VERSION ""

NS_ :

BS_:

BU_: FLC2 DACU

BO_ 788 FLCObject04_Vic2: 48 FLC2
 SG_ FLCObject04_LatVel : 277|13@1+ (0.032,-80) [-80|182.112] "m_per_s"  VCM
 SG_ FLCObject04_LatVelVar : 32|8@1+ (0.1,0) [0|25.5] "NotApplicable"  VCM
 SG_ FLCObject04_CoastIndex : 328|5@1+ (1,0) [0|31] "NotApplicable"  VCM
 SG_ FLCObject04_LifeTime : 64|16@1+ (0.1,0) [0|6553.5] "s"  VCM
 SG_ FLCObject04_DistFarCorner : 176|12@1+ (0.05,0) [0|204.75] "m"  VCM
 SG_ FLCObject04_TurnIndication : 333|3@1+ (1,0) [0|0] ""  VCM
 SG_ FLCObject04_AnglLeftCorner : 209|10@1+ (0.005,-1.57) [-1.57|3.545] "rad"  VCM
 SG_ FLCObject04_CRC : 0|16@1+ (1,0) [0|65535] "NotApplicable"  VCM
 SG_ FLCObject04_LatPos : 264|13@1+ (0.05,-180) [-180|229.55] "m"  VCM
 SG_ FLCObject04_DstRightVar : 80|8@1+ (0.4,0) [0|102] "NotApplicable"  VCM
 SG_ FLCObject04_Height : 96|8@1+ (0.02,0) [0|5.1] "m"  VCM
 SG_ FLCObject04_LongVel : 303|13@1+ (0.032,-80) [-80|182.112] "m_per_s"  VCM
 SG_ FLCObject04_ExistConf : 257|7@1+ (0.01,0) [0|1.27] "NotApplicable"  VCM
 SG_ FLCObject04_DstFarVar : 24|8@1+ (0.4,0) [0|102] "NotApplicable"  VCM
 SG_ FLCObject04_ObjClass : 316|4@1+ (1,0) [0|0] ""  VCM
 SG_ FLCObject04_AngLeftVar : 120|8@1+ (1E-005,0) [0|0.00255] "NotApplicable"  VCM
 SG_ FLCObject04_ScaleChange : 219|10@1+ (0.002,0) [0|2.046] "NotApplicable"  VCM
 SG_ FLCObject04_AnglRightCorner : 199|10@1+ (0.005,-1.57) [-1.57|3.545] "rad"  VCM
 SG_ FLCObject04_LongPosVar : 144|8@1+ (0.4,0) [0|102] "NotApplicable"  VCM
 SG_ FLCObject04_LongAcc : 239|9@1+ (0.08,-20) [-20|20.88] "m_per_s_squared"  VCM
 SG_ FLCObject04_ObjDynClass : 326|2@1+ (1,0) [0|0] ""  VCM
 SG_ FLCObject04_Counter : 16|8@1+ (1,0) [0|255] "Count"  VCM
 SG_ FLCObject04_ObjID : 320|6@1+ (1,0) [0|63] "NotApplicable"  VCM
 SG_ FLCObject04_TrackStatus : 339|3@1+ (1,0) [0|0] ""  VCM
 SG_ FLCObject04_AngRightVar : 136|8@1+ (1E-005,0) [0|0.00255] "NotApplicable"  VCM
 SG_ FLCObject04_DistLeftCorner : 152|12@1+ (0.05,0) [0|204.75] "m"  VCM
 SG_ FLCObject04_Heading : 188|11@1+ (0.005818,-4.71) [-4.71|7.199446] "rad"  VCM
 SG_ FLCObject04_BrakeLight : 345|3@1+ (1,0) [0|0] ""  VCM
 SG_ FLCObject04_DistRightCorner : 164|12@1+ (0.05,0) [0|204.75] "m"  VCM
 SG_ FLCObject04_AnglFarCorner : 229|10@1+ (0.005,-1.57) [-1.57|3.545] "rad"  VCM
 SG_ FLCObject04_AngFarVar : 128|8@1+ (1E-005,0) [0|0.00255] "NotApplicable"  VCM
 SG_ FLCObject04_DstLeftVar : 112|8@1+ (0.4,0) [0|102] "NotApplicable"  VCM
 SG_ FLCObject04_LatAcc : 248|9@1+ (0.08,-20) [-20|20.88] "m_per_s_squared"  VCM
 SG_ FLCObject04_TargetToLine : 342|3@1+ (1,0) [0|0] ""  VCM
 SG_ FLCObject04_LongVelVar : 88|8@1+ (0.4,0) [0|102] "NotApplicable"  VCM
 SG_ FLCObject04_LatPosVar : 40|8@1+ (0.1,0) [0|25.5] "NotApplicable"  VCM
 SG_ FLCObject04_TimeStamp : 48|16@1+ (0.1,0) [0|6553.5] "ms"  VCM
 SG_ FLCObject04_LongPos : 290|13@1+ (0.05,-180) [-180|229.55] "m"  VCM
 SG_ FLCObject04_ReliabilityConf : 336|3@1+ (1,0) [0|0] ""  VCM
 SG_ FLCObject04_HeadingVar : 104|8@1+ (0.1,0) [0|25.5] "NotApplicable"  VCM

BO_ 787 FLCObject03_Vic2: 48 FLC2
 SG_ FLCObject03_Height : 96|8@1+ (0.02,0) [0|5.1] "m"  VCM
 SG_ FLCObject03_LatAcc : 248|9@1+ (0.08,-20) [-20|20.88] "m_per_s_squared"  VCM
 SG_ FLCObject03_LatVelVar : 32|8@1+ (0.1,0) [0|25.5] "NotApplicable"  VCM
 SG_ FLCObject03_TrackStatus : 339|3@1+ (1,0) [0|0] ""  VCM
 SG_ FLCObject03_LifeTime : 64|16@1+ (0.1,0) [0|6553.5] "s"  VCM
 SG_ FLCObject03_AnglFarCorner : 229|10@1+ (0.005,-1.57) [-1.57|3.545] "rad"  VCM
 SG_ FLCObject03_LongAcc : 239|9@1+ (0.08,-20) [-20|20.88] "m_per_s_squared"  VCM
 SG_ FLCObject03_Heading : 188|11@1+ (0.005818,-4.71) [-4.71|7.199446] "rad"  VCM
 SG_ FLCObject03_AngFarVar : 128|8@1+ (1E-005,0) [0|0.00255] "NotApplicable"  VCM
 SG_ FLCObject03_LongPosVar : 144|8@1+ (0.4,0) [0|102] "NotApplicable"  VCM
 SG_ FLCObject03_LatPos : 264|13@1+ (0.05,-180) [-180|229.55] "m"  VCM
 SG_ FLCObject03_ScaleChange : 219|10@1+ (0.002,0) [0|2.046] "NotApplicable"  VCM
 SG_ FLCObject03_LongVelVar : 88|8@1+ (0.4,0) [0|102] "NotApplicable"  VCM
 SG_ FLCObject03_LongVel : 303|13@1+ (0.032,-80) [-80|182.112] "m_per_s"  VCM
 SG_ FLCObject03_DstFarVar : 24|8@1+ (0.4,0) [0|102] "NotApplicable"  VCM
 SG_ FLCObject03_TargetToLine : 342|3@1+ (1,0) [0|0] ""  VCM
 SG_ FLCObject03_CoastIndex : 328|5@1+ (1,0) [0|31] "NotApplicable"  VCM
 SG_ FLCObject03_DstRightVar : 80|8@1+ (0.4,0) [0|102] "NotApplicable"  VCM
 SG_ FLCObject03_ExistConf : 257|7@1+ (0.01,0) [0|1.27] "NotApplicable"  VCM
 SG_ FLCObject03_LongPos : 290|13@1+ (0.05,-180) [-180|229.55] "m"  VCM
 SG_ FLCObject03_AnglRightCorner : 199|10@1+ (0.005,-1.57) [-1.57|3.545] "rad"  VCM
 SG_ FLCObject03_LatVel : 277|13@1+ (0.032,-80) [-80|182.112] "m_per_s"  VCM
 SG_ FLCObject03_ObjClass : 316|4@1+ (1,0) [0|0] ""  VCM
 SG_ FLCObject03_TimeStamp : 48|16@1+ (0.1,0) [0|6553.5] "ms"  VCM
 SG_ FLCObject03_ObjDynClass : 326|2@1+ (1,0) [0|0] ""  VCM
 SG_ FLCObject03_CRC : 0|16@1+ (1,0) [0|65535] "NotApplicable"  VCM
 SG_ FLCObject03_AnglLeftCorner : 209|10@1+ (0.005,-1.57) [-1.57|3.545] "rad"  VCM
 SG_ FLCObject03_ReliabilityConf : 336|3@1+ (1,0) [0|0] ""  VCM
 SG_ FLCObject03_DistLeftCorner : 152|12@1+ (0.05,0) [0|204.75] "m"  VCM
 SG_ FLCObject03_DstLeftVar : 112|8@1+ (0.4,0) [0|102] "NotApplicable"  VCM
 SG_ FLCObject03_DistFarCorner : 176|12@1+ (0.05,0) [0|204.75] "m"  VCM
 SG_ FLCObject03_TurnIndication : 333|3@1+ (1,0) [0|0] ""  VCM
 SG_ FLCObject03_LatPosVar : 40|8@1+ (0.1,0) [0|25.5] "NotApplicable"  VCM
 SG_ FLCObject03_DistRightCorner : 164|12@1+ (0.05,0) [0|204.75] "m"  VCM
 SG_ FLCObject03_ObjID : 320|6@1+ (1,0) [0|63] "NotApplicable"  VCM
 SG_ FLCObject03_AngLeftVar : 120|8@1+ (1E-005,0) [0|0.00255] "NotApplicable"  VCM
 SG_ FLCObject03_BrakeLight : 345|3@1+ (1,0) [0|0] ""  VCM
 SG_ FLCObject03_HeadingVar : 104|8@1+ (0.1,0) [0|25.5] "NotApplicable"  VCM
 SG_ FLCObject03_Counter : 16|8@1+ (1,0) [0|255] "Count"  VCM
 SG_ FLCObject03_AngRightVar : 136|8@1+ (1E-005,0) [0|0.00255] "NotApplicable"  VCM

BO_ 786 FLCObject02_Vic2: 48 FLC2
 SG_ FLCObject02_ScaleChange : 219|10@1+ (0.002,0) [0|2.046] "NotApplicable"  VCM
 SG_ FLCObject02_Height : 96|8@1+ (0.02,0) [0|5.1] "m"  VCM
 SG_ FLCObject02_AnglRightCorner : 199|10@1+ (0.005,-1.57) [-1.57|3.545] "rad"  VCM
 SG_ FLCObject02_AnglFarCorner : 229|10@1+ (0.005,-1.57) [-1.57|3.545] "rad"  VCM
 SG_ FLCObject02_DistRightCorner : 164|12@1+ (0.05,0) [0|204.75] "m"  VCM
 SG_ FLCObject02_LongAcc : 239|9@1+ (0.08,-20) [-20|20.88] "m_per_s_squared"  VCM
 SG_ FLCObject02_AngRightVar : 136|8@1+ (1E-005,0) [0|0.00255] "NotApplicable"  VCM
 SG_ FLCObject02_CRC : 0|16@1+ (1,0) [0|65535] "NotApplicable"  VCM
 SG_ FLCObject02_LatAcc : 248|9@1+ (0.08,-20) [-20|20.88] "m_per_s_squared"  VCM
 SG_ FLCObject02_TrackStatus : 339|3@1+ (1,0) [0|0] ""  VCM
 SG_ FLCObject02_Heading : 188|11@1+ (0.005818,-4.71) [-4.71|7.199446] "rad"  VCM
 SG_ FLCObject02_AnglLeftCorner : 209|10@1+ (0.005,-1.57) [-1.57|3.545] "rad"  VCM
 SG_ FLCObject02_LongVelVar : 88|8@1+ (0.4,0) [0|102] "NotApplicable"  VCM
 SG_ FLCObject02_LatPos : 264|13@1+ (0.05,-180) [-180|229.55] "m"  VCM
 SG_ FLCObject02_LongPosVar : 144|8@1+ (0.4,0) [0|102] "NotApplicable"  VCM
 SG_ FLCObject02_LatVelVar : 32|8@1+ (0.1,0) [0|25.5] "NotApplicable"  VCM
 SG_ FLCObject02_LongVel : 303|13@1+ (0.032,-80) [-80|182.112] "m_per_s"  VCM
 SG_ FLCObject02_ObjDynClass : 326|2@1+ (1,0) [0|0] ""  VCM
 SG_ FLCObject02_TimeStamp : 48|16@1+ (0.1,0) [0|6553.5] "ms"  VCM
 SG_ FLCObject02_DistFarCorner : 176|12@1+ (0.05,0) [0|204.75] "m"  VCM
 SG_ FLCObject02_DstFarVar : 24|8@1+ (0.4,0) [0|102] "NotApplicable"  VCM
 SG_ FLCObject02_LifeTime : 64|16@1+ (0.1,0) [0|6553.5] "s"  VCM
 SG_ FLCObject02_LatVel : 277|13@1+ (0.032,-80) [-80|182.112] "m_per_s"  VCM
 SG_ FLCObject02_ObjID : 320|6@1+ (1,0) [0|63] "NotApplicable"  VCM
 SG_ FLCObject02_ExistConf : 257|7@1+ (0.01,0) [0|1.27] "NotApplicable"  VCM
 SG_ FLCObject02_DstRightVar : 80|8@1+ (0.4,0) [0|102] "NotApplicable"  VCM
 SG_ FLCObject02_ReliabilityConf : 336|3@1+ (1,0) [0|0] ""  VCM
 SG_ FLCObject02_DistLeftCorner : 152|12@1+ (0.05,0) [0|204.75] "m"  VCM
 SG_ FLCObject02_HeadingVar : 104|8@1+ (0.1,0) [0|25.5] "NotApplicable"  VCM
 SG_ FLCObject02_TurnIndication : 333|3@1+ (1,0) [0|0] ""  VCM
 SG_ FLCObject02_ObjClass : 316|4@1+ (1,0) [0|0] ""  VCM
 SG_ FLCObject02_LongPos : 290|13@1+ (0.05,-180) [-180|229.55] "m"  VCM
 SG_ FLCObject02_DstLeftVar : 112|8@1+ (0.4,0) [0|102] "NotApplicable"  VCM
 SG_ FLCObject02_AngLeftVar : 120|8@1+ (1E-005,0) [0|0.00255] "NotApplicable"  VCM
 SG_ FLCObject02_BrakeLight : 345|3@1+ (1,0) [0|0] ""  VCM
 SG_ FLCObject02_LatPosVar : 40|8@1+ (0.1,0) [0|25.5] "NotApplicable"  VCM
 SG_ FLCObject02_CoastIndex : 328|5@1+ (1,0) [0|31] "NotApplicable"  VCM
 SG_ FLCObject02_Counter : 16|8@1+ (1,0) [0|255] "Count"  VCM
 SG_ FLCObject02_TargetToLine : 342|3@1+ (1,0) [0|0] ""  VCM
 SG_ FLCObject02_AngFarVar : 128|8@1+ (1E-005,0) [0|0.00255] "NotApplicable"  VCM

BO_ 785 FLCObject01_Vic2: 48 FLC2
 SG_ FLCObject01_TimeStamp : 48|16@1+ (0.1,0) [0|6553.5] "ms"  VCM
 SG_ FLCObject01_CRC : 0|16@1+ (1,0) [0|65535] "NotApplicable"  VCM
 SG_ FLCObject01_LongVelVar : 88|8@1+ (0.4,0) [0|102] "NotApplicable"  VCM
 SG_ FLCObject01_ObjDynClass : 326|2@1+ (1,0) [0|0] ""  VCM
 SG_ FLCObject01_ScaleChange : 219|10@1+ (0.002,0) [0|2.046] "NotApplicable"  VCM
 SG_ FLCObject01_AnglRightCorner : 199|10@1+ (0.005,-1.57) [-1.57|3.545] "rad"  VCM
 SG_ FLCObject01_ReliabilityConf : 336|3@1+ (1,0) [0|0] ""  VCM
 SG_ FLCObject01_LongAcc : 239|9@1+ (0.08,-20) [-20|20.88] "m_per_s_squared"  VCM
 SG_ FLCObject01_DistLeftCorner : 152|12@1+ (0.05,0) [0|204.75] "m"  VCM
 SG_ FLCObject01_BrakeLight : 345|3@1+ (1,0) [0|0] ""  VCM
 SG_ FLCObject01_DstFarVar : 24|8@1+ (0.4,0) [0|102] "NotApplicable"  VCM
 SG_ FLCObject01_LatVel : 277|13@1+ (0.032,-80) [-80|182.112] "m_per_s"  VCM
 SG_ FLCObject01_LatPos : 264|13@1+ (0.05,-180) [-180|229.55] "m"  VCM
 SG_ FLCObject01_LongPosVar : 144|8@1+ (0.4,0) [0|102] "NotApplicable"  VCM
 SG_ FLCObject01_DstLeftVar : 112|8@1+ (0.4,0) [0|102] "NotApplicable"  VCM
 SG_ FLCObject01_LatPosVar : 40|8@1+ (0.1,0) [0|25.5] "NotApplicable"  VCM
 SG_ FLCObject01_ExistConf : 257|7@1+ (0.01,0) [0|1.27] "NotApplicable"  VCM
 SG_ FLCObject01_Counter : 16|8@1+ (1,0) [0|255] "Count"  VCM
 SG_ FLCObject01_ObjClass : 316|4@1+ (1,0) [0|0] ""  VCM
 SG_ FLCObject01_LongVel : 303|13@1+ (0.032,-80) [-80|182.112] "m_per_s"  VCM
 SG_ FLCObject01_Height : 96|8@1+ (0.02,0) [0|5.1] "m"  VCM
 SG_ FLCObject01_LatVelVar : 32|8@1+ (0.1,0) [0|25.5] "NotApplicable"  VCM
 SG_ FLCObject01_AnglFarCorner : 229|10@1+ (0.005,-1.57) [-1.57|3.545] "rad"  VCM
 SG_ FLCObject01_Heading : 188|11@1+ (0.005818,-4.71) [-4.71|7.199446] "rad"  VCM
 SG_ FLCObject01_LatAcc : 248|9@1+ (0.08,-20) [-20|20.88] "m_per_s_squared"  VCM
 SG_ FLCObject01_LifeTime : 64|16@1+ (0.1,0) [0|6553.5] "s"  VCM
 SG_ FLCObject01_HeadingVar : 104|8@1+ (0.1,0) [0|25.5] "NotApplicable"  VCM
 SG_ FLCObject01_AngLeftVar : 120|8@1+ (1E-005,0) [0|0.00255] "NotApplicable"  VCM
 SG_ FLCObject01_AngFarVar : 128|8@1+ (1E-005,0) [0|0.00255] "NotApplicable"  VCM
 SG_ FLCObject01_CoastIndex : 328|5@1+ (1,0) [0|31] "NotApplicable"  VCM
 SG_ FLCObject01_DistRightCorner : 164|12@1+ (0.05,0) [0|204.75] "m"  VCM
 SG_ FLCObject01_TrackStatus : 339|3@1+ (1,0) [0|0] ""  VCM
 SG_ FLCObject01_LongPos : 290|13@1+ (0.05,-180) [-180|229.55] "m"  VCM
 SG_ FLCObject01_ObjID : 320|6@1+ (1,0) [0|63] "NotApplicable"  VCM
 SG_ FLCObject01_DstRightVar : 80|8@1+ (0.4,0) [0|102] "NotApplicable"  VCM
 SG_ FLCObject01_DistFarCorner : 176|12@1+ (0.05,0) [0|204.75] "m"  VCM
 SG_ FLCObject01_TargetToLine : 342|3@1+ (1,0) [0|0] ""  VCM
 SG_ FLCObject01_TurnIndication : 333|3@1+ (1,0) [0|0] ""  VCM
 SG_ FLCObject01_AngRightVar : 136|8@1+ (1E-005,0) [0|0.00255] "NotApplicable"  VCM
 SG_ FLCObject01_AnglLeftCorner : 209|10@1+ (0.005,-1.57) [-1.57|3.545] "rad"  VCM

BO_ 784 FLCObject00_Vic2: 48 FLC2
 SG_ FLCObject00_LifeTime : 64|16@1+ (0.1,0) [0|6553.5] "s"  VCM
 SG_ FLCObject00_BrakeLight : 345|3@1+ (1,0) [0|0] ""  VCM
 SG_ FLCObject00_AnglLeftCorner : 209|10@1+ (0.005,-1.57) [-1.57|3.545] "rad"  VCM
 SG_ FLCObject00_DistRightCorner : 164|12@1+ (0.05,0) [0|204.75] "m"  VCM
 SG_ FLCObject00_LatPos : 264|13@1+ (0.05,-180) [-180|229.55] "m"  VCM
 SG_ FLCObject00_TimeStamp : 48|16@1+ (0.1,0) [0|6553.5] "ms"  VCM
 SG_ FLCObject00_LatAcc : 248|9@1+ (0.08,-20) [-20|20.88] "m_per_s_squared"  VCM
 SG_ FLCObject00_LatVel : 277|13@1+ (0.032,-80) [-80|182.112] "m_per_s"  VCM
 SG_ FLCObject00_ExistConf : 257|7@1+ (0.01,0) [0|1.27] "NotApplicable"  VCM
 SG_ FLCObject00_AngRightVar : 136|8@1+ (1E-005,0) [0|0.00255] "NotApplicable"  VCM
 SG_ FLCObject00_AnglRightCorner : 199|10@1+ (0.005,-1.57) [-1.57|3.545] "rad"  VCM
 SG_ FLCObject00_LatPosVar : 40|8@1+ (0.1,0) [0|25.5] "NotApplicable"  VCM
 SG_ FLCObject00_DistLeftCorner : 152|12@1+ (0.05,0) [0|204.75] "m"  VCM
 SG_ FLCObject00_CoastIndex : 328|5@1+ (1,0) [0|31] "NotApplicable"  VCM
 SG_ FLCObject00_TrackStatus : 339|3@1+ (1,0) [0|0] ""  VCM
 SG_ FLCObject00_ScaleChange : 219|10@1+ (0.002,0) [0|2.046] "NotApplicable"  VCM
 SG_ FLCObject00_LatVelVar : 32|8@1+ (0.1,0) [0|25.5] "NotApplicable"  VCM
 SG_ FLCObject00_HeadingVar : 104|8@1+ (0.1,0) [0|25.5] "NotApplicable"  VCM
 SG_ FLCObject00_LongPosVar : 144|8@1+ (0.4,0) [0|102] "NotApplicable"  VCM
 SG_ FLCObject00_DstLeftVar : 112|8@1+ (0.4,0) [0|102] "NotApplicable"  VCM
 SG_ FLCObject00_ObjID : 320|6@1+ (1,0) [0|63] "NotApplicable"  VCM
 SG_ FLCObject00_ObjClass : 316|4@1+ (1,0) [0|0] ""  VCM
 SG_ FLCObject00_AnglFarCorner : 229|10@1+ (0.005,-1.57) [-1.57|3.545] "rad"  VCM
 SG_ FLCObject00_DstFarVar : 24|8@1+ (0.4,0) [0|102] "NotApplicable"  VCM
 SG_ FLCObject00_LongVel : 303|13@1+ (0.032,-80) [-80|182.112] "m_per_s"  VCM
 SG_ FLCObject00_LongPos : 290|13@1+ (0.05,-180) [-180|229.55] "m"  VCM
 SG_ FLCObject00_AngLeftVar : 120|8@1+ (1E-005,0) [0|0.00255] "NotApplicable"  VCM
 SG_ FLCObject00_ReliabilityConf : 336|3@1+ (1,0) [0|0] ""  VCM
 SG_ FLCObject00_Counter : 16|8@1+ (1,0) [0|255] "Count"  VCM
 SG_ FLCObject00_ObjDynClass : 326|2@1+ (1,0) [0|0] ""  VCM
 SG_ FLCObject00_TargetToLine : 342|3@1+ (1,0) [0|0] ""  VCM
 SG_ FLCObject00_DstRightVar : 80|8@1+ (0.4,0) [0|102] "NotApplicable"  VCM
 SG_ FLCObject00_TurnIndication : 333|3@1+ (1,0) [0|0] ""  VCM
 SG_ FLCObject00_AngFarVar : 128|8@1+ (1E-005,0) [0|0.00255] "NotApplicable"  VCM
 SG_ FLCObject00_Heading : 188|11@1+ (0.005818,-4.71) [-4.71|7.199446] "rad"  VCM
 SG_ FLCObject00_DistFarCorner : 176|12@1+ (0.05,0) [0|204.75] "m"  VCM
 SG_ FLCObject00_LongAcc : 239|9@1+ (0.08,-20) [-20|20.88] "m_per_s_squared"  VCM
 SG_ FLCObject00_Height : 96|8@1+ (0.02,0) [0|5.1] "m"  VCM
 SG_ FLCObject00_LongVelVar : 88|8@1+ (0.4,0) [0|102] "NotApplicable"  VCM
 SG_ FLCObject00_CRC : 0|16@1+ (1,0) [0|65535] "NotApplicable"  VCM

BO_ 2671964753 DiagUUDTRespMsg1_F2_51_Vic2: 8 FLC2
 SG_ DiagUUDTRespSig_F2_51 : 0|64@1+ (1,0) [0|0] ""  VCM

BO_ 2671834193 DiagRespMsgIntTGW2_F4_51_Vic2: 8 FLC2
 SG_ InternalTesterDiagSig_F4_51 : 0|64@1+ (1,0) [0|0] ""  VCM

BO_ 2671833937 DiagRespMsgIntHMIIOM_F3_51_Vic2: 8 FLC2
 SG_ InternalTesterDiagSig_F3_51 : 0|64@1+ (1,0) [0|0] ""  VCM

BO_ 2671792628 DiagReqMsgIntTGW2_51_F4_Vic2: 8 DACU
 SG_ InternalTesterDiagSig_51_F4 : 0|64@1+ (1,0) [0|0] ""  FLC2

BO_ 2671792627 DiagReqMsgIntHMIIOM_51_F3_Vic2: 8 DACU
 SG_ InternalTesterDiagSig_51_F3 : 0|64@1+ (1,0) [0|0] ""  FLC2

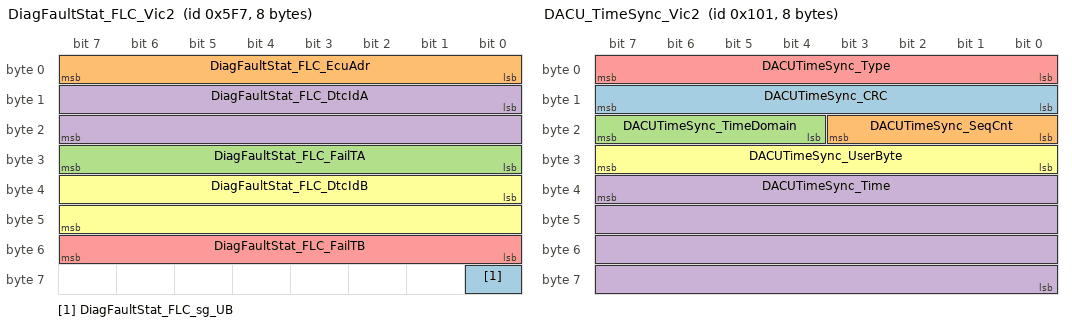
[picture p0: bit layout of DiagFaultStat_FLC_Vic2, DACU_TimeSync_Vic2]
BO_ 1527 DiagFaultStat_FLC_Vic2: 8 FLC2
 SG_ DiagFaultStat_FLC_sg_UB : 56|1@1+ (1,0) [0|0] ""  VCM
 SG_ DiagFaultStat_FLC_EcuAdr : 0|8@1+ (1,0) [0|255] ""  VCM
 SG_ DiagFaultStat_FLC_FailTA : 24|8@1+ (1,0) [0|255] ""  VCM
 SG_ DiagFaultStat_FLC_DtcIdA : 8|16@1+ (1,0) [0|65535] ""  VCM
 SG_ DiagFaultStat_FLC_FailTB : 48|8@1+ (1,0) [0|255] ""  VCM
 SG_ DiagFaultStat_FLC_DtcIdB : 32|16@1+ (1,0) [0|65535] ""  VCM

BO_ 257 DACU_TimeSync_Vic2: 8 DACU
 SG_ DACUTimeSync_CRC : 15|8@0+ (1,0) [0|0] ""  FLC2
 SG_ DACUTimeSync_SeqCnt : 19|4@0+ (1,0) [0|15] "Count"  FLC2
 SG_ DACUTimeSync_TimeDomain : 23|4@0+ (1,0) [0|15] "Count"  FLC2
 SG_ DACUTimeSync_Time : 39|32@0+ (1,0) [0|0] ""  FLC2
 SG_ DACUTimeSync_Type : 7|8@0+ (1,0) [0|0] ""  FLC2
 SG_ DACUTimeSync_UserByte : 31|8@0+ (1,0) [0|0] ""  FLC2

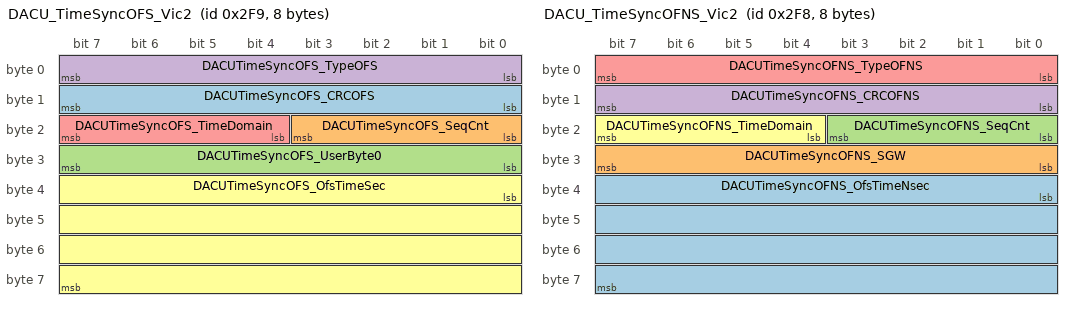
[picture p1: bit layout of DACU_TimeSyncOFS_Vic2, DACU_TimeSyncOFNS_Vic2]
BO_ 761 DACU_TimeSyncOFS_Vic2: 8 DACU
 SG_ DACUTimeSyncOFS_CRCOFS : 8|8@1+ (1,0) [0|0] ""  FLC2
 SG_ DACUTimeSyncOFS_SeqCnt : 16|4@1+ (1,0) [0|15] "Count"  FLC2
 SG_ DACUTimeSyncOFS_UserByte0 : 24|8@1+ (1,0) [0|0] ""  FLC2
 SG_ DACUTimeSyncOFS_TypeOFS : 0|8@1+ (1,0) [0|0] ""  FLC2
 SG_ DACUTimeSyncOFS_TimeDomain : 20|4@1+ (1,16) [16|31] "NotApplicable"  FLC2
 SG_ DACUTimeSyncOFS_OfsTimeSec : 32|32@1+ (1,0) [0|0] ""  FLC2

BO_ 760 DACU_TimeSyncOFNS_Vic2: 8 DACU
 SG_ DACUTimeSyncOFNS_OfsTimeNsec : 32|32@1+ (1,0) [0|0] ""  FLC2
 SG_ DACUTimeSyncOFNS_SGW : 24|8@1+ (1,0) [0|0] ""  FLC2
 SG_ DACUTimeSyncOFNS_SeqCnt : 16|4@1+ (1,0) [0|15] "Count"  FLC2
 SG_ DACUTimeSyncOFNS_CRCOFNS : 8|8@1+ (1,0) [0|0] ""  FLC2
 SG_ DACUTimeSyncOFNS_TypeOFNS : 0|8@1+ (1,0) [0|0] ""  FLC2
 SG_ DACUTimeSyncOFNS_TimeDomain : 20|4@1+ (1,16) [16|31] "NotApplicable"  FLC2

BO_ 281 DACU_ShadowArea_Vic2: 12 DACU
 SG_ ShadowArea_LeftAgl03 : 11|11@1+ (0.0494,-31.65) [-31.65|69.4718] "deg"  FLC2
 SG_ ShadowArea_RightAgl02 : 0|11@1+ (0.0494,-31.65) [-31.65|69.4718] "deg"  FLC2
 SG_ ShadowArea_RightAgl01 : 55|11@1+ (0.0494,-31.65) [-31.65|69.4718] "deg"  FLC2
 SG_ ShadowArea_LeftAgl02 : 22|11@1+ (0.0494,-31.65) [-31.65|69.4718] "deg"  FLC2
 SG_ ShadowArea_Dist03 : 86|10@1+ (0.5,0) [0|511.5] "m"  FLC2
 SG_ ShadowArea_Dist01 : 66|10@1+ (0.5,0) [0|511.5] "m"  FLC2
 SG_ ShadowArea_LeftAgl01 : 33|11@1+ (0.0494,-31.65) [-31.65|69.4718] "deg"  FLC2
 SG_ ShadowArea_Dist02 : 76|10@1+ (0.5,0) [0|511.5] "m"  FLC2
 SG_ ShadowArea_RightAgl03 : 44|11@1+ (0.0494,-31.65) [-31.65|69.4718] "deg"  FLC2

BO_ 854 DACU_GPSData_Vic2: 24 DACU
 SG_ GPSData_Time : 64|32@1+ (1,0) [0|4294967295] "s"  FLC2
 SG_ GPSData_AntennaStat : 160|3@1+ (1,0) [0|0] ""  FLC2
 SG_ GPSData_Longitude : 0|32@1+ (1E-007,-210) [-210|219.4967295] "deg"  FLC2
 SG_ GPSData_VehSpeed : 128|16@1+ (0.00390625,0) [0|255.99609375] "Km_per_h"  FLC2
 SG_ GPSData_Direction : 96|16@1+ (0.0078125,0) [0|511.9921875] "deg"  FLC2
 SG_ GPSData_sg_UB : 163|1@1+ (1,0) [0|1] ""  FLC2
 SG_ GPSData_Latitude : 32|32@1+ (1E-007,-210) [-210|219.4967295] "deg"  FLC2
 SG_ GPSData_HDOP : 112|16@1+ (0.01,0) [0|655.35] ""  FLC2
 SG_ GPSData_Altitude : 144|16@1+ (0.125,-2500) [-2500|5691.875] "m"  FLC2

BO_ 279 DACU_EgoPathPrediction_Vic2: 16 DACU
 SG_ EgoPathPrediction_ConfCoeffA3 : 56|16@1+ (0.001,-30) [-30|35.535] "NotApplicable"  FLC2
 SG_ EgoPathPrediction_CurvatureRate : 85|11@1+ (5.1E-007,-0.000516) [-0.000516|0.00052797] "per_meter_squared"  FLC2
 SG_ EgoPathPrediction_DxEnd : 0|8@1+ (1,-126) [-126|129] "m"  FLC2
 SG_ EgoPathPrediction_HeadingAngle : 72|13@1+ (0.0005,-1.57) [-1.57|2.5255] "rad"  FLC2
 SG_ EgoPathPrediction_ConfCoeffA1 : 40|16@1+ (0.001,-30) [-30|35.535] "NotApplicable"  FLC2
 SG_ EgoPathPrediction_ConfCoeffA0 : 8|16@1+ (0.001,-30) [-30|35.535] "NotApplicable"  FLC2
 SG_ EgoPathPrediction_ConfCoeffA2 : 24|16@1+ (0.001,-30) [-30|35.535] "NotApplicable"  FLC2
 SG_ EgoPathPrediction_Curvature : 96|18@1+ (1E-006,-0.1310705) [-0.1310705|0.1310725] "per_meter"  FLC2

BO_ 275 DACU_EgoMotion_Vic2: 32 DACU
 SG_ VehicleMode_UB : 252|1@1+ (1,0) [0|0] ""  FLC2
 SG_ EgoMotionXYplane_LongSpeedVar : 72|16@1+ (0.00115384616,0) [0|75.6173080956] "NotApplicable"  FLC2
 SG_ EgoMotionXYplane_LongAccVariance : 184|6@1+ (0.1,0) [0|6.3] "NotApplicable"  FLC2
 SG_ EgoMotionXYplane_LongMotionDir : 221|3@1+ (1,0) [0|0] ""  FLC2
 SG_ EgoMotionXYplane_Curvature : 200|21@1+ (1E-006,-1.0486) [-1.0486|1.048551] "per_meter"  FLC2
 SG_ EgoMotionXYplane_LongAcc : 24|16@1+ (0.00048828125,-15.687) [-15.687|16.31251171875] "m_per_s_squared"  FLC2
 SG_ EgoMotionXYplane_LatAccVariance : 194|6@1+ (0.1,0) [0|6.3] "NotApplicable"  FLC2
 SG_ EgoMotionXYplane_YawRateVariance : 120|16@1+ (3.846154E-005,0) [0|2.5205770239] "NotApplicable"  FLC2
 SG_ EgoMotionXYplane_LongMotDirConf : 190|4@1+ (1,0) [0|0] ""  FLC2
 SG_ EgoMotionXYplane_YawRateComp : 136|16@1+ (0.000122,-3.92) [-3.92|4.07527] "Rad_per_s"  FLC2
 SG_ EgoMotionXYplane_ReferencePointX : 40|16@1+ (0.001,-32) [-32|33.535] "m"  FLC2
 SG_ EgoMotionXYplane_LateralSpeed : 152|16@1+ (0.00108507,-35) [-35|36.11006245] "m_per_s"  FLC2
 SG_ EgoMotionXYplane_LateralAcc : 56|16@1+ (0.00048828125,-15.687) [-15.687|16.31251171875] "m_per_s_squared"  FLC2
 SG_ EgoMotionXYplane_CRC : 0|16@1+ (1,0) [0|65535] "NotApplicable"  FLC2
 SG_ EgoMotionXYplane_LongSpeed : 104|16@1+ (0.00108507,0) [0|71.11006245] "m_per_s"  FLC2
 SG_ EgoMotionXYplane_LatSpeedVar : 88|16@1+ (0.00153846154,0) [0|100.8230770239] "NotApplicable"  FLC2
 SG_ EgoMotionXYplane_LatencyEst : 176|8@1+ (1,0) [0|255] "ms"  FLC2
 SG_ EgoMotionXYplane_ChassisDynPitch : 168|8@1+ (0.001,-0.126) [-0.126|0.129] "rad"  FLC2
 SG_ VehicleMode : 248|4@1+ (1,0) [0|0] ""  FLC2
 SG_ EgoMotionXYplane_Counter : 16|8@1+ (1,0) [0|255] "Count"  FLC2
 SG_ EgoMotionXYplane_EffectiveWheelB : 224|10@1+ (10,2000) [2000|12230] "mm"  FLC2

BO_ 277 DACU_EgoMotionRaw_Vic2: 32 DACU
 SG_ EgoMotionRaw_RelLvlRrAxleRight : 176|16@1+ (0.1,-3200) [-3200|3353.5] "mm"  FLC2
 SG_ EgoMotionRaw_FrAxleLeftWSpeed : 24|16@1+ (0.00390625,0) [0|255.99609375] "Km_per_h"  FLC2
 SG_ EgoMotionRaw_GrossCombVehWeight : 224|16@1+ (10,0) [0|655350] "kg"  FLC2
 SG_ EgoMotionRaw_FrontWheelAngle : 56|16@1+ (5E-005,-1.6) [-1.6|1.67675] "rad"  FLC2
 SG_ EgoMotionRaw_BrakePedalPosition : 120|8@1+ (0.4,0) [0|102] "Percent"  FLC2
 SG_ EgoMotionRaw_SteeringWheelAngle : 104|16@1+ (0.0009765625,-31.374) [-31.374|32.6250234375] "rad"  FLC2
 SG_ EgoMotionRaw_SteeringWheelRatio : 136|6@1+ (1,0) [0|63] "NotApplicable"  FLC2
 SG_ EgoMotionRaw_FrAxleRightWSpeed : 40|16@1+ (0.00390625,0) [0|255.99609375] "Km_per_h"  FLC2
 SG_ EgoMotionRaw_ROPEngineActive : 148|2@1+ (1,0) [0|0] ""  FLC2
 SG_ EgoMotionRaw_AccKckDwn : 158|2@1+ (1,0) [0|0] ""  FLC2
 SG_ EgoMotionRaw_RelLvlFrAxleLeft : 192|16@1+ (0.1,-3200) [-3200|3353.5] "mm"  FLC2
 SG_ EgoMotionRaw_ABSActive : 144|2@1+ (1,0) [0|0] ""  FLC2
 SG_ EgoMotionRaw_AccPedalPos : 128|8@1+ (0.4,0) [0|102] "Percent"  FLC2
 SG_ EgoMotionRaw_YCEngineActive : 142|2@1+ (1,0) [0|0] ""  FLC2
 SG_ EgoMotionRaw_RAxleRightWSpeed : 88|16@1+ (0.00390625,0) [0|255.99609375] "Km_per_h"  FLC2
 SG_ EgoMotionRaw_ASRBrakeA : 156|2@1+ (1,0) [0|0] ""  FLC2
 SG_ EgoMotionRaw_RelLvlFrAxleRight : 208|16@1+ (0.1,-3200) [-3200|3353.5] "mm"  FLC2
 SG_ EgoMotionRaw_VDCFullyOperational : 146|2@1+ (1,0) [0|0] ""  FLC2
 SG_ EgoMotionRaw_TrailerConStatus : 240|4@1+ (1,0) [0|0] ""  FLC2
 SG_ EgoMotionRaw_YCBrakeActive : 154|2@1+ (1,0) [0|0] ""  FLC2
 SG_ EgoMotionRaw_ASREngineA : 152|2@1+ (1,0) [0|0] ""  FLC2
 SG_ EgoMotionRaw_RelLvlRrAxleLeft : 160|16@1+ (0.1,-3200) [-3200|3353.5] "mm"  FLC2
 SG_ EgoMotionRaw_Counter : 16|8@1+ (1,0) [0|255] "Count"  FLC2
 SG_ EgoMotionRaw_ROPBrakeActive : 150|2@1+ (1,0) [0|0] ""  FLC2
 SG_ EgoMotionRaw_CRC : 0|16@1+ (1,0) [0|65535] "NotApplicable"  FLC2
 SG_ EgoMotionRaw_RAxleLeftWSpeed : 72|16@1+ (0.00390625,0) [0|255.99609375] "Km_per_h"  FLC2
 SG_ EgoMotionRaw_ABSOp : 244|2@1+ (1,0) [0|0] ""  FLC2

BO_ 1543 DACU_04P_Vic2: 24 DACU
 SG_ VIN_DACU_Byte08 : 64|8@1+ (1,0) [0|0] ""  FLC2
 SG_ VIN_DACU_Byte01 : 8|8@1+ (1,0) [0|0] ""  FLC2
 SG_ VIN_DACU_Byte13 : 104|8@1+ (1,0) [0|0] ""  FLC2
 SG_ CountryCodeLocal_Code : 160|16@1+ (1,0) [0|65535] "NotApplicable"  FLC2
 SG_ VIN_DACU_Byte06 : 48|8@1+ (1,0) [0|0] ""  FLC2
 SG_ VIN_DACU_Byte03 : 24|8@1+ (1,0) [0|0] ""  FLC2
 SG_ VIN_DACU_Byte15 : 120|8@1+ (1,0) [0|0] ""  FLC2
 SG_ VIN_DACU_Byte16 : 128|8@1+ (1,0) [0|0] ""  FLC2
 SG_ CountryCodeLocal_Counter : 152|8@1+ (1,0) [0|255] "Count"  FLC2
 SG_ VIN_DACU_Byte09 : 72|8@1+ (1,0) [0|0] ""  FLC2
 SG_ VIN_DACU_Byte04 : 32|8@1+ (1,0) [0|0] ""  FLC2
 SG_ CountryCodeLocal_CRC : 136|16@1+ (1,0) [0|65535] "NotApplicable"  FLC2
 SG_ VIN_DACU_Byte02 : 16|8@1+ (1,0) [0|0] ""  FLC2
 SG_ VIN_DACU_Byte14 : 112|8@1+ (1,0) [0|0] ""  FLC2
 SG_ VIN_DACU_Byte12 : 96|8@1+ (1,0) [0|0] ""  FLC2
 SG_ VIN_DACU_Byte10 : 80|8@1+ (1,0) [0|0] ""  FLC2
 SG_ VIN_DACU_Byte11 : 88|8@1+ (1,0) [0|0] ""  FLC2
 SG_ RegionCode : 176|3@1+ (1,0) [0|0] ""  FLC2
 SG_ VIN_DACU_Byte00 : 0|8@1+ (1,0) [0|0] ""  FLC2
 SG_ VIN_DACU_Byte07 : 56|8@1+ (1,0) [0|0] ""  FLC2
 SG_ VIN_DACU_Byte05 : 40|8@1+ (1,0) [0|0] ""  FLC2

BO_ 1265 DACU_03P_Vic2: 20 DACU
 SG_ VideoOutConfFLC_StreamActivation : 138|2@1+ (1,0) [0|0] ""  FLC2
 SG_ MainBeamRequest_status : 116|2@1+ (1,0) [0|0] ""  FLC2
 SG_ HoursUTC : 64|8@1+ (1,0) [0|255] "h"  FLC2
 SG_ YearUTC : 88|8@1+ (1,1985) [1985|2240] "Years"  FLC2
 SG_ TimeSynchStat_DACU : 152|8@1+ (1,0) [0|0] ""  FLC2
 SG_ MinutesUTC : 56|8@1+ (1,0) [0|255] "min"  FLC2
 SG_ TachographLocalHourOffset : 104|8@1+ (1,-125) [-125|130] "h"  FLC2
 SG_ CameraLoggingTrigger : 140|3@1+ (1,0) [0|0] ""  FLC2
 SG_ DriverRetarderRequest : 125|3@1+ (1,0) [0|0] ""  FLC2
 SG_ LaneChangeStatus : 112|4@1+ (1,0) [0|0] ""  FLC2
 SG_ FogLight_Front_cmd : 118|2@1+ (1,0) [0|0] ""  FLC2
 SG_ TrailerConnected : 120|2@1+ (1,0) [0|0] ""  FLC2
 SG_ MonthUTC : 80|8@1+ (1,0) [0|255] "Months"  FLC2
 SG_ AmbientAirTemperature : 32|16@1+ (0.03125,-273) [-273|1774.96875] "DegreeC"  FLC2
 SG_ SecondsUTC : 48|8@1+ (0.25,0) [0|63.75] "s"  FLC2
 SG_ DayUTC : 72|8@1+ (0.25,0) [0|63.75] "Days"  FLC2
 SG_ VideoOutConfFLC_Framerate : 134|4@1+ (1,0) [0|0] ""  FLC2
 SG_ TotalVehicleDistanceHighRes : 0|32@1+ (5,0) [0|21474836475] "m"  FLC2
 SG_ WiperModeStatus : 122|3@1+ (1,0) [0|0] ""  FLC2
 SG_ TachographLocalMinuteOffset : 96|8@1+ (1,-125) [-125|130] "min"  FLC2
 SG_ FLCPowerDemand : 131|3@1+ (1,0) [0|0] ""  FLC2

BO_ 1552 DACUSwVersion_Vic2: 64 DACU
 SG_ DACUSwVersion_Substring4 : 256|64@1+ (1,0) [0|0] ""  FLC2
 SG_ DACUSwVersion_Substring5 : 320|64@1+ (1,0) [0|0] ""  FLC2
 SG_ DACUSwVersion_Substring2 : 128|64@1+ (1,0) [0|0] ""  FLC2
 SG_ DACUSwVersion_Substring7 : 448|64@1+ (1,0) [0|0] ""  FLC2
 SG_ DACUSwVersion_Substring6 : 384|64@1+ (1,0) [0|0] ""  FLC2
 SG_ DACUSwVersion_Substring3 : 192|64@1+ (1,0) [0|0] ""  FLC2
 SG_ DACUSwVersion_Substring1 : 64|64@1+ (1,0) [0|0] ""  FLC2
 SG_ DACUSwVersion_Substring0 : 0|64@1+ (1,0) [0|0] ""  FLC2

BO_ 597 AdasisMapData_Vic2: 8 DACU
 SG_ AdasisMapData : 7|64@0+ (1,0) [0|0] ""  FLC2

CM_ SG_ 854 GPSData_Time "4261412864 - 4278190079 Error ; 4278190080 - 4294967295 Not available";
CM_ SG_ 854 GPSData_Longitude "4261412864-4278190079 Error ; 4278190080-4294967295 Not available";
CM_ SG_ 854 GPSData_VehSpeed "65024 - 65279 Error ; 65280 - 65535 Not available";
CM_ SG_ 854 GPSData_Latitude "4261412864-4278190079 Error ; 4278190080-4294967295 Not available";
CM_ BO_ 275 "Default 20 msec. TriggeredBy Application";
CM_ BO_ 277 "Default 20 msec. TriggeredBy Application";
CM_ SG_ 1265 HoursUTC "254 Error ; 255 Not available";
CM_ SG_ 1265 YearUTC "254 Error ; 255 Not available";
CM_ SG_ 1265 MinutesUTC "254 Error ; 255 Not available";
CM_ SG_ 1265 TachographLocalHourOffset "254 Error ; 255 Not available";
CM_ SG_ 1265 MonthUTC "254 Error ; 255 Not available";
CM_ SG_ 1265 AmbientAirTemperature "65024 - 65279 Error ; 65280 - 65535 Not available";
CM_ SG_ 1265 SecondsUTC "254 Error ; 255 Not available";
CM_ SG_ 1265 DayUTC "254 Error ; 255 Not available";
CM_ SG_ 1265 TotalVehicleDistanceHighRes "4261412864 - 4278190079 Error ; 4278190080 - 4294967295 Not available";
CM_ SG_ 1265 TachographLocalMinuteOffset "254 Error ; 255 Not available";
BA_DEF_ BO_  "GenMsgStartDelayTime" INT 0 0;
BA_DEF_ BO_  "GenMsgDelayTime" INT 0 0;
BA_DEF_ BO_  "GenMsgCycleTime" INT 0 0;
BA_DEF_ BO_  "GenMsgSendType" ENUM  "Cyclic","NotUsed","NotUsed","NotUsed","NotUsed","NotUsed","NotUsed","IfActive","NoMsgSendType","NotUsed";
BA_DEF_ SG_  "GenSigStartValue" INT 0 0;
BA_DEF_ SG_  "GenSigCycleTimeActive" INT 0 0;
BA_DEF_ SG_  "GenSigCycleTime" INT 0 0;
BA_DEF_ SG_  "GenSigSendType" ENUM  "Cyclic","OnWrite","OnWriteWithRepetition","OnChange","OnChangeWithRepetition","IfActive","IfActiveWithRepetition","NoSigSendType","NotUsed","NotUsed","NotUsed","NotUsed","NotUsed";
BA_DEF_ BO_  "VFrameFormat" ENUM  "StandardCAN","ExtendedCAN","reserved","J1939PG","reserved","reserved","reserved","reserved","reserved","reserved","reserved","reserved","reserved","reserved","StandardCAN_FD","ExtendedCAN_FD";
BA_DEF_ SG_  "SigType" ENUM  "Default","Range","RangeSigned","ASCII","Discrete","Control","ReferencePGN","DTC","StringDelimiter","StringLength","StringLengthControl";
BA_DEF_ SG_  "SeToolVersion_SIGNAL" STRING ;
BA_DEF_ SG_  "SeToolUniqueID_SIGNAL" STRING ;
BA_DEF_ SG_  "SeToolName_SIGNAL" STRING ;
BA_DEF_ SG_  "SeToolItemID_SIGNAL" STRING ;
BA_DEF_ SG_  "SeToolAncestorID_SIGNAL" STRING ;
BA_DEF_ SG_  "NeedsUpdateBit" ENUM  "No","Yes";
BA_DEF_ SG_  "GenSigILSupport" ENUM  "Yes","No";
BA_DEF_ BO_  "GenMsgILSupport" ENUM  "No","Yes";
BA_DEF_ SG_  "E2EProfile" STRING ;
BA_DEF_ SG_  "E2EDataLength" INT 0 65535;
BA_DEF_ SG_  "E2EDataId" INT 0 65535;
BA_DEF_ BO_  "DiagUUDTResponse" ENUM  "No","Yes";
BA_DEF_ BO_  "DiagState" ENUM  "No","Yes";
BA_DEF_ BO_  "DiagResponse" ENUM  "No","Yes";
BA_DEF_ BO_  "DiagRequest" ENUM  "No","Yes";
BA_DEF_ BO_  "DiagConnection" HEX 0 65535;
BA_DEF_ BO_  "CanTpFcFrameId" HEX 0 2147483647;
BA_DEF_ BO_  "CanTpBs" INT 0 255;
BA_DEF_ BO_  "CANFD_BRS" ENUM  "0","1";
BA_DEF_REL_ BU_SG_REL_  "GenSigTimeoutTime" INT 0 65535;
BA_DEF_REL_ BU_SG_REL_  "GenSigFirstTimeoutTime" INT 0 65535;
BA_DEF_DEF_  "GenMsgStartDelayTime" 0;
BA_DEF_DEF_  "GenMsgDelayTime" 0;
BA_DEF_DEF_  "GenMsgCycleTime" 0;
BA_DEF_DEF_  "GenMsgSendType" "Cyclic";
BA_DEF_DEF_  "GenSigStartValue" 0;
BA_DEF_DEF_  "GenSigCycleTimeActive" 0;
BA_DEF_DEF_  "GenSigCycleTime" 0;
BA_DEF_DEF_  "GenSigSendType" "Cyclic";
BA_DEF_DEF_  "VFrameFormat" "ExtendedCAN";
BA_DEF_DEF_  "SigType" "Default";
BA_DEF_DEF_  "SeToolVersion_SIGNAL" "";
BA_DEF_DEF_  "SeToolUniqueID_SIGNAL" "";
BA_DEF_DEF_  "SeToolName_SIGNAL" "";
BA_DEF_DEF_  "SeToolItemID_SIGNAL" "";
BA_DEF_DEF_  "SeToolAncestorID_SIGNAL" "";
BA_DEF_DEF_  "NeedsUpdateBit" "No";
BA_DEF_DEF_  "GenSigILSupport" "Yes";
BA_DEF_DEF_  "GenMsgILSupport" "Yes";
BA_DEF_DEF_  "E2EProfile" "none";
BA_DEF_DEF_  "E2EDataLength" 0;
BA_DEF_DEF_  "E2EDataId" 0;
BA_DEF_DEF_  "DiagUUDTResponse" "No";
BA_DEF_DEF_  "DiagState" "No";
BA_DEF_DEF_  "DiagResponse" "No";
BA_DEF_DEF_  "DiagRequest" "No";
BA_DEF_DEF_  "DiagConnection" 0;
BA_DEF_DEF_  "CanTpFcFrameId" 2147483647;
BA_DEF_DEF_  "CanTpBs" 255;
BA_DEF_DEF_  "CANFD_BRS" "0";
BA_DEF_DEF_REL_ "GenSigTimeoutTime" 0;
BA_DEF_DEF_REL_ "GenSigFirstTimeoutTime" 0;
BA_ "CANFD_BRS" BO_ 788 1;
BA_ "GenMsgSendType" BO_ 788 8;
BA_ "VFrameFormat" BO_ 788 14;
BA_ "CANFD_BRS" BO_ 787 1;
BA_ "GenMsgSendType" BO_ 787 8;
BA_ "VFrameFormat" BO_ 787 14;
BA_ "CANFD_BRS" BO_ 786 1;
BA_ "GenMsgSendType" BO_ 786 8;
BA_ "VFrameFormat" BO_ 786 14;
BA_ "CANFD_BRS" BO_ 785 1;
BA_ "GenMsgSendType" BO_ 785 8;
BA_ "VFrameFormat" BO_ 785 14;
BA_ "CANFD_BRS" BO_ 784 1;
BA_ "GenMsgSendType" BO_ 784 8;
BA_ "VFrameFormat" BO_ 784 14;
BA_ "DiagConnection" BO_ 2671964753 62033;
BA_ "DiagUUDTResponse" BO_ 2671964753 1;
BA_ "GenMsgILSupport" BO_ 2671964753 0;
BA_ "GenMsgSendType" BO_ 2671964753 8;
BA_ "DiagConnection" BO_ 2671834193 62545;
BA_ "DiagResponse" BO_ 2671834193 1;
BA_ "GenMsgILSupport" BO_ 2671834193 0;
BA_ "GenMsgSendType" BO_ 2671834193 8;
BA_ "DiagConnection" BO_ 2671833937 62289;
BA_ "DiagResponse" BO_ 2671833937 1;
BA_ "GenMsgILSupport" BO_ 2671833937 0;
BA_ "GenMsgSendType" BO_ 2671833937 8;
BA_ "DiagConnection" BO_ 2671792628 62545;
BA_ "DiagRequest" BO_ 2671792628 1;
BA_ "GenMsgILSupport" BO_ 2671792628 0;
BA_ "GenMsgSendType" BO_ 2671792628 8;
BA_ "DiagConnection" BO_ 2671792627 62289;
BA_ "DiagRequest" BO_ 2671792627 1;
BA_ "GenMsgILSupport" BO_ 2671792627 0;
BA_ "GenMsgSendType" BO_ 2671792627 8;
BA_ "CANFD_BRS" BO_ 1527 1;
BA_ "GenMsgCycleTime" BO_ 1527 1000;
BA_ "GenMsgDelayTime" BO_ 1527 80;
BA_ "VFrameFormat" BO_ 1527 14;
BA_ "CANFD_BRS" BO_ 257 1;
BA_ "GenMsgSendType" BO_ 257 8;
BA_ "VFrameFormat" BO_ 257 14;
BA_ "CANFD_BRS" BO_ 761 1;
BA_ "GenMsgSendType" BO_ 761 8;
BA_ "VFrameFormat" BO_ 761 14;
BA_ "CANFD_BRS" BO_ 760 1;
BA_ "GenMsgSendType" BO_ 760 8;
BA_ "VFrameFormat" BO_ 760 14;
BA_ "CANFD_BRS" BO_ 281 1;
BA_ "GenMsgCycleTime" BO_ 281 20;
BA_ "GenMsgStartDelayTime" BO_ 281 5;
BA_ "VFrameFormat" BO_ 281 14;
BA_ "CANFD_BRS" BO_ 854 1;
BA_ "GenMsgSendType" BO_ 854 8;
BA_ "GenMsgDelayTime" BO_ 854 20;
BA_ "VFrameFormat" BO_ 854 14;
BA_ "CANFD_BRS" BO_ 279 1;
BA_ "GenMsgCycleTime" BO_ 279 20;
BA_ "GenMsgStartDelayTime" BO_ 279 15;
BA_ "VFrameFormat" BO_ 279 14;
BA_ "CANFD_BRS" BO_ 275 1;
BA_ "GenMsgSendType" BO_ 275 8;
BA_ "VFrameFormat" BO_ 275 14;
BA_ "CANFD_BRS" BO_ 277 1;
BA_ "GenMsgSendType" BO_ 277 8;
BA_ "GenMsgStartDelayTime" BO_ 277 10;
BA_ "VFrameFormat" BO_ 277 14;
BA_ "CANFD_BRS" BO_ 1543 1;
BA_ "GenMsgCycleTime" BO_ 1543 5000;
BA_ "GenMsgStartDelayTime" BO_ 1543 125;
BA_ "VFrameFormat" BO_ 1543 14;
BA_ "CANFD_BRS" BO_ 1265 1;
BA_ "GenMsgCycleTime" BO_ 1265 100;
BA_ "GenMsgStartDelayTime" BO_ 1265 30;
BA_ "VFrameFormat" BO_ 1265 14;
BA_ "CANFD_BRS" BO_ 1552 1;
BA_ "GenMsgCycleTime" BO_ 1552 10000;
BA_ "GenMsgStartDelayTime" BO_ 1552 240;
BA_ "VFrameFormat" BO_ 1552 14;
BA_ "CANFD_BRS" BO_ 597 1;
BA_ "GenMsgSendType" BO_ 597 8;
BA_ "GenMsgDelayTime" BO_ 597 10;
BA_ "VFrameFormat" BO_ 597 14;
BA_ "GenSigSendType" SG_ 788 FLCObject04_LatVel 1;
BA_ "GenSigStartValue" SG_ 788 FLCObject04_LatVel 8191;
BA_ "GenSigSendType" SG_ 788 FLCObject04_LatVelVar 1;
BA_ "GenSigStartValue" SG_ 788 FLCObject04_LatVelVar 255;
BA_ "GenSigSendType" SG_ 788 FLCObject04_CoastIndex 1;
BA_ "GenSigStartValue" SG_ 788 FLCObject04_CoastIndex 31;
BA_ "GenSigSendType" SG_ 788 FLCObject04_LifeTime 1;
BA_ "GenSigStartValue" SG_ 788 FLCObject04_LifeTime 65535;
BA_ "GenSigSendType" SG_ 788 FLCObject04_DistFarCorner 1;
BA_ "GenSigStartValue" SG_ 788 FLCObject04_DistFarCorner 4095;
BA_ "GenSigSendType" SG_ 788 FLCObject04_TurnIndication 1;
BA_ "GenSigStartValue" SG_ 788 FLCObject04_TurnIndication 7;
BA_ "GenSigSendType" SG_ 788 FLCObject04_AnglLeftCorner 1;
BA_ "GenSigStartValue" SG_ 788 FLCObject04_AnglLeftCorner 1023;
BA_ "GenSigSendType" SG_ 788 FLCObject04_CRC 1;
BA_ "GenSigStartValue" SG_ 788 FLCObject04_CRC 65535;
BA_ "E2EDataId" SG_ 788 FLCObject04_CRC 79;
BA_ "E2EDataLength" SG_ 788 FLCObject04_CRC 352;
BA_ "E2EProfile" SG_ 788 FLCObject04_CRC "P05";
BA_ "GenSigSendType" SG_ 788 FLCObject04_LatPos 1;
BA_ "GenSigStartValue" SG_ 788 FLCObject04_LatPos 8191;
BA_ "GenSigSendType" SG_ 788 FLCObject04_DstRightVar 1;
BA_ "GenSigStartValue" SG_ 788 FLCObject04_DstRightVar 255;
BA_ "GenSigSendType" SG_ 788 FLCObject04_Height 1;
BA_ "GenSigStartValue" SG_ 788 FLCObject04_Height 255;
BA_ "GenSigSendType" SG_ 788 FLCObject04_LongVel 1;
BA_ "GenSigStartValue" SG_ 788 FLCObject04_LongVel 8191;
BA_ "GenSigSendType" SG_ 788 FLCObject04_ExistConf 1;
BA_ "GenSigStartValue" SG_ 788 FLCObject04_ExistConf 127;
BA_ "GenSigSendType" SG_ 788 FLCObject04_DstFarVar 1;
BA_ "GenSigStartValue" SG_ 788 FLCObject04_DstFarVar 255;
BA_ "GenSigSendType" SG_ 788 FLCObject04_ObjClass 1;
BA_ "GenSigStartValue" SG_ 788 FLCObject04_ObjClass 15;
BA_ "GenSigSendType" SG_ 788 FLCObject04_AngLeftVar 1;
BA_ "GenSigStartValue" SG_ 788 FLCObject04_AngLeftVar 255;
BA_ "GenSigSendType" SG_ 788 FLCObject04_ScaleChange 1;
BA_ "GenSigStartValue" SG_ 788 FLCObject04_ScaleChange 1023;
BA_ "GenSigSendType" SG_ 788 FLCObject04_AnglRightCorner 1;
BA_ "GenSigStartValue" SG_ 788 FLCObject04_AnglRightCorner 1023;
BA_ "GenSigSendType" SG_ 788 FLCObject04_LongPosVar 1;
BA_ "GenSigStartValue" SG_ 788 FLCObject04_LongPosVar 255;
BA_ "GenSigSendType" SG_ 788 FLCObject04_LongAcc 1;
BA_ "GenSigStartValue" SG_ 788 FLCObject04_LongAcc 511;
BA_ "GenSigSendType" SG_ 788 FLCObject04_ObjDynClass 1;
BA_ "GenSigStartValue" SG_ 788 FLCObject04_ObjDynClass 3;
BA_ "GenSigSendType" SG_ 788 FLCObject04_Counter 1;
BA_ "GenSigStartValue" SG_ 788 FLCObject04_Counter 255;
BA_ "GenSigSendType" SG_ 788 FLCObject04_ObjID 1;
BA_ "GenSigStartValue" SG_ 788 FLCObject04_ObjID 63;
BA_ "GenSigSendType" SG_ 788 FLCObject04_TrackStatus 1;
BA_ "GenSigStartValue" SG_ 788 FLCObject04_TrackStatus 7;
BA_ "GenSigSendType" SG_ 788 FLCObject04_AngRightVar 1;
BA_ "GenSigStartValue" SG_ 788 FLCObject04_AngRightVar 255;
BA_ "GenSigSendType" SG_ 788 FLCObject04_DistLeftCorner 1;
BA_ "GenSigStartValue" SG_ 788 FLCObject04_DistLeftCorner 4095;
BA_ "GenSigSendType" SG_ 788 FLCObject04_Heading 1;
BA_ "GenSigStartValue" SG_ 788 FLCObject04_Heading 2047;
BA_ "GenSigSendType" SG_ 788 FLCObject04_BrakeLight 1;
BA_ "GenSigStartValue" SG_ 788 FLCObject04_BrakeLight 7;
BA_ "GenSigSendType" SG_ 788 FLCObject04_DistRightCorner 1;
BA_ "GenSigStartValue" SG_ 788 FLCObject04_DistRightCorner 4095;
BA_ "GenSigSendType" SG_ 788 FLCObject04_AnglFarCorner 1;
BA_ "GenSigStartValue" SG_ 788 FLCObject04_AnglFarCorner 1023;
BA_ "GenSigSendType" SG_ 788 FLCObject04_AngFarVar 1;
BA_ "GenSigStartValue" SG_ 788 FLCObject04_AngFarVar 255;
BA_ "GenSigSendType" SG_ 788 FLCObject04_DstLeftVar 1;
BA_ "GenSigStartValue" SG_ 788 FLCObject04_DstLeftVar 255;
BA_ "GenSigSendType" SG_ 788 FLCObject04_LatAcc 1;
BA_ "GenSigStartValue" SG_ 788 FLCObject04_LatAcc 511;
BA_ "GenSigSendType" SG_ 788 FLCObject04_TargetToLine 1;
BA_ "GenSigStartValue" SG_ 788 FLCObject04_TargetToLine 7;
BA_ "GenSigSendType" SG_ 788 FLCObject04_LongVelVar 1;
BA_ "GenSigStartValue" SG_ 788 FLCObject04_LongVelVar 255;
BA_ "GenSigSendType" SG_ 788 FLCObject04_LatPosVar 1;
BA_ "GenSigStartValue" SG_ 788 FLCObject04_LatPosVar 255;
BA_ "GenSigSendType" SG_ 788 FLCObject04_TimeStamp 1;
BA_ "GenSigStartValue" SG_ 788 FLCObject04_TimeStamp 65535;
BA_ "GenSigSendType" SG_ 788 FLCObject04_LongPos 1;
BA_ "GenSigStartValue" SG_ 788 FLCObject04_LongPos 8191;
BA_ "GenSigSendType" SG_ 788 FLCObject04_ReliabilityConf 1;
BA_ "GenSigStartValue" SG_ 788 FLCObject04_ReliabilityConf 7;
BA_ "GenSigSendType" SG_ 788 FLCObject04_HeadingVar 1;
BA_ "GenSigStartValue" SG_ 788 FLCObject04_HeadingVar 255;
BA_ "GenSigSendType" SG_ 787 FLCObject03_Height 1;
BA_ "GenSigStartValue" SG_ 787 FLCObject03_Height 255;
BA_ "GenSigSendType" SG_ 787 FLCObject03_LatAcc 1;
BA_ "GenSigStartValue" SG_ 787 FLCObject03_LatAcc 511;
BA_ "GenSigSendType" SG_ 787 FLCObject03_LatVelVar 1;
BA_ "GenSigStartValue" SG_ 787 FLCObject03_LatVelVar 255;
BA_ "GenSigSendType" SG_ 787 FLCObject03_TrackStatus 1;
BA_ "GenSigStartValue" SG_ 787 FLCObject03_TrackStatus 7;
BA_ "GenSigSendType" SG_ 787 FLCObject03_LifeTime 1;
BA_ "GenSigStartValue" SG_ 787 FLCObject03_LifeTime 65535;
BA_ "GenSigSendType" SG_ 787 FLCObject03_AnglFarCorner 1;
BA_ "GenSigStartValue" SG_ 787 FLCObject03_AnglFarCorner 1023;
BA_ "GenSigSendType" SG_ 787 FLCObject03_LongAcc 1;
BA_ "GenSigStartValue" SG_ 787 FLCObject03_LongAcc 511;
BA_ "GenSigSendType" SG_ 787 FLCObject03_Heading 1;
BA_ "GenSigStartValue" SG_ 787 FLCObject03_Heading 2047;
BA_ "GenSigSendType" SG_ 787 FLCObject03_AngFarVar 1;
BA_ "GenSigStartValue" SG_ 787 FLCObject03_AngFarVar 255;
BA_ "GenSigSendType" SG_ 787 FLCObject03_LongPosVar 1;
BA_ "GenSigStartValue" SG_ 787 FLCObject03_LongPosVar 255;
BA_ "GenSigSendType" SG_ 787 FLCObject03_LatPos 1;
BA_ "GenSigStartValue" SG_ 787 FLCObject03_LatPos 8191;
BA_ "GenSigSendType" SG_ 787 FLCObject03_ScaleChange 1;
BA_ "GenSigStartValue" SG_ 787 FLCObject03_ScaleChange 1023;
BA_ "GenSigSendType" SG_ 787 FLCObject03_LongVelVar 1;
BA_ "GenSigStartValue" SG_ 787 FLCObject03_LongVelVar 255;
BA_ "GenSigSendType" SG_ 787 FLCObject03_LongVel 1;
BA_ "GenSigStartValue" SG_ 787 FLCObject03_LongVel 8191;
BA_ "GenSigSendType" SG_ 787 FLCObject03_DstFarVar 1;
BA_ "GenSigStartValue" SG_ 787 FLCObject03_DstFarVar 255;
BA_ "GenSigSendType" SG_ 787 FLCObject03_TargetToLine 1;
BA_ "GenSigStartValue" SG_ 787 FLCObject03_TargetToLine 7;
BA_ "GenSigSendType" SG_ 787 FLCObject03_CoastIndex 1;
BA_ "GenSigStartValue" SG_ 787 FLCObject03_CoastIndex 31;
BA_ "GenSigSendType" SG_ 787 FLCObject03_DstRightVar 1;
BA_ "GenSigStartValue" SG_ 787 FLCObject03_DstRightVar 255;
BA_ "GenSigSendType" SG_ 787 FLCObject03_ExistConf 1;
BA_ "GenSigStartValue" SG_ 787 FLCObject03_ExistConf 127;
BA_ "GenSigSendType" SG_ 787 FLCObject03_LongPos 1;
BA_ "GenSigStartValue" SG_ 787 FLCObject03_LongPos 8191;
BA_ "GenSigSendType" SG_ 787 FLCObject03_AnglRightCorner 1;
BA_ "GenSigStartValue" SG_ 787 FLCObject03_AnglRightCorner 1023;
BA_ "GenSigSendType" SG_ 787 FLCObject03_LatVel 1;
BA_ "GenSigStartValue" SG_ 787 FLCObject03_LatVel 8191;
BA_ "GenSigSendType" SG_ 787 FLCObject03_ObjClass 1;
BA_ "GenSigStartValue" SG_ 787 FLCObject03_ObjClass 15;
BA_ "GenSigSendType" SG_ 787 FLCObject03_TimeStamp 1;
BA_ "GenSigStartValue" SG_ 787 FLCObject03_TimeStamp 65535;
BA_ "GenSigSendType" SG_ 787 FLCObject03_ObjDynClass 1;
BA_ "GenSigStartValue" SG_ 787 FLCObject03_ObjDynClass 3;
BA_ "GenSigSendType" SG_ 787 FLCObject03_CRC 1;
BA_ "GenSigStartValue" SG_ 787 FLCObject03_CRC 65535;
BA_ "E2EDataId" SG_ 787 FLCObject03_CRC 78;
BA_ "E2EDataLength" SG_ 787 FLCObject03_CRC 352;
BA_ "E2EProfile" SG_ 787 FLCObject03_CRC "P05";
BA_ "GenSigSendType" SG_ 787 FLCObject03_AnglLeftCorner 1;
BA_ "GenSigStartValue" SG_ 787 FLCObject03_AnglLeftCorner 1023;
BA_ "GenSigSendType" SG_ 787 FLCObject03_ReliabilityConf 1;
BA_ "GenSigStartValue" SG_ 787 FLCObject03_ReliabilityConf 7;
BA_ "GenSigSendType" SG_ 787 FLCObject03_DistLeftCorner 1;
BA_ "GenSigStartValue" SG_ 787 FLCObject03_DistLeftCorner 4095;
BA_ "GenSigSendType" SG_ 787 FLCObject03_DstLeftVar 1;
BA_ "GenSigStartValue" SG_ 787 FLCObject03_DstLeftVar 255;
BA_ "GenSigSendType" SG_ 787 FLCObject03_DistFarCorner 1;
BA_ "GenSigStartValue" SG_ 787 FLCObject03_DistFarCorner 4095;
BA_ "GenSigSendType" SG_ 787 FLCObject03_TurnIndication 1;
BA_ "GenSigStartValue" SG_ 787 FLCObject03_TurnIndication 7;
BA_ "GenSigSendType" SG_ 787 FLCObject03_LatPosVar 1;
BA_ "GenSigStartValue" SG_ 787 FLCObject03_LatPosVar 255;
BA_ "GenSigSendType" SG_ 787 FLCObject03_DistRightCorner 1;
BA_ "GenSigStartValue" SG_ 787 FLCObject03_DistRightCorner 4095;
BA_ "GenSigSendType" SG_ 787 FLCObject03_ObjID 1;
BA_ "GenSigStartValue" SG_ 787 FLCObject03_ObjID 63;
BA_ "GenSigSendType" SG_ 787 FLCObject03_AngLeftVar 1;
BA_ "GenSigStartValue" SG_ 787 FLCObject03_AngLeftVar 255;
BA_ "GenSigSendType" SG_ 787 FLCObject03_BrakeLight 1;
BA_ "GenSigStartValue" SG_ 787 FLCObject03_BrakeLight 7;
BA_ "GenSigSendType" SG_ 787 FLCObject03_HeadingVar 1;
BA_ "GenSigStartValue" SG_ 787 FLCObject03_HeadingVar 255;
BA_ "GenSigSendType" SG_ 787 FLCObject03_Counter 1;
BA_ "GenSigStartValue" SG_ 787 FLCObject03_Counter 255;
BA_ "GenSigSendType" SG_ 787 FLCObject03_AngRightVar 1;
BA_ "GenSigStartValue" SG_ 787 FLCObject03_AngRightVar 255;
BA_ "GenSigSendType" SG_ 786 FLCObject02_ScaleChange 1;
BA_ "GenSigStartValue" SG_ 786 FLCObject02_ScaleChange 1023;
BA_ "GenSigSendType" SG_ 786 FLCObject02_Height 1;
BA_ "GenSigStartValue" SG_ 786 FLCObject02_Height 255;
BA_ "GenSigSendType" SG_ 786 FLCObject02_AnglRightCorner 1;
BA_ "GenSigStartValue" SG_ 786 FLCObject02_AnglRightCorner 1023;
BA_ "GenSigSendType" SG_ 786 FLCObject02_AnglFarCorner 1;
BA_ "GenSigStartValue" SG_ 786 FLCObject02_AnglFarCorner 1023;
BA_ "GenSigSendType" SG_ 786 FLCObject02_DistRightCorner 1;
BA_ "GenSigStartValue" SG_ 786 FLCObject02_DistRightCorner 4095;
BA_ "GenSigSendType" SG_ 786 FLCObject02_LongAcc 1;
BA_ "GenSigStartValue" SG_ 786 FLCObject02_LongAcc 511;
BA_ "GenSigSendType" SG_ 786 FLCObject02_AngRightVar 1;
BA_ "GenSigStartValue" SG_ 786 FLCObject02_AngRightVar 255;
BA_ "GenSigSendType" SG_ 786 FLCObject02_CRC 1;
BA_ "GenSigStartValue" SG_ 786 FLCObject02_CRC 65535;
BA_ "E2EDataId" SG_ 786 FLCObject02_CRC 77;
BA_ "E2EDataLength" SG_ 786 FLCObject02_CRC 352;
BA_ "E2EProfile" SG_ 786 FLCObject02_CRC "P05";
BA_ "GenSigSendType" SG_ 786 FLCObject02_LatAcc 1;
BA_ "GenSigStartValue" SG_ 786 FLCObject02_LatAcc 511;
BA_ "GenSigSendType" SG_ 786 FLCObject02_TrackStatus 1;
BA_ "GenSigStartValue" SG_ 786 FLCObject02_TrackStatus 7;
BA_ "GenSigSendType" SG_ 786 FLCObject02_Heading 1;
BA_ "GenSigStartValue" SG_ 786 FLCObject02_Heading 2047;
BA_ "GenSigSendType" SG_ 786 FLCObject02_AnglLeftCorner 1;
BA_ "GenSigStartValue" SG_ 786 FLCObject02_AnglLeftCorner 1023;
BA_ "GenSigSendType" SG_ 786 FLCObject02_LongVelVar 1;
BA_ "GenSigStartValue" SG_ 786 FLCObject02_LongVelVar 255;
BA_ "GenSigSendType" SG_ 786 FLCObject02_LatPos 1;
BA_ "GenSigStartValue" SG_ 786 FLCObject02_LatPos 8191;
BA_ "GenSigSendType" SG_ 786 FLCObject02_LongPosVar 1;
BA_ "GenSigStartValue" SG_ 786 FLCObject02_LongPosVar 255;
BA_ "GenSigSendType" SG_ 786 FLCObject02_LatVelVar 1;
BA_ "GenSigStartValue" SG_ 786 FLCObject02_LatVelVar 255;
BA_ "GenSigSendType" SG_ 786 FLCObject02_LongVel 1;
BA_ "GenSigStartValue" SG_ 786 FLCObject02_LongVel 8191;
BA_ "GenSigSendType" SG_ 786 FLCObject02_ObjDynClass 1;
BA_ "GenSigStartValue" SG_ 786 FLCObject02_ObjDynClass 3;
BA_ "GenSigSendType" SG_ 786 FLCObject02_TimeStamp 1;
BA_ "GenSigStartValue" SG_ 786 FLCObject02_TimeStamp 65535;
BA_ "GenSigSendType" SG_ 786 FLCObject02_DistFarCorner 1;
BA_ "GenSigStartValue" SG_ 786 FLCObject02_DistFarCorner 4095;
BA_ "GenSigSendType" SG_ 786 FLCObject02_DstFarVar 1;
BA_ "GenSigStartValue" SG_ 786 FLCObject02_DstFarVar 255;
BA_ "GenSigSendType" SG_ 786 FLCObject02_LifeTime 1;
BA_ "GenSigStartValue" SG_ 786 FLCObject02_LifeTime 65535;
BA_ "GenSigSendType" SG_ 786 FLCObject02_LatVel 1;
BA_ "GenSigStartValue" SG_ 786 FLCObject02_LatVel 8191;
BA_ "GenSigSendType" SG_ 786 FLCObject02_ObjID 1;
BA_ "GenSigStartValue" SG_ 786 FLCObject02_ObjID 63;
BA_ "GenSigSendType" SG_ 786 FLCObject02_ExistConf 1;
BA_ "GenSigStartValue" SG_ 786 FLCObject02_ExistConf 127;
BA_ "GenSigSendType" SG_ 786 FLCObject02_DstRightVar 1;
BA_ "GenSigStartValue" SG_ 786 FLCObject02_DstRightVar 255;
BA_ "GenSigSendType" SG_ 786 FLCObject02_ReliabilityConf 1;
BA_ "GenSigStartValue" SG_ 786 FLCObject02_ReliabilityConf 7;
BA_ "GenSigSendType" SG_ 786 FLCObject02_DistLeftCorner 1;
BA_ "GenSigStartValue" SG_ 786 FLCObject02_DistLeftCorner 4095;
BA_ "GenSigSendType" SG_ 786 FLCObject02_HeadingVar 1;
BA_ "GenSigStartValue" SG_ 786 FLCObject02_HeadingVar 255;
BA_ "GenSigSendType" SG_ 786 FLCObject02_TurnIndication 1;
BA_ "GenSigStartValue" SG_ 786 FLCObject02_TurnIndication 7;
BA_ "GenSigSendType" SG_ 786 FLCObject02_ObjClass 1;
BA_ "GenSigStartValue" SG_ 786 FLCObject02_ObjClass 15;
BA_ "GenSigSendType" SG_ 786 FLCObject02_LongPos 1;
BA_ "GenSigStartValue" SG_ 786 FLCObject02_LongPos 8191;
BA_ "GenSigSendType" SG_ 786 FLCObject02_DstLeftVar 1;
BA_ "GenSigStartValue" SG_ 786 FLCObject02_DstLeftVar 255;
BA_ "GenSigSendType" SG_ 786 FLCObject02_AngLeftVar 1;
BA_ "GenSigStartValue" SG_ 786 FLCObject02_AngLeftVar 255;
BA_ "GenSigSendType" SG_ 786 FLCObject02_BrakeLight 1;
BA_ "GenSigStartValue" SG_ 786 FLCObject02_BrakeLight 7;
BA_ "GenSigSendType" SG_ 786 FLCObject02_LatPosVar 1;
BA_ "GenSigStartValue" SG_ 786 FLCObject02_LatPosVar 255;
BA_ "GenSigSendType" SG_ 786 FLCObject02_CoastIndex 1;
BA_ "GenSigStartValue" SG_ 786 FLCObject02_CoastIndex 31;
BA_ "GenSigSendType" SG_ 786 FLCObject02_Counter 1;
BA_ "GenSigStartValue" SG_ 786 FLCObject02_Counter 255;
BA_ "GenSigSendType" SG_ 786 FLCObject02_TargetToLine 1;
BA_ "GenSigStartValue" SG_ 786 FLCObject02_TargetToLine 7;
BA_ "GenSigSendType" SG_ 786 FLCObject02_AngFarVar 1;
BA_ "GenSigStartValue" SG_ 786 FLCObject02_AngFarVar 255;
BA_ "GenSigSendType" SG_ 785 FLCObject01_TimeStamp 1;
BA_ "GenSigStartValue" SG_ 785 FLCObject01_TimeStamp 65535;
BA_ "GenSigSendType" SG_ 785 FLCObject01_CRC 1;
BA_ "GenSigStartValue" SG_ 785 FLCObject01_CRC 65535;
BA_ "E2EDataId" SG_ 785 FLCObject01_CRC 76;
BA_ "E2EDataLength" SG_ 785 FLCObject01_CRC 352;
BA_ "E2EProfile" SG_ 785 FLCObject01_CRC "P05";
BA_ "GenSigSendType" SG_ 785 FLCObject01_LongVelVar 1;
BA_ "GenSigStartValue" SG_ 785 FLCObject01_LongVelVar 255;
BA_ "GenSigSendType" SG_ 785 FLCObject01_ObjDynClass 1;
BA_ "GenSigStartValue" SG_ 785 FLCObject01_ObjDynClass 3;
BA_ "GenSigSendType" SG_ 785 FLCObject01_ScaleChange 1;
BA_ "GenSigStartValue" SG_ 785 FLCObject01_ScaleChange 1023;
BA_ "GenSigSendType" SG_ 785 FLCObject01_AnglRightCorner 1;
BA_ "GenSigStartValue" SG_ 785 FLCObject01_AnglRightCorner 1023;
BA_ "GenSigSendType" SG_ 785 FLCObject01_ReliabilityConf 1;
BA_ "GenSigStartValue" SG_ 785 FLCObject01_ReliabilityConf 7;
BA_ "GenSigSendType" SG_ 785 FLCObject01_LongAcc 1;
BA_ "GenSigStartValue" SG_ 785 FLCObject01_LongAcc 511;
BA_ "GenSigSendType" SG_ 785 FLCObject01_DistLeftCorner 1;
BA_ "GenSigStartValue" SG_ 785 FLCObject01_DistLeftCorner 4095;
BA_ "GenSigSendType" SG_ 785 FLCObject01_BrakeLight 1;
BA_ "GenSigStartValue" SG_ 785 FLCObject01_BrakeLight 7;
BA_ "GenSigSendType" SG_ 785 FLCObject01_DstFarVar 1;
BA_ "GenSigStartValue" SG_ 785 FLCObject01_DstFarVar 255;
BA_ "GenSigSendType" SG_ 785 FLCObject01_LatVel 1;
BA_ "GenSigStartValue" SG_ 785 FLCObject01_LatVel 8191;
BA_ "GenSigSendType" SG_ 785 FLCObject01_LatPos 1;
BA_ "GenSigStartValue" SG_ 785 FLCObject01_LatPos 8191;
BA_ "GenSigSendType" SG_ 785 FLCObject01_LongPosVar 1;
BA_ "GenSigStartValue" SG_ 785 FLCObject01_LongPosVar 255;
BA_ "GenSigSendType" SG_ 785 FLCObject01_DstLeftVar 1;
BA_ "GenSigStartValue" SG_ 785 FLCObject01_DstLeftVar 255;
BA_ "GenSigSendType" SG_ 785 FLCObject01_LatPosVar 1;
BA_ "GenSigStartValue" SG_ 785 FLCObject01_LatPosVar 255;
BA_ "GenSigSendType" SG_ 785 FLCObject01_ExistConf 1;
BA_ "GenSigStartValue" SG_ 785 FLCObject01_ExistConf 127;
BA_ "GenSigSendType" SG_ 785 FLCObject01_Counter 1;
BA_ "GenSigStartValue" SG_ 785 FLCObject01_Counter 255;
BA_ "GenSigSendType" SG_ 785 FLCObject01_ObjClass 1;
BA_ "GenSigStartValue" SG_ 785 FLCObject01_ObjClass 15;
BA_ "GenSigSendType" SG_ 785 FLCObject01_LongVel 1;
BA_ "GenSigStartValue" SG_ 785 FLCObject01_LongVel 8191;
BA_ "GenSigSendType" SG_ 785 FLCObject01_Height 1;
BA_ "GenSigStartValue" SG_ 785 FLCObject01_Height 255;
BA_ "GenSigSendType" SG_ 785 FLCObject01_LatVelVar 1;
BA_ "GenSigStartValue" SG_ 785 FLCObject01_LatVelVar 255;
BA_ "GenSigSendType" SG_ 785 FLCObject01_AnglFarCorner 1;
BA_ "GenSigStartValue" SG_ 785 FLCObject01_AnglFarCorner 1023;
BA_ "GenSigSendType" SG_ 785 FLCObject01_Heading 1;
BA_ "GenSigStartValue" SG_ 785 FLCObject01_Heading 2047;
BA_ "GenSigSendType" SG_ 785 FLCObject01_LatAcc 1;
BA_ "GenSigStartValue" SG_ 785 FLCObject01_LatAcc 511;
BA_ "GenSigSendType" SG_ 785 FLCObject01_LifeTime 1;
BA_ "GenSigStartValue" SG_ 785 FLCObject01_LifeTime 65535;
BA_ "GenSigSendType" SG_ 785 FLCObject01_HeadingVar 1;
BA_ "GenSigStartValue" SG_ 785 FLCObject01_HeadingVar 255;
BA_ "GenSigSendType" SG_ 785 FLCObject01_AngLeftVar 1;
BA_ "GenSigStartValue" SG_ 785 FLCObject01_AngLeftVar 255;
BA_ "GenSigSendType" SG_ 785 FLCObject01_AngFarVar 1;
BA_ "GenSigStartValue" SG_ 785 FLCObject01_AngFarVar 255;
BA_ "GenSigSendType" SG_ 785 FLCObject01_CoastIndex 1;
BA_ "GenSigStartValue" SG_ 785 FLCObject01_CoastIndex 31;
BA_ "GenSigSendType" SG_ 785 FLCObject01_DistRightCorner 1;
BA_ "GenSigStartValue" SG_ 785 FLCObject01_DistRightCorner 4095;
BA_ "GenSigSendType" SG_ 785 FLCObject01_TrackStatus 1;
BA_ "GenSigStartValue" SG_ 785 FLCObject01_TrackStatus 7;
BA_ "GenSigSendType" SG_ 785 FLCObject01_LongPos 1;
BA_ "GenSigStartValue" SG_ 785 FLCObject01_LongPos 8191;
BA_ "GenSigSendType" SG_ 785 FLCObject01_ObjID 1;
BA_ "GenSigStartValue" SG_ 785 FLCObject01_ObjID 63;
BA_ "GenSigSendType" SG_ 785 FLCObject01_DstRightVar 1;
BA_ "GenSigStartValue" SG_ 785 FLCObject01_DstRightVar 255;
BA_ "GenSigSendType" SG_ 785 FLCObject01_DistFarCorner 1;
BA_ "GenSigStartValue" SG_ 785 FLCObject01_DistFarCorner 4095;
BA_ "GenSigSendType" SG_ 785 FLCObject01_TargetToLine 1;
BA_ "GenSigStartValue" SG_ 785 FLCObject01_TargetToLine 7;
BA_ "GenSigSendType" SG_ 785 FLCObject01_TurnIndication 1;
BA_ "GenSigStartValue" SG_ 785 FLCObject01_TurnIndication 7;
BA_ "GenSigSendType" SG_ 785 FLCObject01_AngRightVar 1;
BA_ "GenSigStartValue" SG_ 785 FLCObject01_AngRightVar 255;
BA_ "GenSigSendType" SG_ 785 FLCObject01_AnglLeftCorner 1;
BA_ "GenSigStartValue" SG_ 785 FLCObject01_AnglLeftCorner 1023;
BA_ "GenSigSendType" SG_ 784 FLCObject00_LifeTime 1;
BA_ "GenSigStartValue" SG_ 784 FLCObject00_LifeTime 65535;
BA_ "GenSigSendType" SG_ 784 FLCObject00_BrakeLight 1;
BA_ "GenSigStartValue" SG_ 784 FLCObject00_BrakeLight 7;
BA_ "GenSigSendType" SG_ 784 FLCObject00_AnglLeftCorner 1;
BA_ "GenSigStartValue" SG_ 784 FLCObject00_AnglLeftCorner 1023;
BA_ "GenSigSendType" SG_ 784 FLCObject00_DistRightCorner 1;
BA_ "GenSigStartValue" SG_ 784 FLCObject00_DistRightCorner 4095;
BA_ "GenSigSendType" SG_ 784 FLCObject00_LatPos 1;
BA_ "GenSigStartValue" SG_ 784 FLCObject00_LatPos 8191;
BA_ "GenSigSendType" SG_ 784 FLCObject00_TimeStamp 1;
BA_ "GenSigStartValue" SG_ 784 FLCObject00_TimeStamp 65535;
BA_ "GenSigSendType" SG_ 784 FLCObject00_LatAcc 1;
BA_ "GenSigStartValue" SG_ 784 FLCObject00_LatAcc 511;
BA_ "GenSigSendType" SG_ 784 FLCObject00_LatVel 1;
BA_ "GenSigStartValue" SG_ 784 FLCObject00_LatVel 8191;
BA_ "GenSigSendType" SG_ 784 FLCObject00_ExistConf 1;
BA_ "GenSigStartValue" SG_ 784 FLCObject00_ExistConf 127;
BA_ "GenSigSendType" SG_ 784 FLCObject00_AngRightVar 1;
BA_ "GenSigStartValue" SG_ 784 FLCObject00_AngRightVar 255;
BA_ "GenSigSendType" SG_ 784 FLCObject00_AnglRightCorner 1;
BA_ "GenSigStartValue" SG_ 784 FLCObject00_AnglRightCorner 1023;
BA_ "GenSigSendType" SG_ 784 FLCObject00_LatPosVar 1;
BA_ "GenSigStartValue" SG_ 784 FLCObject00_LatPosVar 255;
BA_ "GenSigSendType" SG_ 784 FLCObject00_DistLeftCorner 1;
BA_ "GenSigStartValue" SG_ 784 FLCObject00_DistLeftCorner 4095;
BA_ "GenSigSendType" SG_ 784 FLCObject00_CoastIndex 1;
BA_ "GenSigStartValue" SG_ 784 FLCObject00_CoastIndex 31;
BA_ "GenSigSendType" SG_ 784 FLCObject00_TrackStatus 1;
BA_ "GenSigStartValue" SG_ 784 FLCObject00_TrackStatus 7;
BA_ "GenSigSendType" SG_ 784 FLCObject00_ScaleChange 1;
BA_ "GenSigStartValue" SG_ 784 FLCObject00_ScaleChange 1023;
BA_ "GenSigSendType" SG_ 784 FLCObject00_LatVelVar 1;
BA_ "GenSigStartValue" SG_ 784 FLCObject00_LatVelVar 255;
BA_ "GenSigSendType" SG_ 784 FLCObject00_HeadingVar 1;
BA_ "GenSigStartValue" SG_ 784 FLCObject00_HeadingVar 255;
BA_ "GenSigSendType" SG_ 784 FLCObject00_LongPosVar 1;
BA_ "GenSigStartValue" SG_ 784 FLCObject00_LongPosVar 255;
BA_ "GenSigSendType" SG_ 784 FLCObject00_DstLeftVar 1;
BA_ "GenSigStartValue" SG_ 784 FLCObject00_DstLeftVar 255;
BA_ "GenSigSendType" SG_ 784 FLCObject00_ObjID 1;
BA_ "GenSigStartValue" SG_ 784 FLCObject00_ObjID 63;
BA_ "GenSigSendType" SG_ 784 FLCObject00_ObjClass 1;
BA_ "GenSigStartValue" SG_ 784 FLCObject00_ObjClass 15;
BA_ "GenSigSendType" SG_ 784 FLCObject00_AnglFarCorner 1;
BA_ "GenSigStartValue" SG_ 784 FLCObject00_AnglFarCorner 1023;
BA_ "GenSigSendType" SG_ 784 FLCObject00_DstFarVar 1;
BA_ "GenSigStartValue" SG_ 784 FLCObject00_DstFarVar 255;
BA_ "GenSigSendType" SG_ 784 FLCObject00_LongVel 1;
BA_ "GenSigStartValue" SG_ 784 FLCObject00_LongVel 8191;
BA_ "GenSigSendType" SG_ 784 FLCObject00_LongPos 1;
BA_ "GenSigStartValue" SG_ 784 FLCObject00_LongPos 8191;
BA_ "GenSigSendType" SG_ 784 FLCObject00_AngLeftVar 1;
BA_ "GenSigStartValue" SG_ 784 FLCObject00_AngLeftVar 255;
BA_ "GenSigSendType" SG_ 784 FLCObject00_ReliabilityConf 1;
BA_ "GenSigStartValue" SG_ 784 FLCObject00_ReliabilityConf 7;
BA_ "GenSigSendType" SG_ 784 FLCObject00_Counter 1;
BA_ "GenSigStartValue" SG_ 784 FLCObject00_Counter 255;
BA_ "GenSigSendType" SG_ 784 FLCObject00_ObjDynClass 1;
BA_ "GenSigStartValue" SG_ 784 FLCObject00_ObjDynClass 3;
BA_ "GenSigSendType" SG_ 784 FLCObject00_TargetToLine 1;
BA_ "GenSigStartValue" SG_ 784 FLCObject00_TargetToLine 7;
BA_ "GenSigSendType" SG_ 784 FLCObject00_DstRightVar 1;
BA_ "GenSigStartValue" SG_ 784 FLCObject00_DstRightVar 255;
BA_ "GenSigSendType" SG_ 784 FLCObject00_TurnIndication 1;
BA_ "GenSigStartValue" SG_ 784 FLCObject00_TurnIndication 7;
BA_ "GenSigSendType" SG_ 784 FLCObject00_AngFarVar 1;
BA_ "GenSigStartValue" SG_ 784 FLCObject00_AngFarVar 255;
BA_ "GenSigSendType" SG_ 784 FLCObject00_Heading 1;
BA_ "GenSigStartValue" SG_ 784 FLCObject00_Heading 2047;
BA_ "GenSigSendType" SG_ 784 FLCObject00_DistFarCorner 1;
BA_ "GenSigStartValue" SG_ 784 FLCObject00_DistFarCorner 4095;
BA_ "GenSigSendType" SG_ 784 FLCObject00_LongAcc 1;
BA_ "GenSigStartValue" SG_ 784 FLCObject00_LongAcc 511;
BA_ "GenSigSendType" SG_ 784 FLCObject00_Height 1;
BA_ "GenSigStartValue" SG_ 784 FLCObject00_Height 255;
BA_ "GenSigSendType" SG_ 784 FLCObject00_LongVelVar 1;
BA_ "GenSigStartValue" SG_ 784 FLCObject00_LongVelVar 255;
BA_ "GenSigSendType" SG_ 784 FLCObject00_CRC 1;
BA_ "GenSigStartValue" SG_ 784 FLCObject00_CRC 65535;
BA_ "E2EDataId" SG_ 784 FLCObject00_CRC 75;
BA_ "E2EDataLength" SG_ 784 FLCObject00_CRC 352;
BA_ "E2EProfile" SG_ 784 FLCObject00_CRC "P05";
BA_ "GenSigSendType" SG_ 2671964753 DiagUUDTRespSig_F2_51 7;
BA_ "GenSigSendType" SG_ 2671834193 InternalTesterDiagSig_F4_51 7;
BA_ "GenSigSendType" SG_ 2671833937 InternalTesterDiagSig_F3_51 7;
BA_ "GenSigSendType" SG_ 2671792628 InternalTesterDiagSig_51_F4 7;
BA_ "GenSigSendType" SG_ 2671792627 InternalTesterDiagSig_51_F3 7;
BA_ "GenSigSendType" SG_ 1527 DiagFaultStat_FLC_sg_UB 7;
BA_ "GenSigSendType" SG_ 1527 DiagFaultStat_FLC_EcuAdr 3;
BA_ "GenSigStartValue" SG_ 1527 DiagFaultStat_FLC_EcuAdr 255;
BA_ "NeedsUpdateBit" SG_ 1527 DiagFaultStat_FLC_EcuAdr 1;
BA_ "GenSigSendType" SG_ 1527 DiagFaultStat_FLC_FailTA 3;
BA_ "NeedsUpdateBit" SG_ 1527 DiagFaultStat_FLC_FailTA 1;
BA_ "GenSigSendType" SG_ 1527 DiagFaultStat_FLC_DtcIdA 3;
BA_ "NeedsUpdateBit" SG_ 1527 DiagFaultStat_FLC_DtcIdA 1;
BA_ "GenSigSendType" SG_ 1527 DiagFaultStat_FLC_FailTB 3;
BA_ "NeedsUpdateBit" SG_ 1527 DiagFaultStat_FLC_FailTB 1;
BA_ "GenSigSendType" SG_ 1527 DiagFaultStat_FLC_DtcIdB 3;
BA_ "NeedsUpdateBit" SG_ 1527 DiagFaultStat_FLC_DtcIdB 1;
BA_ "GenSigSendType" SG_ 257 DACUTimeSync_CRC 1;
BA_ "GenSigSendType" SG_ 257 DACUTimeSync_SeqCnt 1;
BA_ "GenSigStartValue" SG_ 257 DACUTimeSync_SeqCnt 15;
BA_ "GenSigSendType" SG_ 257 DACUTimeSync_TimeDomain 1;
BA_ "GenSigStartValue" SG_ 257 DACUTimeSync_TimeDomain 15;
BA_ "GenSigSendType" SG_ 257 DACUTimeSync_Time 1;
BA_ "GenSigSendType" SG_ 257 DACUTimeSync_Type 1;
BA_ "GenSigSendType" SG_ 257 DACUTimeSync_UserByte 1;
BA_ "GenSigSendType" SG_ 761 DACUTimeSyncOFS_CRCOFS 1;
BA_ "GenSigSendType" SG_ 761 DACUTimeSyncOFS_SeqCnt 1;
BA_ "GenSigStartValue" SG_ 761 DACUTimeSyncOFS_SeqCnt 15;
BA_ "GenSigSendType" SG_ 761 DACUTimeSyncOFS_UserByte0 1;
BA_ "GenSigSendType" SG_ 761 DACUTimeSyncOFS_TypeOFS 1;
BA_ "GenSigSendType" SG_ 761 DACUTimeSyncOFS_TimeDomain 1;
BA_ "GenSigStartValue" SG_ 761 DACUTimeSyncOFS_TimeDomain 15;
BA_ "GenSigSendType" SG_ 761 DACUTimeSyncOFS_OfsTimeSec 1;
BA_ "GenSigSendType" SG_ 760 DACUTimeSyncOFNS_OfsTimeNsec 1;
BA_ "GenSigSendType" SG_ 760 DACUTimeSyncOFNS_SGW 1;
BA_ "GenSigSendType" SG_ 760 DACUTimeSyncOFNS_SeqCnt 1;
BA_ "GenSigStartValue" SG_ 760 DACUTimeSyncOFNS_SeqCnt 15;
BA_ "GenSigSendType" SG_ 760 DACUTimeSyncOFNS_CRCOFNS 1;
BA_ "GenSigSendType" SG_ 760 DACUTimeSyncOFNS_TypeOFNS 1;
BA_ "GenSigSendType" SG_ 760 DACUTimeSyncOFNS_TimeDomain 1;
BA_ "GenSigStartValue" SG_ 760 DACUTimeSyncOFNS_TimeDomain 15;
BA_ "GenSigCycleTime" SG_ 281 ShadowArea_LeftAgl03 100;
BA_ "GenSigCycleTimeActive" SG_ 281 ShadowArea_LeftAgl03 100;
BA_ "GenSigStartValue" SG_ 281 ShadowArea_LeftAgl03 2047;
BA_ "GenSigCycleTime" SG_ 281 ShadowArea_RightAgl02 100;
BA_ "GenSigCycleTimeActive" SG_ 281 ShadowArea_RightAgl02 100;
BA_ "GenSigStartValue" SG_ 281 ShadowArea_RightAgl02 2047;
BA_ "GenSigCycleTime" SG_ 281 ShadowArea_RightAgl01 100;
BA_ "GenSigCycleTimeActive" SG_ 281 ShadowArea_RightAgl01 100;
BA_ "GenSigStartValue" SG_ 281 ShadowArea_RightAgl01 2047;
BA_ "GenSigCycleTime" SG_ 281 ShadowArea_LeftAgl02 100;
BA_ "GenSigCycleTimeActive" SG_ 281 ShadowArea_LeftAgl02 100;
BA_ "GenSigStartValue" SG_ 281 ShadowArea_LeftAgl02 2047;
BA_ "GenSigCycleTime" SG_ 281 ShadowArea_Dist03 100;
BA_ "GenSigCycleTimeActive" SG_ 281 ShadowArea_Dist03 100;
BA_ "GenSigStartValue" SG_ 281 ShadowArea_Dist03 1023;
BA_ "GenSigCycleTime" SG_ 281 ShadowArea_Dist01 100;
BA_ "GenSigCycleTimeActive" SG_ 281 ShadowArea_Dist01 100;
BA_ "GenSigStartValue" SG_ 281 ShadowArea_Dist01 1023;
BA_ "GenSigCycleTime" SG_ 281 ShadowArea_LeftAgl01 100;
BA_ "GenSigCycleTimeActive" SG_ 281 ShadowArea_LeftAgl01 100;
BA_ "GenSigStartValue" SG_ 281 ShadowArea_LeftAgl01 2047;
BA_ "GenSigCycleTime" SG_ 281 ShadowArea_Dist02 100;
BA_ "GenSigCycleTimeActive" SG_ 281 ShadowArea_Dist02 100;
BA_ "GenSigStartValue" SG_ 281 ShadowArea_Dist02 1023;
BA_ "GenSigCycleTime" SG_ 281 ShadowArea_RightAgl03 100;
BA_ "GenSigCycleTimeActive" SG_ 281 ShadowArea_RightAgl03 100;
BA_ "GenSigStartValue" SG_ 281 ShadowArea_RightAgl03 2047;
BA_ "GenSigSendType" SG_ 854 GPSData_Time 1;
BA_ "GenSigStartValue" SG_ 854 GPSData_Time 4294967295;
BA_ "GenSigSendType" SG_ 854 GPSData_AntennaStat 1;
BA_ "GenSigStartValue" SG_ 854 GPSData_AntennaStat 7;
BA_ "GenSigSendType" SG_ 854 GPSData_Longitude 1;
BA_ "GenSigStartValue" SG_ 854 GPSData_Longitude 4294967295;
BA_ "GenSigSendType" SG_ 854 GPSData_VehSpeed 1;
BA_ "GenSigStartValue" SG_ 854 GPSData_VehSpeed 65535;
BA_ "GenSigSendType" SG_ 854 GPSData_Direction 1;
BA_ "GenSigSendType" SG_ 854 GPSData_sg_UB 7;
BA_ "GenSigSendType" SG_ 854 GPSData_Latitude 1;
BA_ "GenSigStartValue" SG_ 854 GPSData_Latitude 4294967295;
BA_ "GenSigSendType" SG_ 854 GPSData_HDOP 1;
BA_ "GenSigSendType" SG_ 854 GPSData_Altitude 1;
BA_ "GenSigStartValue" SG_ 854 GPSData_Altitude 65535;
BA_ "GenSigCycleTime" SG_ 279 EgoPathPrediction_ConfCoeffA3 100;
BA_ "GenSigCycleTimeActive" SG_ 279 EgoPathPrediction_ConfCoeffA3 100;
BA_ "GenSigStartValue" SG_ 279 EgoPathPrediction_ConfCoeffA3 65535;
BA_ "GenSigCycleTime" SG_ 279 EgoPathPrediction_CurvatureRate 100;
BA_ "GenSigCycleTimeActive" SG_ 279 EgoPathPrediction_CurvatureRate 100;
BA_ "GenSigStartValue" SG_ 279 EgoPathPrediction_CurvatureRate 2047;
BA_ "GenSigCycleTime" SG_ 279 EgoPathPrediction_DxEnd 100;
BA_ "GenSigCycleTimeActive" SG_ 279 EgoPathPrediction_DxEnd 100;
BA_ "GenSigStartValue" SG_ 279 EgoPathPrediction_DxEnd 255;
BA_ "GenSigCycleTime" SG_ 279 EgoPathPrediction_HeadingAngle 100;
BA_ "GenSigCycleTimeActive" SG_ 279 EgoPathPrediction_HeadingAngle 100;
BA_ "GenSigStartValue" SG_ 279 EgoPathPrediction_HeadingAngle 8191;
BA_ "GenSigCycleTime" SG_ 279 EgoPathPrediction_ConfCoeffA1 100;
BA_ "GenSigCycleTimeActive" SG_ 279 EgoPathPrediction_ConfCoeffA1 100;
BA_ "GenSigStartValue" SG_ 279 EgoPathPrediction_ConfCoeffA1 65535;
BA_ "GenSigCycleTime" SG_ 279 EgoPathPrediction_ConfCoeffA0 100;
BA_ "GenSigCycleTimeActive" SG_ 279 EgoPathPrediction_ConfCoeffA0 100;
BA_ "GenSigStartValue" SG_ 279 EgoPathPrediction_ConfCoeffA0 65535;
BA_ "GenSigCycleTime" SG_ 279 EgoPathPrediction_ConfCoeffA2 100;
BA_ "GenSigCycleTimeActive" SG_ 279 EgoPathPrediction_ConfCoeffA2 100;
BA_ "GenSigStartValue" SG_ 279 EgoPathPrediction_ConfCoeffA2 65535;
BA_ "GenSigCycleTime" SG_ 279 EgoPathPrediction_Curvature 100;
BA_ "GenSigCycleTimeActive" SG_ 279 EgoPathPrediction_Curvature 100;
BA_ "GenSigStartValue" SG_ 279 EgoPathPrediction_Curvature 262143;
BA_ "GenSigSendType" SG_ 275 VehicleMode_UB 7;
BA_ "GenSigSendType" SG_ 275 EgoMotionXYplane_LongSpeedVar 1;
BA_ "GenSigStartValue" SG_ 275 EgoMotionXYplane_LongSpeedVar 65535;
BA_ "GenSigSendType" SG_ 275 EgoMotionXYplane_LongAccVariance 1;
BA_ "GenSigStartValue" SG_ 275 EgoMotionXYplane_LongAccVariance 63;
BA_ "GenSigSendType" SG_ 275 EgoMotionXYplane_LongMotionDir 1;
BA_ "GenSigStartValue" SG_ 275 EgoMotionXYplane_LongMotionDir 7;
BA_ "GenSigSendType" SG_ 275 EgoMotionXYplane_Curvature 1;
BA_ "GenSigStartValue" SG_ 275 EgoMotionXYplane_Curvature 2097151;
BA_ "GenSigSendType" SG_ 275 EgoMotionXYplane_LongAcc 1;
BA_ "GenSigStartValue" SG_ 275 EgoMotionXYplane_LongAcc 65535;
BA_ "GenSigSendType" SG_ 275 EgoMotionXYplane_LatAccVariance 1;
BA_ "GenSigStartValue" SG_ 275 EgoMotionXYplane_LatAccVariance 63;
BA_ "GenSigSendType" SG_ 275 EgoMotionXYplane_YawRateVariance 1;
BA_ "GenSigStartValue" SG_ 275 EgoMotionXYplane_YawRateVariance 65535;
BA_ "GenSigSendType" SG_ 275 EgoMotionXYplane_LongMotDirConf 1;
BA_ "GenSigStartValue" SG_ 275 EgoMotionXYplane_LongMotDirConf 15;
BA_ "GenSigSendType" SG_ 275 EgoMotionXYplane_YawRateComp 1;
BA_ "GenSigStartValue" SG_ 275 EgoMotionXYplane_YawRateComp 65535;
BA_ "GenSigSendType" SG_ 275 EgoMotionXYplane_ReferencePointX 1;
BA_ "GenSigStartValue" SG_ 275 EgoMotionXYplane_ReferencePointX 65535;
BA_ "GenSigSendType" SG_ 275 EgoMotionXYplane_LateralSpeed 1;
BA_ "GenSigStartValue" SG_ 275 EgoMotionXYplane_LateralSpeed 65535;
BA_ "GenSigSendType" SG_ 275 EgoMotionXYplane_LateralAcc 1;
BA_ "GenSigStartValue" SG_ 275 EgoMotionXYplane_LateralAcc 65535;
BA_ "GenSigSendType" SG_ 275 EgoMotionXYplane_CRC 1;
BA_ "GenSigStartValue" SG_ 275 EgoMotionXYplane_CRC 65535;
BA_ "E2EDataId" SG_ 275 EgoMotionXYplane_CRC 17;
BA_ "E2EDataLength" SG_ 275 EgoMotionXYplane_CRC 240;
BA_ "E2EProfile" SG_ 275 EgoMotionXYplane_CRC "P05";
BA_ "GenSigSendType" SG_ 275 EgoMotionXYplane_LongSpeed 1;
BA_ "GenSigStartValue" SG_ 275 EgoMotionXYplane_LongSpeed 65535;
BA_ "GenSigSendType" SG_ 275 EgoMotionXYplane_LatSpeedVar 1;
BA_ "GenSigStartValue" SG_ 275 EgoMotionXYplane_LatSpeedVar 65535;
BA_ "GenSigSendType" SG_ 275 EgoMotionXYplane_LatencyEst 1;
BA_ "GenSigStartValue" SG_ 275 EgoMotionXYplane_LatencyEst 255;
BA_ "GenSigSendType" SG_ 275 EgoMotionXYplane_ChassisDynPitch 1;
BA_ "GenSigStartValue" SG_ 275 EgoMotionXYplane_ChassisDynPitch 255;
BA_ "GenSigSendType" SG_ 275 VehicleMode 7;
BA_ "GenSigStartValue" SG_ 275 VehicleMode 15;
BA_ "NeedsUpdateBit" SG_ 275 VehicleMode 1;
BA_ "GenSigSendType" SG_ 275 EgoMotionXYplane_Counter 1;
BA_ "GenSigStartValue" SG_ 275 EgoMotionXYplane_Counter 255;
BA_ "GenSigSendType" SG_ 275 EgoMotionXYplane_EffectiveWheelB 1;
BA_ "GenSigStartValue" SG_ 275 EgoMotionXYplane_EffectiveWheelB 1023;
BA_ "GenSigSendType" SG_ 277 EgoMotionRaw_RelLvlRrAxleRight 1;
BA_ "GenSigStartValue" SG_ 277 EgoMotionRaw_RelLvlRrAxleRight 65535;
BA_ "GenSigSendType" SG_ 277 EgoMotionRaw_FrAxleLeftWSpeed 1;
BA_ "GenSigStartValue" SG_ 277 EgoMotionRaw_FrAxleLeftWSpeed 65535;
BA_ "GenSigSendType" SG_ 277 EgoMotionRaw_GrossCombVehWeight 1;
BA_ "GenSigStartValue" SG_ 277 EgoMotionRaw_GrossCombVehWeight 65535;
BA_ "GenSigSendType" SG_ 277 EgoMotionRaw_FrontWheelAngle 1;
BA_ "GenSigStartValue" SG_ 277 EgoMotionRaw_FrontWheelAngle 65535;
BA_ "GenSigSendType" SG_ 277 EgoMotionRaw_BrakePedalPosition 1;
BA_ "GenSigStartValue" SG_ 277 EgoMotionRaw_BrakePedalPosition 255;
BA_ "GenSigSendType" SG_ 277 EgoMotionRaw_SteeringWheelAngle 1;
BA_ "GenSigStartValue" SG_ 277 EgoMotionRaw_SteeringWheelAngle 65535;
BA_ "GenSigSendType" SG_ 277 EgoMotionRaw_SteeringWheelRatio 1;
BA_ "GenSigStartValue" SG_ 277 EgoMotionRaw_SteeringWheelRatio 63;
BA_ "GenSigSendType" SG_ 277 EgoMotionRaw_FrAxleRightWSpeed 1;
BA_ "GenSigStartValue" SG_ 277 EgoMotionRaw_FrAxleRightWSpeed 65535;
BA_ "GenSigSendType" SG_ 277 EgoMotionRaw_ROPEngineActive 1;
BA_ "GenSigStartValue" SG_ 277 EgoMotionRaw_ROPEngineActive 3;
BA_ "GenSigSendType" SG_ 277 EgoMotionRaw_AccKckDwn 1;
BA_ "GenSigStartValue" SG_ 277 EgoMotionRaw_AccKckDwn 3;
BA_ "GenSigSendType" SG_ 277 EgoMotionRaw_RelLvlFrAxleLeft 1;
BA_ "GenSigStartValue" SG_ 277 EgoMotionRaw_RelLvlFrAxleLeft 65535;
BA_ "GenSigSendType" SG_ 277 EgoMotionRaw_ABSActive 1;
BA_ "GenSigStartValue" SG_ 277 EgoMotionRaw_ABSActive 3;
BA_ "GenSigSendType" SG_ 277 EgoMotionRaw_AccPedalPos 1;
BA_ "GenSigStartValue" SG_ 277 EgoMotionRaw_AccPedalPos 255;
BA_ "GenSigSendType" SG_ 277 EgoMotionRaw_YCEngineActive 1;
BA_ "GenSigStartValue" SG_ 277 EgoMotionRaw_YCEngineActive 3;
BA_ "GenSigSendType" SG_ 277 EgoMotionRaw_RAxleRightWSpeed 1;
BA_ "GenSigStartValue" SG_ 277 EgoMotionRaw_RAxleRightWSpeed 65535;
BA_ "GenSigSendType" SG_ 277 EgoMotionRaw_ASRBrakeA 1;
BA_ "GenSigStartValue" SG_ 277 EgoMotionRaw_ASRBrakeA 3;
BA_ "GenSigSendType" SG_ 277 EgoMotionRaw_RelLvlFrAxleRight 1;
BA_ "GenSigStartValue" SG_ 277 EgoMotionRaw_RelLvlFrAxleRight 65535;
BA_ "GenSigSendType" SG_ 277 EgoMotionRaw_VDCFullyOperational 1;
BA_ "GenSigStartValue" SG_ 277 EgoMotionRaw_VDCFullyOperational 3;
BA_ "GenSigSendType" SG_ 277 EgoMotionRaw_TrailerConStatus 1;
BA_ "GenSigStartValue" SG_ 277 EgoMotionRaw_TrailerConStatus 15;
BA_ "GenSigSendType" SG_ 277 EgoMotionRaw_YCBrakeActive 1;
BA_ "GenSigStartValue" SG_ 277 EgoMotionRaw_YCBrakeActive 3;
BA_ "GenSigSendType" SG_ 277 EgoMotionRaw_ASREngineA 1;
BA_ "GenSigStartValue" SG_ 277 EgoMotionRaw_ASREngineA 3;
BA_ "GenSigSendType" SG_ 277 EgoMotionRaw_RelLvlRrAxleLeft 1;
BA_ "GenSigStartValue" SG_ 277 EgoMotionRaw_RelLvlRrAxleLeft 65535;
BA_ "GenSigSendType" SG_ 277 EgoMotionRaw_Counter 1;
BA_ "GenSigStartValue" SG_ 277 EgoMotionRaw_Counter 255;
BA_ "GenSigSendType" SG_ 277 EgoMotionRaw_ROPBrakeActive 1;
BA_ "GenSigStartValue" SG_ 277 EgoMotionRaw_ROPBrakeActive 3;
BA_ "GenSigSendType" SG_ 277 EgoMotionRaw_CRC 1;
BA_ "GenSigStartValue" SG_ 277 EgoMotionRaw_CRC 65535;
BA_ "E2EDataId" SG_ 277 EgoMotionRaw_CRC 74;
BA_ "E2EDataLength" SG_ 277 EgoMotionRaw_CRC 248;
BA_ "E2EProfile" SG_ 277 EgoMotionRaw_CRC "P05";
BA_ "GenSigSendType" SG_ 277 EgoMotionRaw_RAxleLeftWSpeed 1;
BA_ "GenSigStartValue" SG_ 277 EgoMotionRaw_RAxleLeftWSpeed 65535;
BA_ "GenSigSendType" SG_ 277 EgoMotionRaw_ABSOp 1;
BA_ "GenSigStartValue" SG_ 277 EgoMotionRaw_ABSOp 3;
BA_ "GenSigCycleTime" SG_ 1543 VIN_DACU_Byte08 100;
BA_ "GenSigCycleTimeActive" SG_ 1543 VIN_DACU_Byte08 100;
BA_ "GenSigCycleTime" SG_ 1543 VIN_DACU_Byte01 100;
BA_ "GenSigCycleTimeActive" SG_ 1543 VIN_DACU_Byte01 100;
BA_ "GenSigCycleTime" SG_ 1543 VIN_DACU_Byte13 100;
BA_ "GenSigCycleTimeActive" SG_ 1543 VIN_DACU_Byte13 100;
BA_ "GenSigCycleTime" SG_ 1543 CountryCodeLocal_Code 100;
BA_ "GenSigCycleTimeActive" SG_ 1543 CountryCodeLocal_Code 100;
BA_ "GenSigStartValue" SG_ 1543 CountryCodeLocal_Code 65535;
BA_ "GenSigCycleTime" SG_ 1543 VIN_DACU_Byte06 100;
BA_ "GenSigCycleTimeActive" SG_ 1543 VIN_DACU_Byte06 100;
BA_ "GenSigCycleTime" SG_ 1543 VIN_DACU_Byte03 100;
BA_ "GenSigCycleTimeActive" SG_ 1543 VIN_DACU_Byte03 100;
BA_ "GenSigCycleTime" SG_ 1543 VIN_DACU_Byte15 100;
BA_ "GenSigCycleTimeActive" SG_ 1543 VIN_DACU_Byte15 100;
BA_ "GenSigCycleTime" SG_ 1543 VIN_DACU_Byte16 100;
BA_ "GenSigCycleTimeActive" SG_ 1543 VIN_DACU_Byte16 100;
BA_ "GenSigCycleTime" SG_ 1543 CountryCodeLocal_Counter 100;
BA_ "GenSigCycleTimeActive" SG_ 1543 CountryCodeLocal_Counter 100;
BA_ "GenSigStartValue" SG_ 1543 CountryCodeLocal_Counter 255;
BA_ "GenSigCycleTime" SG_ 1543 VIN_DACU_Byte09 100;
BA_ "GenSigCycleTimeActive" SG_ 1543 VIN_DACU_Byte09 100;
BA_ "GenSigCycleTime" SG_ 1543 VIN_DACU_Byte04 100;
BA_ "GenSigCycleTimeActive" SG_ 1543 VIN_DACU_Byte04 100;
BA_ "GenSigCycleTime" SG_ 1543 CountryCodeLocal_CRC 100;
BA_ "GenSigCycleTimeActive" SG_ 1543 CountryCodeLocal_CRC 100;
BA_ "GenSigStartValue" SG_ 1543 CountryCodeLocal_CRC 65535;
BA_ "E2EDataId" SG_ 1543 CountryCodeLocal_CRC 177;
BA_ "E2EDataLength" SG_ 1543 CountryCodeLocal_CRC 40;
BA_ "E2EProfile" SG_ 1543 CountryCodeLocal_CRC "P05";
BA_ "GenSigCycleTime" SG_ 1543 VIN_DACU_Byte02 100;
BA_ "GenSigCycleTimeActive" SG_ 1543 VIN_DACU_Byte02 100;
BA_ "GenSigCycleTime" SG_ 1543 VIN_DACU_Byte14 100;
BA_ "GenSigCycleTimeActive" SG_ 1543 VIN_DACU_Byte14 100;
BA_ "GenSigCycleTime" SG_ 1543 VIN_DACU_Byte12 100;
BA_ "GenSigCycleTimeActive" SG_ 1543 VIN_DACU_Byte12 100;
BA_ "GenSigCycleTime" SG_ 1543 VIN_DACU_Byte10 100;
BA_ "GenSigCycleTimeActive" SG_ 1543 VIN_DACU_Byte10 100;
BA_ "GenSigCycleTime" SG_ 1543 VIN_DACU_Byte11 100;
BA_ "GenSigCycleTimeActive" SG_ 1543 VIN_DACU_Byte11 100;
BA_ "GenSigCycleTime" SG_ 1543 RegionCode 100;
BA_ "GenSigCycleTimeActive" SG_ 1543 RegionCode 100;
BA_ "GenSigStartValue" SG_ 1543 RegionCode 7;
BA_ "GenSigCycleTime" SG_ 1543 VIN_DACU_Byte00 100;
BA_ "GenSigCycleTimeActive" SG_ 1543 VIN_DACU_Byte00 100;
BA_ "GenSigCycleTime" SG_ 1543 VIN_DACU_Byte07 100;
BA_ "GenSigCycleTimeActive" SG_ 1543 VIN_DACU_Byte07 100;
BA_ "GenSigCycleTime" SG_ 1543 VIN_DACU_Byte05 100;
BA_ "GenSigCycleTimeActive" SG_ 1543 VIN_DACU_Byte05 100;
BA_ "GenSigCycleTime" SG_ 1265 VideoOutConfFLC_StreamActivation 100;
BA_ "GenSigCycleTimeActive" SG_ 1265 VideoOutConfFLC_StreamActivation 100;
BA_ "GenSigStartValue" SG_ 1265 VideoOutConfFLC_StreamActivation 3;
BA_ "GenSigCycleTime" SG_ 1265 MainBeamRequest_status 100;
BA_ "GenSigCycleTimeActive" SG_ 1265 MainBeamRequest_status 100;
BA_ "GenSigStartValue" SG_ 1265 MainBeamRequest_status 3;
BA_ "GenSigCycleTime" SG_ 1265 HoursUTC 100;
BA_ "GenSigCycleTimeActive" SG_ 1265 HoursUTC 100;
BA_ "GenSigStartValue" SG_ 1265 HoursUTC 255;
BA_ "SeToolAncestorID_SIGNAL" SG_ 1265 HoursUTC "x0000001D0412FAC2";
BA_ "SeToolItemID_SIGNAL" SG_ 1265 HoursUTC "x0000001D041EBD20";
BA_ "SeToolName_SIGNAL" SG_ 1265 HoursUTC "HoursUTC";
BA_ "SeToolVersion_SIGNAL" SG_ 1265 HoursUTC "2";
BA_ "GenSigCycleTime" SG_ 1265 YearUTC 100;
BA_ "GenSigCycleTimeActive" SG_ 1265 YearUTC 100;
BA_ "GenSigStartValue" SG_ 1265 YearUTC 255;
BA_ "SeToolAncestorID_SIGNAL" SG_ 1265 YearUTC "x0000001D0412FACB";
BA_ "SeToolItemID_SIGNAL" SG_ 1265 YearUTC "x0000001D041EBCEF";
BA_ "SeToolName_SIGNAL" SG_ 1265 YearUTC "YearUTC";
BA_ "SeToolVersion_SIGNAL" SG_ 1265 YearUTC "2";
BA_ "GenSigCycleTime" SG_ 1265 TimeSynchStat_DACU 100;
BA_ "GenSigCycleTimeActive" SG_ 1265 TimeSynchStat_DACU 100;
BA_ "GenSigCycleTime" SG_ 1265 MinutesUTC 100;
BA_ "GenSigCycleTimeActive" SG_ 1265 MinutesUTC 100;
BA_ "GenSigStartValue" SG_ 1265 MinutesUTC 255;
BA_ "SeToolAncestorID_SIGNAL" SG_ 1265 MinutesUTC "x0000001D0412FAC0";
BA_ "SeToolItemID_SIGNAL" SG_ 1265 MinutesUTC "x0000001D041EBD29";
BA_ "SeToolName_SIGNAL" SG_ 1265 MinutesUTC "MinutesUTC";
BA_ "SeToolVersion_SIGNAL" SG_ 1265 MinutesUTC "2";
BA_ "GenSigCycleTime" SG_ 1265 TachographLocalHourOffset 100;
BA_ "GenSigCycleTimeActive" SG_ 1265 TachographLocalHourOffset 100;
BA_ "GenSigStartValue" SG_ 1265 TachographLocalHourOffset 255;
BA_ "GenSigCycleTime" SG_ 1265 CameraLoggingTrigger 100;
BA_ "GenSigCycleTimeActive" SG_ 1265 CameraLoggingTrigger 100;
BA_ "GenSigStartValue" SG_ 1265 CameraLoggingTrigger 7;
BA_ "GenSigCycleTime" SG_ 1265 DriverRetarderRequest 100;
BA_ "GenSigCycleTimeActive" SG_ 1265 DriverRetarderRequest 100;
BA_ "GenSigStartValue" SG_ 1265 DriverRetarderRequest 7;
BA_ "SeToolAncestorID_SIGNAL" SG_ 1265 DriverRetarderRequest "x0000001D0414BEA2";
BA_ "SeToolItemID_SIGNAL" SG_ 1265 DriverRetarderRequest "x0000001D043806A5";
BA_ "SeToolName_SIGNAL" SG_ 1265 DriverRetarderRequest "DriverRetarderRequest";
BA_ "SeToolVersion_SIGNAL" SG_ 1265 DriverRetarderRequest "2";
BA_ "GenSigCycleTime" SG_ 1265 LaneChangeStatus 100;
BA_ "GenSigCycleTimeActive" SG_ 1265 LaneChangeStatus 100;
BA_ "GenSigStartValue" SG_ 1265 LaneChangeStatus 15;
BA_ "GenSigCycleTime" SG_ 1265 FogLight_Front_cmd 100;
BA_ "GenSigCycleTimeActive" SG_ 1265 FogLight_Front_cmd 100;
BA_ "GenSigStartValue" SG_ 1265 FogLight_Front_cmd 3;
BA_ "SeToolAncestorID_SIGNAL" SG_ 1265 FogLight_Front_cmd "x0000001D04135140";
BA_ "SeToolItemID_SIGNAL" SG_ 1265 FogLight_Front_cmd "x0000001D04384FD1";
BA_ "SeToolName_SIGNAL" SG_ 1265 FogLight_Front_cmd "FogLight_Front_cmd";
BA_ "SeToolVersion_SIGNAL" SG_ 1265 FogLight_Front_cmd "2";
BA_ "GenSigCycleTime" SG_ 1265 TrailerConnected 100;
BA_ "GenSigCycleTimeActive" SG_ 1265 TrailerConnected 100;
BA_ "GenSigStartValue" SG_ 1265 TrailerConnected 3;
BA_ "GenSigCycleTime" SG_ 1265 MonthUTC 100;
BA_ "GenSigCycleTimeActive" SG_ 1265 MonthUTC 100;
BA_ "GenSigStartValue" SG_ 1265 MonthUTC 255;
BA_ "SeToolAncestorID_SIGNAL" SG_ 1265 MonthUTC "x0000001D0412FAC9";
BA_ "SeToolItemID_SIGNAL" SG_ 1265 MonthUTC "x0000001D041EBD16";
BA_ "SeToolName_SIGNAL" SG_ 1265 MonthUTC "MonthUTC";
BA_ "SeToolVersion_SIGNAL" SG_ 1265 MonthUTC "2";
BA_ "GenSigCycleTime" SG_ 1265 AmbientAirTemperature 100;
BA_ "GenSigCycleTimeActive" SG_ 1265 AmbientAirTemperature 100;
BA_ "GenSigStartValue" SG_ 1265 AmbientAirTemperature 65535;
BA_ "SeToolAncestorID_SIGNAL" SG_ 1265 AmbientAirTemperature "x0000001D040FEBC8";
BA_ "SeToolItemID_SIGNAL" SG_ 1265 AmbientAirTemperature "x0000001D040FEBC8";
BA_ "SeToolName_SIGNAL" SG_ 1265 AmbientAirTemperature "AmbientAirTemperature";
BA_ "SeToolVersion_SIGNAL" SG_ 1265 AmbientAirTemperature "1";
BA_ "GenSigCycleTime" SG_ 1265 SecondsUTC 100;
BA_ "GenSigCycleTimeActive" SG_ 1265 SecondsUTC 100;
BA_ "GenSigStartValue" SG_ 1265 SecondsUTC 255;
BA_ "SeToolAncestorID_SIGNAL" SG_ 1265 SecondsUTC "x0000001D0412FABE";
BA_ "SeToolItemID_SIGNAL" SG_ 1265 SecondsUTC "x0000001D041EBD32";
BA_ "SeToolName_SIGNAL" SG_ 1265 SecondsUTC "SecondsUTC";
BA_ "SeToolVersion_SIGNAL" SG_ 1265 SecondsUTC "2";
BA_ "GenSigCycleTime" SG_ 1265 DayUTC 100;
BA_ "GenSigCycleTimeActive" SG_ 1265 DayUTC 100;
BA_ "GenSigStartValue" SG_ 1265 DayUTC 255;
BA_ "SeToolAncestorID_SIGNAL" SG_ 1265 DayUTC "x0000001D0412FAC4";
BA_ "SeToolItemID_SIGNAL" SG_ 1265 DayUTC "x0000001D041EBD81";
BA_ "SeToolName_SIGNAL" SG_ 1265 DayUTC "DayUTC";
BA_ "SeToolVersion_SIGNAL" SG_ 1265 DayUTC "2";
BA_ "GenSigCycleTime" SG_ 1265 VideoOutConfFLC_Framerate 100;
BA_ "GenSigCycleTimeActive" SG_ 1265 VideoOutConfFLC_Framerate 100;
BA_ "GenSigCycleTime" SG_ 1265 TotalVehicleDistanceHighRes 100;
BA_ "GenSigCycleTimeActive" SG_ 1265 TotalVehicleDistanceHighRes 100;
BA_ "GenSigStartValue" SG_ 1265 TotalVehicleDistanceHighRes 4294967295;
BA_ "SeToolAncestorID_SIGNAL" SG_ 1265 TotalVehicleDistanceHighRes "x0000001D04109E2B";
BA_ "SeToolItemID_SIGNAL" SG_ 1265 TotalVehicleDistanceHighRes "x0000001D04109E2B";
BA_ "SeToolName_SIGNAL" SG_ 1265 TotalVehicleDistanceHighRes "HighResolutionTotalVehicleDistance";
BA_ "SeToolVersion_SIGNAL" SG_ 1265 TotalVehicleDistanceHighRes "1";
BA_ "GenSigCycleTime" SG_ 1265 WiperModeStatus 100;
BA_ "GenSigCycleTimeActive" SG_ 1265 WiperModeStatus 100;
BA_ "GenSigStartValue" SG_ 1265 WiperModeStatus 7;
BA_ "SeToolAncestorID_SIGNAL" SG_ 1265 WiperModeStatus "x0000001D0410D271";
BA_ "SeToolItemID_SIGNAL" SG_ 1265 WiperModeStatus "x0000001D0410D271";
BA_ "SeToolName_SIGNAL" SG_ 1265 WiperModeStatus "WiperModeStatus";
BA_ "SeToolVersion_SIGNAL" SG_ 1265 WiperModeStatus "1";
BA_ "GenSigCycleTime" SG_ 1265 TachographLocalMinuteOffset 100;
BA_ "GenSigCycleTimeActive" SG_ 1265 TachographLocalMinuteOffset 100;
BA_ "GenSigStartValue" SG_ 1265 TachographLocalMinuteOffset 255;
BA_ "GenSigCycleTime" SG_ 1265 FLCPowerDemand 100;
BA_ "GenSigCycleTimeActive" SG_ 1265 FLCPowerDemand 100;
BA_ "GenSigStartValue" SG_ 1265 FLCPowerDemand 7;
BA_ "GenSigCycleTime" SG_ 1552 DACUSwVersion_Substring4 100;
BA_ "GenSigCycleTimeActive" SG_ 1552 DACUSwVersion_Substring4 100;
BA_ "GenSigCycleTime" SG_ 1552 DACUSwVersion_Substring5 100;
BA_ "GenSigCycleTimeActive" SG_ 1552 DACUSwVersion_Substring5 100;
BA_ "GenSigCycleTime" SG_ 1552 DACUSwVersion_Substring2 100;
BA_ "GenSigCycleTimeActive" SG_ 1552 DACUSwVersion_Substring2 100;
BA_ "GenSigCycleTime" SG_ 1552 DACUSwVersion_Substring7 100;
BA_ "GenSigCycleTimeActive" SG_ 1552 DACUSwVersion_Substring7 100;
BA_ "GenSigCycleTime" SG_ 1552 DACUSwVersion_Substring6 100;
BA_ "GenSigCycleTimeActive" SG_ 1552 DACUSwVersion_Substring6 100;
BA_ "GenSigCycleTime" SG_ 1552 DACUSwVersion_Substring3 100;
BA_ "GenSigCycleTimeActive" SG_ 1552 DACUSwVersion_Substring3 100;
BA_ "GenSigCycleTime" SG_ 1552 DACUSwVersion_Substring1 100;
BA_ "GenSigCycleTimeActive" SG_ 1552 DACUSwVersion_Substring1 100;
BA_ "GenSigCycleTime" SG_ 1552 DACUSwVersion_Substring0 100;
BA_ "GenSigCycleTimeActive" SG_ 1552 DACUSwVersion_Substring0 100;
BA_ "GenSigSendType" SG_ 597 AdasisMapData 1;
BA_REL_ "GenSigFirstTimeoutTime" BU_SG_REL_ DACU SG_ 788 FLCObject04_LatVel 3000;
BA_REL_ "GenSigTimeoutTime" BU_SG_REL_ DACU SG_ 788 FLCObject04_LatVel 120;
BA_REL_ "GenSigFirstTimeoutTime" BU_SG_REL_ DACU SG_ 788 FLCObject04_LatVelVar 3000;
BA_REL_ "GenSigTimeoutTime" BU_SG_REL_ DACU SG_ 788 FLCObject04_LatVelVar 120;
BA_REL_ "GenSigFirstTimeoutTime" BU_SG_REL_ DACU SG_ 788 FLCObject04_CoastIndex 3000;
BA_REL_ "GenSigTimeoutTime" BU_SG_REL_ DACU SG_ 788 FLCObject04_CoastIndex 120;
BA_REL_ "GenSigFirstTimeoutTime" BU_SG_REL_ DACU SG_ 788 FLCObject04_LifeTime 3000;
BA_REL_ "GenSigTimeoutTime" BU_SG_REL_ DACU SG_ 788 FLCObject04_LifeTime 120;
BA_REL_ "GenSigFirstTimeoutTime" BU_SG_REL_ DACU SG_ 788 FLCObject04_DistFarCorner 3000;
BA_REL_ "GenSigTimeoutTime" BU_SG_REL_ DACU SG_ 788 FLCObject04_DistFarCorner 120;
BA_REL_ "GenSigFirstTimeoutTime" BU_SG_REL_ DACU SG_ 788 FLCObject04_TurnIndication 3000;
BA_REL_ "GenSigTimeoutTime" BU_SG_REL_ DACU SG_ 788 FLCObject04_TurnIndication 120;
BA_REL_ "GenSigFirstTimeoutTime" BU_SG_REL_ DACU SG_ 788 FLCObject04_AnglLeftCorner 3000;
BA_REL_ "GenSigTimeoutTime" BU_SG_REL_ DACU SG_ 788 FLCObject04_AnglLeftCorner 120;
BA_REL_ "GenSigFirstTimeoutTime" BU_SG_REL_ DACU SG_ 788 FLCObject04_CRC 3000;
BA_REL_ "GenSigTimeoutTime" BU_SG_REL_ DACU SG_ 788 FLCObject04_CRC 120;
BA_REL_ "GenSigFirstTimeoutTime" BU_SG_REL_ DACU SG_ 788 FLCObject04_LatPos 3000;
BA_REL_ "GenSigTimeoutTime" BU_SG_REL_ DACU SG_ 788 FLCObject04_LatPos 120;
BA_REL_ "GenSigFirstTimeoutTime" BU_SG_REL_ DACU SG_ 788 FLCObject04_DstRightVar 3000;
BA_REL_ "GenSigTimeoutTime" BU_SG_REL_ DACU SG_ 788 FLCObject04_DstRightVar 120;
BA_REL_ "GenSigFirstTimeoutTime" BU_SG_REL_ DACU SG_ 788 FLCObject04_Height 3000;
BA_REL_ "GenSigTimeoutTime" BU_SG_REL_ DACU SG_ 788 FLCObject04_Height 120;
BA_REL_ "GenSigFirstTimeoutTime" BU_SG_REL_ DACU SG_ 788 FLCObject04_LongVel 3000;
BA_REL_ "GenSigTimeoutTime" BU_SG_REL_ DACU SG_ 788 FLCObject04_LongVel 120;
BA_REL_ "GenSigFirstTimeoutTime" BU_SG_REL_ DACU SG_ 788 FLCObject04_ExistConf 3000;
BA_REL_ "GenSigTimeoutTime" BU_SG_REL_ DACU SG_ 788 FLCObject04_ExistConf 120;
BA_REL_ "GenSigFirstTimeoutTime" BU_SG_REL_ DACU SG_ 788 FLCObject04_DstFarVar 3000;
BA_REL_ "GenSigTimeoutTime" BU_SG_REL_ DACU SG_ 788 FLCObject04_DstFarVar 120;
BA_REL_ "GenSigFirstTimeoutTime" BU_SG_REL_ DACU SG_ 788 FLCObject04_ObjClass 3000;
BA_REL_ "GenSigTimeoutTime" BU_SG_REL_ DACU SG_ 788 FLCObject04_ObjClass 120;
BA_REL_ "GenSigFirstTimeoutTime" BU_SG_REL_ DACU SG_ 788 FLCObject04_AngLeftVar 3000;
BA_REL_ "GenSigTimeoutTime" BU_SG_REL_ DACU SG_ 788 FLCObject04_AngLeftVar 120;
BA_REL_ "GenSigFirstTimeoutTime" BU_SG_REL_ DACU SG_ 788 FLCObject04_ScaleChange 3000;
BA_REL_ "GenSigTimeoutTime" BU_SG_REL_ DACU SG_ 788 FLCObject04_ScaleChange 120;
BA_REL_ "GenSigFirstTimeoutTime" BU_SG_REL_ DACU SG_ 788 FLCObject04_AnglRightCorner 3000;
BA_REL_ "GenSigTimeoutTime" BU_SG_REL_ DACU SG_ 788 FLCObject04_AnglRightCorner 120;
BA_REL_ "GenSigFirstTimeoutTime" BU_SG_REL_ DACU SG_ 788 FLCObject04_LongPosVar 3000;
BA_REL_ "GenSigTimeoutTime" BU_SG_REL_ DACU SG_ 788 FLCObject04_LongPosVar 120;
BA_REL_ "GenSigFirstTimeoutTime" BU_SG_REL_ DACU SG_ 788 FLCObject04_LongAcc 3000;
BA_REL_ "GenSigTimeoutTime" BU_SG_REL_ DACU SG_ 788 FLCObject04_LongAcc 120;
BA_REL_ "GenSigFirstTimeoutTime" BU_SG_REL_ DACU SG_ 788 FLCObject04_ObjDynClass 3000;
BA_REL_ "GenSigTimeoutTime" BU_SG_REL_ DACU SG_ 788 FLCObject04_ObjDynClass 120;
BA_REL_ "GenSigFirstTimeoutTime" BU_SG_REL_ DACU SG_ 788 FLCObject04_Counter 3000;
BA_REL_ "GenSigTimeoutTime" BU_SG_REL_ DACU SG_ 788 FLCObject04_Counter 120;
BA_REL_ "GenSigFirstTimeoutTime" BU_SG_REL_ DACU SG_ 788 FLCObject04_ObjID 3000;
BA_REL_ "GenSigTimeoutTime" BU_SG_REL_ DACU SG_ 788 FLCObject04_ObjID 120;
BA_REL_ "GenSigFirstTimeoutTime" BU_SG_REL_ DACU SG_ 788 FLCObject04_TrackStatus 3000;
BA_REL_ "GenSigTimeoutTime" BU_SG_REL_ DACU SG_ 788 FLCObject04_TrackStatus 120;
BA_REL_ "GenSigFirstTimeoutTime" BU_SG_REL_ DACU SG_ 788 FLCObject04_AngRightVar 3000;
BA_REL_ "GenSigTimeoutTime" BU_SG_REL_ DACU SG_ 788 FLCObject04_AngRightVar 120;
BA_REL_ "GenSigFirstTimeoutTime" BU_SG_REL_ DACU SG_ 788 FLCObject04_DistLeftCorner 3000;
BA_REL_ "GenSigTimeoutTime" BU_SG_REL_ DACU SG_ 788 FLCObject04_DistLeftCorner 120;
BA_REL_ "GenSigFirstTimeoutTime" BU_SG_REL_ DACU SG_ 788 FLCObject04_Heading 3000;
BA_REL_ "GenSigTimeoutTime" BU_SG_REL_ DACU SG_ 788 FLCObject04_Heading 120;
BA_REL_ "GenSigFirstTimeoutTime" BU_SG_REL_ DACU SG_ 788 FLCObject04_BrakeLight 3000;
BA_REL_ "GenSigTimeoutTime" BU_SG_REL_ DACU SG_ 788 FLCObject04_BrakeLight 120;
BA_REL_ "GenSigFirstTimeoutTime" BU_SG_REL_ DACU SG_ 788 FLCObject04_DistRightCorner 3000;
BA_REL_ "GenSigTimeoutTime" BU_SG_REL_ DACU SG_ 788 FLCObject04_DistRightCorner 120;
BA_REL_ "GenSigFirstTimeoutTime" BU_SG_REL_ DACU SG_ 788 FLCObject04_AnglFarCorner 3000;
BA_REL_ "GenSigTimeoutTime" BU_SG_REL_ DACU SG_ 788 FLCObject04_AnglFarCorner 120;
BA_REL_ "GenSigFirstTimeoutTime" BU_SG_REL_ DACU SG_ 788 FLCObject04_AngFarVar 3000;
BA_REL_ "GenSigTimeoutTime" BU_SG_REL_ DACU SG_ 788 FLCObject04_AngFarVar 120;
BA_REL_ "GenSigFirstTimeoutTime" BU_SG_REL_ DACU SG_ 788 FLCObject04_DstLeftVar 3000;
BA_REL_ "GenSigTimeoutTime" BU_SG_REL_ DACU SG_ 788 FLCObject04_DstLeftVar 120;
BA_REL_ "GenSigFirstTimeoutTime" BU_SG_REL_ DACU SG_ 788 FLCObject04_LatAcc 3000;
BA_REL_ "GenSigTimeoutTime" BU_SG_REL_ DACU SG_ 788 FLCObject04_LatAcc 120;
BA_REL_ "GenSigFirstTimeoutTime" BU_SG_REL_ DACU SG_ 788 FLCObject04_TargetToLine 3000;
BA_REL_ "GenSigTimeoutTime" BU_SG_REL_ DACU SG_ 788 FLCObject04_TargetToLine 120;
BA_REL_ "GenSigFirstTimeoutTime" BU_SG_REL_ DACU SG_ 788 FLCObject04_LongVelVar 3000;
BA_REL_ "GenSigTimeoutTime" BU_SG_REL_ DACU SG_ 788 FLCObject04_LongVelVar 120;
BA_REL_ "GenSigFirstTimeoutTime" BU_SG_REL_ DACU SG_ 788 FLCObject04_LatPosVar 3000;
BA_REL_ "GenSigTimeoutTime" BU_SG_REL_ DACU SG_ 788 FLCObject04_LatPosVar 120;
BA_REL_ "GenSigFirstTimeoutTime" BU_SG_REL_ DACU SG_ 788 FLCObject04_TimeStamp 3000;
BA_REL_ "GenSigTimeoutTime" BU_SG_REL_ DACU SG_ 788 FLCObject04_TimeStamp 120;
BA_REL_ "GenSigFirstTimeoutTime" BU_SG_REL_ DACU SG_ 788 FLCObject04_LongPos 3000;
BA_REL_ "GenSigTimeoutTime" BU_SG_REL_ DACU SG_ 788 FLCObject04_LongPos 120;
BA_REL_ "GenSigFirstTimeoutTime" BU_SG_REL_ DACU SG_ 788 FLCObject04_ReliabilityConf 3000;
BA_REL_ "GenSigTimeoutTime" BU_SG_REL_ DACU SG_ 788 FLCObject04_ReliabilityConf 120;
BA_REL_ "GenSigFirstTimeoutTime" BU_SG_REL_ DACU SG_ 788 FLCObject04_HeadingVar 3000;
BA_REL_ "GenSigTimeoutTime" BU_SG_REL_ DACU SG_ 788 FLCObject04_HeadingVar 120;
BA_REL_ "GenSigFirstTimeoutTime" BU_SG_REL_ DACU SG_ 787 FLCObject03_Height 3000;
BA_REL_ "GenSigTimeoutTime" BU_SG_REL_ DACU SG_ 787 FLCObject03_Height 120;
BA_REL_ "GenSigFirstTimeoutTime" BU_SG_REL_ DACU SG_ 787 FLCObject03_LatAcc 3000;
BA_REL_ "GenSigTimeoutTime" BU_SG_REL_ DACU SG_ 787 FLCObject03_LatAcc 120;
BA_REL_ "GenSigFirstTimeoutTime" BU_SG_REL_ DACU SG_ 787 FLCObject03_LatVelVar 3000;
BA_REL_ "GenSigTimeoutTime" BU_SG_REL_ DACU SG_ 787 FLCObject03_LatVelVar 120;
BA_REL_ "GenSigFirstTimeoutTime" BU_SG_REL_ DACU SG_ 787 FLCObject03_TrackStatus 3000;
BA_REL_ "GenSigTimeoutTime" BU_SG_REL_ DACU SG_ 787 FLCObject03_TrackStatus 120;
BA_REL_ "GenSigFirstTimeoutTime" BU_SG_REL_ DACU SG_ 787 FLCObject03_LifeTime 3000;
BA_REL_ "GenSigTimeoutTime" BU_SG_REL_ DACU SG_ 787 FLCObject03_LifeTime 120;
BA_REL_ "GenSigFirstTimeoutTime" BU_SG_REL_ DACU SG_ 787 FLCObject03_AnglFarCorner 3000;
BA_REL_ "GenSigTimeoutTime" BU_SG_REL_ DACU SG_ 787 FLCObject03_AnglFarCorner 120;
BA_REL_ "GenSigFirstTimeoutTime" BU_SG_REL_ DACU SG_ 787 FLCObject03_LongAcc 3000;
BA_REL_ "GenSigTimeoutTime" BU_SG_REL_ DACU SG_ 787 FLCObject03_LongAcc 120;
BA_REL_ "GenSigFirstTimeoutTime" BU_SG_REL_ DACU SG_ 787 FLCObject03_Heading 3000;
BA_REL_ "GenSigTimeoutTime" BU_SG_REL_ DACU SG_ 787 FLCObject03_Heading 120;
BA_REL_ "GenSigFirstTimeoutTime" BU_SG_REL_ DACU SG_ 787 FLCObject03_AngFarVar 3000;
BA_REL_ "GenSigTimeoutTime" BU_SG_REL_ DACU SG_ 787 FLCObject03_AngFarVar 120;
BA_REL_ "GenSigFirstTimeoutTime" BU_SG_REL_ DACU SG_ 787 FLCObject03_LongPosVar 3000;
BA_REL_ "GenSigTimeoutTime" BU_SG_REL_ DACU SG_ 787 FLCObject03_LongPosVar 120;
BA_REL_ "GenSigFirstTimeoutTime" BU_SG_REL_ DACU SG_ 787 FLCObject03_LatPos 3000;
BA_REL_ "GenSigTimeoutTime" BU_SG_REL_ DACU SG_ 787 FLCObject03_LatPos 120;
BA_REL_ "GenSigFirstTimeoutTime" BU_SG_REL_ DACU SG_ 787 FLCObject03_ScaleChange 3000;
BA_REL_ "GenSigTimeoutTime" BU_SG_REL_ DACU SG_ 787 FLCObject03_ScaleChange 120;
BA_REL_ "GenSigFirstTimeoutTime" BU_SG_REL_ DACU SG_ 787 FLCObject03_LongVelVar 3000;
BA_REL_ "GenSigTimeoutTime" BU_SG_REL_ DACU SG_ 787 FLCObject03_LongVelVar 120;
BA_REL_ "GenSigFirstTimeoutTime" BU_SG_REL_ DACU SG_ 787 FLCObject03_LongVel 3000;
BA_REL_ "GenSigTimeoutTime" BU_SG_REL_ DACU SG_ 787 FLCObject03_LongVel 120;
BA_REL_ "GenSigFirstTimeoutTime" BU_SG_REL_ DACU SG_ 787 FLCObject03_DstFarVar 3000;
BA_REL_ "GenSigTimeoutTime" BU_SG_REL_ DACU SG_ 787 FLCObject03_DstFarVar 120;
BA_REL_ "GenSigFirstTimeoutTime" BU_SG_REL_ DACU SG_ 787 FLCObject03_TargetToLine 3000;
BA_REL_ "GenSigTimeoutTime" BU_SG_REL_ DACU SG_ 787 FLCObject03_TargetToLine 120;
BA_REL_ "GenSigFirstTimeoutTime" BU_SG_REL_ DACU SG_ 787 FLCObject03_CoastIndex 3000;
BA_REL_ "GenSigTimeoutTime" BU_SG_REL_ DACU SG_ 787 FLCObject03_CoastIndex 120;
BA_REL_ "GenSigFirstTimeoutTime" BU_SG_REL_ DACU SG_ 787 FLCObject03_DstRightVar 3000;
BA_REL_ "GenSigTimeoutTime" BU_SG_REL_ DACU SG_ 787 FLCObject03_DstRightVar 120;
BA_REL_ "GenSigFirstTimeoutTime" BU_SG_REL_ DACU SG_ 787 FLCObject03_ExistConf 3000;
BA_REL_ "GenSigTimeoutTime" BU_SG_REL_ DACU SG_ 787 FLCObject03_ExistConf 120;
BA_REL_ "GenSigFirstTimeoutTime" BU_SG_REL_ DACU SG_ 787 FLCObject03_LongPos 3000;
BA_REL_ "GenSigTimeoutTime" BU_SG_REL_ DACU SG_ 787 FLCObject03_LongPos 120;
BA_REL_ "GenSigFirstTimeoutTime" BU_SG_REL_ DACU SG_ 787 FLCObject03_AnglRightCorner 3000;
BA_REL_ "GenSigTimeoutTime" BU_SG_REL_ DACU SG_ 787 FLCObject03_AnglRightCorner 120;
BA_REL_ "GenSigFirstTimeoutTime" BU_SG_REL_ DACU SG_ 787 FLCObject03_LatVel 3000;
BA_REL_ "GenSigTimeoutTime" BU_SG_REL_ DACU SG_ 787 FLCObject03_LatVel 120;
BA_REL_ "GenSigFirstTimeoutTime" BU_SG_REL_ DACU SG_ 787 FLCObject03_ObjClass 3000;
BA_REL_ "GenSigTimeoutTime" BU_SG_REL_ DACU SG_ 787 FLCObject03_ObjClass 120;
BA_REL_ "GenSigFirstTimeoutTime" BU_SG_REL_ DACU SG_ 787 FLCObject03_TimeStamp 3000;
BA_REL_ "GenSigTimeoutTime" BU_SG_REL_ DACU SG_ 787 FLCObject03_TimeStamp 120;
BA_REL_ "GenSigFirstTimeoutTime" BU_SG_REL_ DACU SG_ 787 FLCObject03_ObjDynClass 3000;
BA_REL_ "GenSigTimeoutTime" BU_SG_REL_ DACU SG_ 787 FLCObject03_ObjDynClass 120;
BA_REL_ "GenSigFirstTimeoutTime" BU_SG_REL_ DACU SG_ 787 FLCObject03_CRC 3000;
BA_REL_ "GenSigTimeoutTime" BU_SG_REL_ DACU SG_ 787 FLCObject03_CRC 120;
BA_REL_ "GenSigFirstTimeoutTime" BU_SG_REL_ DACU SG_ 787 FLCObject03_AnglLeftCorner 3000;
BA_REL_ "GenSigTimeoutTime" BU_SG_REL_ DACU SG_ 787 FLCObject03_AnglLeftCorner 120;
BA_REL_ "GenSigFirstTimeoutTime" BU_SG_REL_ DACU SG_ 787 FLCObject03_ReliabilityConf 3000;
BA_REL_ "GenSigTimeoutTime" BU_SG_REL_ DACU SG_ 787 FLCObject03_ReliabilityConf 120;
BA_REL_ "GenSigFirstTimeoutTime" BU_SG_REL_ DACU SG_ 787 FLCObject03_DistLeftCorner 3000;
BA_REL_ "GenSigTimeoutTime" BU_SG_REL_ DACU SG_ 787 FLCObject03_DistLeftCorner 120;
BA_REL_ "GenSigFirstTimeoutTime" BU_SG_REL_ DACU SG_ 787 FLCObject03_DstLeftVar 3000;
BA_REL_ "GenSigTimeoutTime" BU_SG_REL_ DACU SG_ 787 FLCObject03_DstLeftVar 120;
BA_REL_ "GenSigFirstTimeoutTime" BU_SG_REL_ DACU SG_ 787 FLCObject03_DistFarCorner 3000;
BA_REL_ "GenSigTimeoutTime" BU_SG_REL_ DACU SG_ 787 FLCObject03_DistFarCorner 120;
BA_REL_ "GenSigFirstTimeoutTime" BU_SG_REL_ DACU SG_ 787 FLCObject03_TurnIndication 3000;
BA_REL_ "GenSigTimeoutTime" BU_SG_REL_ DACU SG_ 787 FLCObject03_TurnIndication 120;
BA_REL_ "GenSigFirstTimeoutTime" BU_SG_REL_ DACU SG_ 787 FLCObject03_LatPosVar 3000;
BA_REL_ "GenSigTimeoutTime" BU_SG_REL_ DACU SG_ 787 FLCObject03_LatPosVar 120;
BA_REL_ "GenSigFirstTimeoutTime" BU_SG_REL_ DACU SG_ 787 FLCObject03_DistRightCorner 3000;
BA_REL_ "GenSigTimeoutTime" BU_SG_REL_ DACU SG_ 787 FLCObject03_DistRightCorner 120;
BA_REL_ "GenSigFirstTimeoutTime" BU_SG_REL_ DACU SG_ 787 FLCObject03_ObjID 3000;
BA_REL_ "GenSigTimeoutTime" BU_SG_REL_ DACU SG_ 787 FLCObject03_ObjID 120;
BA_REL_ "GenSigFirstTimeoutTime" BU_SG_REL_ DACU SG_ 787 FLCObject03_AngLeftVar 3000;
BA_REL_ "GenSigTimeoutTime" BU_SG_REL_ DACU SG_ 787 FLCObject03_AngLeftVar 120;
BA_REL_ "GenSigFirstTimeoutTime" BU_SG_REL_ DACU SG_ 787 FLCObject03_BrakeLight 3000;
BA_REL_ "GenSigTimeoutTime" BU_SG_REL_ DACU SG_ 787 FLCObject03_BrakeLight 120;
BA_REL_ "GenSigFirstTimeoutTime" BU_SG_REL_ DACU SG_ 787 FLCObject03_HeadingVar 3000;
BA_REL_ "GenSigTimeoutTime" BU_SG_REL_ DACU SG_ 787 FLCObject03_HeadingVar 120;
BA_REL_ "GenSigFirstTimeoutTime" BU_SG_REL_ DACU SG_ 787 FLCObject03_Counter 3000;
BA_REL_ "GenSigTimeoutTime" BU_SG_REL_ DACU SG_ 787 FLCObject03_Counter 120;
BA_REL_ "GenSigFirstTimeoutTime" BU_SG_REL_ DACU SG_ 787 FLCObject03_AngRightVar 3000;
BA_REL_ "GenSigTimeoutTime" BU_SG_REL_ DACU SG_ 787 FLCObject03_AngRightVar 120;
BA_REL_ "GenSigFirstTimeoutTime" BU_SG_REL_ DACU SG_ 786 FLCObject02_ScaleChange 3000;
BA_REL_ "GenSigTimeoutTime" BU_SG_REL_ DACU SG_ 786 FLCObject02_ScaleChange 120;
BA_REL_ "GenSigFirstTimeoutTime" BU_SG_REL_ DACU SG_ 786 FLCObject02_Height 3000;
BA_REL_ "GenSigTimeoutTime" BU_SG_REL_ DACU SG_ 786 FLCObject02_Height 120;
BA_REL_ "GenSigFirstTimeoutTime" BU_SG_REL_ DACU SG_ 786 FLCObject02_AnglRightCorner 3000;
BA_REL_ "GenSigTimeoutTime" BU_SG_REL_ DACU SG_ 786 FLCObject02_AnglRightCorner 120;
BA_REL_ "GenSigFirstTimeoutTime" BU_SG_REL_ DACU SG_ 786 FLCObject02_AnglFarCorner 3000;
BA_REL_ "GenSigTimeoutTime" BU_SG_REL_ DACU SG_ 786 FLCObject02_AnglFarCorner 120;
BA_REL_ "GenSigFirstTimeoutTime" BU_SG_REL_ DACU SG_ 786 FLCObject02_DistRightCorner 3000;
BA_REL_ "GenSigTimeoutTime" BU_SG_REL_ DACU SG_ 786 FLCObject02_DistRightCorner 120;
BA_REL_ "GenSigFirstTimeoutTime" BU_SG_REL_ DACU SG_ 786 FLCObject02_LongAcc 3000;
BA_REL_ "GenSigTimeoutTime" BU_SG_REL_ DACU SG_ 786 FLCObject02_LongAcc 120;
BA_REL_ "GenSigFirstTimeoutTime" BU_SG_REL_ DACU SG_ 786 FLCObject02_AngRightVar 3000;
BA_REL_ "GenSigTimeoutTime" BU_SG_REL_ DACU SG_ 786 FLCObject02_AngRightVar 120;
BA_REL_ "GenSigFirstTimeoutTime" BU_SG_REL_ DACU SG_ 786 FLCObject02_CRC 3000;
BA_REL_ "GenSigTimeoutTime" BU_SG_REL_ DACU SG_ 786 FLCObject02_CRC 120;
BA_REL_ "GenSigFirstTimeoutTime" BU_SG_REL_ DACU SG_ 786 FLCObject02_LatAcc 3000;
BA_REL_ "GenSigTimeoutTime" BU_SG_REL_ DACU SG_ 786 FLCObject02_LatAcc 120;
BA_REL_ "GenSigFirstTimeoutTime" BU_SG_REL_ DACU SG_ 786 FLCObject02_TrackStatus 3000;
BA_REL_ "GenSigTimeoutTime" BU_SG_REL_ DACU SG_ 786 FLCObject02_TrackStatus 120;
BA_REL_ "GenSigFirstTimeoutTime" BU_SG_REL_ DACU SG_ 786 FLCObject02_Heading 3000;
BA_REL_ "GenSigTimeoutTime" BU_SG_REL_ DACU SG_ 786 FLCObject02_Heading 120;
BA_REL_ "GenSigFirstTimeoutTime" BU_SG_REL_ DACU SG_ 786 FLCObject02_AnglLeftCorner 3000;
BA_REL_ "GenSigTimeoutTime" BU_SG_REL_ DACU SG_ 786 FLCObject02_AnglLeftCorner 120;
BA_REL_ "GenSigFirstTimeoutTime" BU_SG_REL_ DACU SG_ 786 FLCObject02_LongVelVar 3000;
BA_REL_ "GenSigTimeoutTime" BU_SG_REL_ DACU SG_ 786 FLCObject02_LongVelVar 120;
BA_REL_ "GenSigFirstTimeoutTime" BU_SG_REL_ DACU SG_ 786 FLCObject02_LatPos 3000;
BA_REL_ "GenSigTimeoutTime" BU_SG_REL_ DACU SG_ 786 FLCObject02_LatPos 120;
BA_REL_ "GenSigFirstTimeoutTime" BU_SG_REL_ DACU SG_ 786 FLCObject02_LongPosVar 3000;
BA_REL_ "GenSigTimeoutTime" BU_SG_REL_ DACU SG_ 786 FLCObject02_LongPosVar 120;
BA_REL_ "GenSigFirstTimeoutTime" BU_SG_REL_ DACU SG_ 786 FLCObject02_LatVelVar 3000;
BA_REL_ "GenSigTimeoutTime" BU_SG_REL_ DACU SG_ 786 FLCObject02_LatVelVar 120;
BA_REL_ "GenSigFirstTimeoutTime" BU_SG_REL_ DACU SG_ 786 FLCObject02_LongVel 3000;
BA_REL_ "GenSigTimeoutTime" BU_SG_REL_ DACU SG_ 786 FLCObject02_LongVel 120;
BA_REL_ "GenSigFirstTimeoutTime" BU_SG_REL_ DACU SG_ 786 FLCObject02_ObjDynClass 3000;
BA_REL_ "GenSigTimeoutTime" BU_SG_REL_ DACU SG_ 786 FLCObject02_ObjDynClass 120;
BA_REL_ "GenSigFirstTimeoutTime" BU_SG_REL_ DACU SG_ 786 FLCObject02_TimeStamp 3000;
BA_REL_ "GenSigTimeoutTime" BU_SG_REL_ DACU SG_ 786 FLCObject02_TimeStamp 120;
BA_REL_ "GenSigFirstTimeoutTime" BU_SG_REL_ DACU SG_ 786 FLCObject02_DistFarCorner 3000;
BA_REL_ "GenSigTimeoutTime" BU_SG_REL_ DACU SG_ 786 FLCObject02_DistFarCorner 120;
BA_REL_ "GenSigFirstTimeoutTime" BU_SG_REL_ DACU SG_ 786 FLCObject02_DstFarVar 3000;
BA_REL_ "GenSigTimeoutTime" BU_SG_REL_ DACU SG_ 786 FLCObject02_DstFarVar 120;
BA_REL_ "GenSigFirstTimeoutTime" BU_SG_REL_ DACU SG_ 786 FLCObject02_LifeTime 3000;
BA_REL_ "GenSigTimeoutTime" BU_SG_REL_ DACU SG_ 786 FLCObject02_LifeTime 120;
BA_REL_ "GenSigFirstTimeoutTime" BU_SG_REL_ DACU SG_ 786 FLCObject02_LatVel 3000;
BA_REL_ "GenSigTimeoutTime" BU_SG_REL_ DACU SG_ 786 FLCObject02_LatVel 120;
BA_REL_ "GenSigFirstTimeoutTime" BU_SG_REL_ DACU SG_ 786 FLCObject02_ObjID 3000;
BA_REL_ "GenSigTimeoutTime" BU_SG_REL_ DACU SG_ 786 FLCObject02_ObjID 120;
BA_REL_ "GenSigFirstTimeoutTime" BU_SG_REL_ DACU SG_ 786 FLCObject02_ExistConf 3000;
BA_REL_ "GenSigTimeoutTime" BU_SG_REL_ DACU SG_ 786 FLCObject02_ExistConf 120;
BA_REL_ "GenSigFirstTimeoutTime" BU_SG_REL_ DACU SG_ 786 FLCObject02_DstRightVar 3000;
BA_REL_ "GenSigTimeoutTime" BU_SG_REL_ DACU SG_ 786 FLCObject02_DstRightVar 120;
BA_REL_ "GenSigFirstTimeoutTime" BU_SG_REL_ DACU SG_ 786 FLCObject02_ReliabilityConf 3000;
BA_REL_ "GenSigTimeoutTime" BU_SG_REL_ DACU SG_ 786 FLCObject02_ReliabilityConf 120;
BA_REL_ "GenSigFirstTimeoutTime" BU_SG_REL_ DACU SG_ 786 FLCObject02_DistLeftCorner 3000;
BA_REL_ "GenSigTimeoutTime" BU_SG_REL_ DACU SG_ 786 FLCObject02_DistLeftCorner 120;
BA_REL_ "GenSigFirstTimeoutTime" BU_SG_REL_ DACU SG_ 786 FLCObject02_HeadingVar 3000;
BA_REL_ "GenSigTimeoutTime" BU_SG_REL_ DACU SG_ 786 FLCObject02_HeadingVar 120;
BA_REL_ "GenSigFirstTimeoutTime" BU_SG_REL_ DACU SG_ 786 FLCObject02_TurnIndication 3000;
BA_REL_ "GenSigTimeoutTime" BU_SG_REL_ DACU SG_ 786 FLCObject02_TurnIndication 120;
BA_REL_ "GenSigFirstTimeoutTime" BU_SG_REL_ DACU SG_ 786 FLCObject02_ObjClass 3000;
BA_REL_ "GenSigTimeoutTime" BU_SG_REL_ DACU SG_ 786 FLCObject02_ObjClass 120;
BA_REL_ "GenSigFirstTimeoutTime" BU_SG_REL_ DACU SG_ 786 FLCObject02_LongPos 3000;
BA_REL_ "GenSigTimeoutTime" BU_SG_REL_ DACU SG_ 786 FLCObject02_LongPos 120;
BA_REL_ "GenSigFirstTimeoutTime" BU_SG_REL_ DACU SG_ 786 FLCObject02_DstLeftVar 3000;
BA_REL_ "GenSigTimeoutTime" BU_SG_REL_ DACU SG_ 786 FLCObject02_DstLeftVar 120;
BA_REL_ "GenSigFirstTimeoutTime" BU_SG_REL_ DACU SG_ 786 FLCObject02_AngLeftVar 3000;
BA_REL_ "GenSigTimeoutTime" BU_SG_REL_ DACU SG_ 786 FLCObject02_AngLeftVar 120;
BA_REL_ "GenSigFirstTimeoutTime" BU_SG_REL_ DACU SG_ 786 FLCObject02_BrakeLight 3000;
BA_REL_ "GenSigTimeoutTime" BU_SG_REL_ DACU SG_ 786 FLCObject02_BrakeLight 120;
BA_REL_ "GenSigFirstTimeoutTime" BU_SG_REL_ DACU SG_ 786 FLCObject02_LatPosVar 3000;
BA_REL_ "GenSigTimeoutTime" BU_SG_REL_ DACU SG_ 786 FLCObject02_LatPosVar 120;
BA_REL_ "GenSigFirstTimeoutTime" BU_SG_REL_ DACU SG_ 786 FLCObject02_CoastIndex 3000;
BA_REL_ "GenSigTimeoutTime" BU_SG_REL_ DACU SG_ 786 FLCObject02_CoastIndex 120;
BA_REL_ "GenSigFirstTimeoutTime" BU_SG_REL_ DACU SG_ 786 FLCObject02_Counter 3000;
BA_REL_ "GenSigTimeoutTime" BU_SG_REL_ DACU SG_ 786 FLCObject02_Counter 120;
BA_REL_ "GenSigFirstTimeoutTime" BU_SG_REL_ DACU SG_ 786 FLCObject02_TargetToLine 3000;
BA_REL_ "GenSigTimeoutTime" BU_SG_REL_ DACU SG_ 786 FLCObject02_TargetToLine 120;
BA_REL_ "GenSigFirstTimeoutTime" BU_SG_REL_ DACU SG_ 786 FLCObject02_AngFarVar 3000;
BA_REL_ "GenSigTimeoutTime" BU_SG_REL_ DACU SG_ 786 FLCObject02_AngFarVar 120;
BA_REL_ "GenSigFirstTimeoutTime" BU_SG_REL_ DACU SG_ 785 FLCObject01_TimeStamp 3000;
BA_REL_ "GenSigTimeoutTime" BU_SG_REL_ DACU SG_ 785 FLCObject01_TimeStamp 120;
BA_REL_ "GenSigFirstTimeoutTime" BU_SG_REL_ DACU SG_ 785 FLCObject01_CRC 3000;
BA_REL_ "GenSigTimeoutTime" BU_SG_REL_ DACU SG_ 785 FLCObject01_CRC 120;
BA_REL_ "GenSigFirstTimeoutTime" BU_SG_REL_ DACU SG_ 785 FLCObject01_LongVelVar 3000;
BA_REL_ "GenSigTimeoutTime" BU_SG_REL_ DACU SG_ 785 FLCObject01_LongVelVar 120;
BA_REL_ "GenSigFirstTimeoutTime" BU_SG_REL_ DACU SG_ 785 FLCObject01_ObjDynClass 3000;
BA_REL_ "GenSigTimeoutTime" BU_SG_REL_ DACU SG_ 785 FLCObject01_ObjDynClass 120;
BA_REL_ "GenSigFirstTimeoutTime" BU_SG_REL_ DACU SG_ 785 FLCObject01_ScaleChange 3000;
BA_REL_ "GenSigTimeoutTime" BU_SG_REL_ DACU SG_ 785 FLCObject01_ScaleChange 120;
BA_REL_ "GenSigFirstTimeoutTime" BU_SG_REL_ DACU SG_ 785 FLCObject01_AnglRightCorner 3000;
BA_REL_ "GenSigTimeoutTime" BU_SG_REL_ DACU SG_ 785 FLCObject01_AnglRightCorner 120;
BA_REL_ "GenSigFirstTimeoutTime" BU_SG_REL_ DACU SG_ 785 FLCObject01_ReliabilityConf 3000;
BA_REL_ "GenSigTimeoutTime" BU_SG_REL_ DACU SG_ 785 FLCObject01_ReliabilityConf 120;
BA_REL_ "GenSigFirstTimeoutTime" BU_SG_REL_ DACU SG_ 785 FLCObject01_LongAcc 3000;
BA_REL_ "GenSigTimeoutTime" BU_SG_REL_ DACU SG_ 785 FLCObject01_LongAcc 120;
BA_REL_ "GenSigFirstTimeoutTime" BU_SG_REL_ DACU SG_ 785 FLCObject01_DistLeftCorner 3000;
BA_REL_ "GenSigTimeoutTime" BU_SG_REL_ DACU SG_ 785 FLCObject01_DistLeftCorner 120;
BA_REL_ "GenSigFirstTimeoutTime" BU_SG_REL_ DACU SG_ 785 FLCObject01_BrakeLight 3000;
BA_REL_ "GenSigTimeoutTime" BU_SG_REL_ DACU SG_ 785 FLCObject01_BrakeLight 120;
BA_REL_ "GenSigFirstTimeoutTime" BU_SG_REL_ DACU SG_ 785 FLCObject01_DstFarVar 3000;
BA_REL_ "GenSigTimeoutTime" BU_SG_REL_ DACU SG_ 785 FLCObject01_DstFarVar 120;
BA_REL_ "GenSigFirstTimeoutTime" BU_SG_REL_ DACU SG_ 785 FLCObject01_LatVel 3000;
BA_REL_ "GenSigTimeoutTime" BU_SG_REL_ DACU SG_ 785 FLCObject01_LatVel 120;
BA_REL_ "GenSigFirstTimeoutTime" BU_SG_REL_ DACU SG_ 785 FLCObject01_LatPos 3000;
BA_REL_ "GenSigTimeoutTime" BU_SG_REL_ DACU SG_ 785 FLCObject01_LatPos 120;
BA_REL_ "GenSigFirstTimeoutTime" BU_SG_REL_ DACU SG_ 785 FLCObject01_LongPosVar 3000;
BA_REL_ "GenSigTimeoutTime" BU_SG_REL_ DACU SG_ 785 FLCObject01_LongPosVar 120;
BA_REL_ "GenSigFirstTimeoutTime" BU_SG_REL_ DACU SG_ 785 FLCObject01_DstLeftVar 3000;
BA_REL_ "GenSigTimeoutTime" BU_SG_REL_ DACU SG_ 785 FLCObject01_DstLeftVar 120;
BA_REL_ "GenSigFirstTimeoutTime" BU_SG_REL_ DACU SG_ 785 FLCObject01_LatPosVar 3000;
BA_REL_ "GenSigTimeoutTime" BU_SG_REL_ DACU SG_ 785 FLCObject01_LatPosVar 120;
BA_REL_ "GenSigFirstTimeoutTime" BU_SG_REL_ DACU SG_ 785 FLCObject01_ExistConf 3000;
BA_REL_ "GenSigTimeoutTime" BU_SG_REL_ DACU SG_ 785 FLCObject01_ExistConf 120;
BA_REL_ "GenSigFirstTimeoutTime" BU_SG_REL_ DACU SG_ 785 FLCObject01_Counter 3000;
BA_REL_ "GenSigTimeoutTime" BU_SG_REL_ DACU SG_ 785 FLCObject01_Counter 120;
BA_REL_ "GenSigFirstTimeoutTime" BU_SG_REL_ DACU SG_ 785 FLCObject01_ObjClass 3000;
BA_REL_ "GenSigTimeoutTime" BU_SG_REL_ DACU SG_ 785 FLCObject01_ObjClass 120;
BA_REL_ "GenSigFirstTimeoutTime" BU_SG_REL_ DACU SG_ 785 FLCObject01_LongVel 3000;
BA_REL_ "GenSigTimeoutTime" BU_SG_REL_ DACU SG_ 785 FLCObject01_LongVel 120;
BA_REL_ "GenSigFirstTimeoutTime" BU_SG_REL_ DACU SG_ 785 FLCObject01_Height 3000;
BA_REL_ "GenSigTimeoutTime" BU_SG_REL_ DACU SG_ 785 FLCObject01_Height 120;
BA_REL_ "GenSigFirstTimeoutTime" BU_SG_REL_ DACU SG_ 785 FLCObject01_LatVelVar 3000;
BA_REL_ "GenSigTimeoutTime" BU_SG_REL_ DACU SG_ 785 FLCObject01_LatVelVar 120;
BA_REL_ "GenSigFirstTimeoutTime" BU_SG_REL_ DACU SG_ 785 FLCObject01_AnglFarCorner 3000;
BA_REL_ "GenSigTimeoutTime" BU_SG_REL_ DACU SG_ 785 FLCObject01_AnglFarCorner 120;
BA_REL_ "GenSigFirstTimeoutTime" BU_SG_REL_ DACU SG_ 785 FLCObject01_Heading 3000;
BA_REL_ "GenSigTimeoutTime" BU_SG_REL_ DACU SG_ 785 FLCObject01_Heading 120;
BA_REL_ "GenSigFirstTimeoutTime" BU_SG_REL_ DACU SG_ 785 FLCObject01_LatAcc 3000;
BA_REL_ "GenSigTimeoutTime" BU_SG_REL_ DACU SG_ 785 FLCObject01_LatAcc 120;
BA_REL_ "GenSigFirstTimeoutTime" BU_SG_REL_ DACU SG_ 785 FLCObject01_LifeTime 3000;
BA_REL_ "GenSigTimeoutTime" BU_SG_REL_ DACU SG_ 785 FLCObject01_LifeTime 120;
BA_REL_ "GenSigFirstTimeoutTime" BU_SG_REL_ DACU SG_ 785 FLCObject01_HeadingVar 3000;
BA_REL_ "GenSigTimeoutTime" BU_SG_REL_ DACU SG_ 785 FLCObject01_HeadingVar 120;
BA_REL_ "GenSigFirstTimeoutTime" BU_SG_REL_ DACU SG_ 785 FLCObject01_AngLeftVar 3000;
BA_REL_ "GenSigTimeoutTime" BU_SG_REL_ DACU SG_ 785 FLCObject01_AngLeftVar 120;
BA_REL_ "GenSigFirstTimeoutTime" BU_SG_REL_ DACU SG_ 785 FLCObject01_AngFarVar 3000;
BA_REL_ "GenSigTimeoutTime" BU_SG_REL_ DACU SG_ 785 FLCObject01_AngFarVar 120;
BA_REL_ "GenSigFirstTimeoutTime" BU_SG_REL_ DACU SG_ 785 FLCObject01_CoastIndex 3000;
BA_REL_ "GenSigTimeoutTime" BU_SG_REL_ DACU SG_ 785 FLCObject01_CoastIndex 120;
BA_REL_ "GenSigFirstTimeoutTime" BU_SG_REL_ DACU SG_ 785 FLCObject01_DistRightCorner 3000;
BA_REL_ "GenSigTimeoutTime" BU_SG_REL_ DACU SG_ 785 FLCObject01_DistRightCorner 120;
BA_REL_ "GenSigFirstTimeoutTime" BU_SG_REL_ DACU SG_ 785 FLCObject01_TrackStatus 3000;
BA_REL_ "GenSigTimeoutTime" BU_SG_REL_ DACU SG_ 785 FLCObject01_TrackStatus 120;
BA_REL_ "GenSigFirstTimeoutTime" BU_SG_REL_ DACU SG_ 785 FLCObject01_LongPos 3000;
BA_REL_ "GenSigTimeoutTime" BU_SG_REL_ DACU SG_ 785 FLCObject01_LongPos 120;
BA_REL_ "GenSigFirstTimeoutTime" BU_SG_REL_ DACU SG_ 785 FLCObject01_ObjID 3000;
BA_REL_ "GenSigTimeoutTime" BU_SG_REL_ DACU SG_ 785 FLCObject01_ObjID 120;
BA_REL_ "GenSigFirstTimeoutTime" BU_SG_REL_ DACU SG_ 785 FLCObject01_DstRightVar 3000;
BA_REL_ "GenSigTimeoutTime" BU_SG_REL_ DACU SG_ 785 FLCObject01_DstRightVar 120;
BA_REL_ "GenSigFirstTimeoutTime" BU_SG_REL_ DACU SG_ 785 FLCObject01_DistFarCorner 3000;
BA_REL_ "GenSigTimeoutTime" BU_SG_REL_ DACU SG_ 785 FLCObject01_DistFarCorner 120;
BA_REL_ "GenSigFirstTimeoutTime" BU_SG_REL_ DACU SG_ 785 FLCObject01_TargetToLine 3000;
BA_REL_ "GenSigTimeoutTime" BU_SG_REL_ DACU SG_ 785 FLCObject01_TargetToLine 120;
BA_REL_ "GenSigFirstTimeoutTime" BU_SG_REL_ DACU SG_ 785 FLCObject01_TurnIndication 3000;
BA_REL_ "GenSigTimeoutTime" BU_SG_REL_ DACU SG_ 785 FLCObject01_TurnIndication 120;
BA_REL_ "GenSigFirstTimeoutTime" BU_SG_REL_ DACU SG_ 785 FLCObject01_AngRightVar 3000;
BA_REL_ "GenSigTimeoutTime" BU_SG_REL_ DACU SG_ 785 FLCObject01_AngRightVar 120;
BA_REL_ "GenSigFirstTimeoutTime" BU_SG_REL_ DACU SG_ 785 FLCObject01_AnglLeftCorner 3000;
BA_REL_ "GenSigTimeoutTime" BU_SG_REL_ DACU SG_ 785 FLCObject01_AnglLeftCorner 120;
BA_REL_ "GenSigFirstTimeoutTime" BU_SG_REL_ DACU SG_ 784 FLCObject00_LifeTime 3000;
BA_REL_ "GenSigTimeoutTime" BU_SG_REL_ DACU SG_ 784 FLCObject00_LifeTime 120;
BA_REL_ "GenSigFirstTimeoutTime" BU_SG_REL_ DACU SG_ 784 FLCObject00_BrakeLight 3000;
BA_REL_ "GenSigTimeoutTime" BU_SG_REL_ DACU SG_ 784 FLCObject00_BrakeLight 120;
BA_REL_ "GenSigFirstTimeoutTime" BU_SG_REL_ DACU SG_ 784 FLCObject00_AnglLeftCorner 3000;
BA_REL_ "GenSigTimeoutTime" BU_SG_REL_ DACU SG_ 784 FLCObject00_AnglLeftCorner 120;
BA_REL_ "GenSigFirstTimeoutTime" BU_SG_REL_ DACU SG_ 784 FLCObject00_DistRightCorner 3000;
BA_REL_ "GenSigTimeoutTime" BU_SG_REL_ DACU SG_ 784 FLCObject00_DistRightCorner 120;
BA_REL_ "GenSigFirstTimeoutTime" BU_SG_REL_ DACU SG_ 784 FLCObject00_LatPos 3000;
BA_REL_ "GenSigTimeoutTime" BU_SG_REL_ DACU SG_ 784 FLCObject00_LatPos 120;
BA_REL_ "GenSigFirstTimeoutTime" BU_SG_REL_ DACU SG_ 784 FLCObject00_TimeStamp 3000;
BA_REL_ "GenSigTimeoutTime" BU_SG_REL_ DACU SG_ 784 FLCObject00_TimeStamp 120;
BA_REL_ "GenSigFirstTimeoutTime" BU_SG_REL_ DACU SG_ 784 FLCObject00_LatAcc 3000;
BA_REL_ "GenSigTimeoutTime" BU_SG_REL_ DACU SG_ 784 FLCObject00_LatAcc 120;
BA_REL_ "GenSigFirstTimeoutTime" BU_SG_REL_ DACU SG_ 784 FLCObject00_LatVel 3000;
BA_REL_ "GenSigTimeoutTime" BU_SG_REL_ DACU SG_ 784 FLCObject00_LatVel 120;
BA_REL_ "GenSigFirstTimeoutTime" BU_SG_REL_ DACU SG_ 784 FLCObject00_ExistConf 3000;
BA_REL_ "GenSigTimeoutTime" BU_SG_REL_ DACU SG_ 784 FLCObject00_ExistConf 120;
BA_REL_ "GenSigFirstTimeoutTime" BU_SG_REL_ DACU SG_ 784 FLCObject00_AngRightVar 3000;
BA_REL_ "GenSigTimeoutTime" BU_SG_REL_ DACU SG_ 784 FLCObject00_AngRightVar 120;
BA_REL_ "GenSigFirstTimeoutTime" BU_SG_REL_ DACU SG_ 784 FLCObject00_AnglRightCorner 3000;
BA_REL_ "GenSigTimeoutTime" BU_SG_REL_ DACU SG_ 784 FLCObject00_AnglRightCorner 120;
BA_REL_ "GenSigFirstTimeoutTime" BU_SG_REL_ DACU SG_ 784 FLCObject00_LatPosVar 3000;
BA_REL_ "GenSigTimeoutTime" BU_SG_REL_ DACU SG_ 784 FLCObject00_LatPosVar 120;
BA_REL_ "GenSigFirstTimeoutTime" BU_SG_REL_ DACU SG_ 784 FLCObject00_DistLeftCorner 3000;
BA_REL_ "GenSigTimeoutTime" BU_SG_REL_ DACU SG_ 784 FLCObject00_DistLeftCorner 120;
BA_REL_ "GenSigFirstTimeoutTime" BU_SG_REL_ DACU SG_ 784 FLCObject00_CoastIndex 3000;
BA_REL_ "GenSigTimeoutTime" BU_SG_REL_ DACU SG_ 784 FLCObject00_CoastIndex 120;
BA_REL_ "GenSigFirstTimeoutTime" BU_SG_REL_ DACU SG_ 784 FLCObject00_TrackStatus 3000;
BA_REL_ "GenSigTimeoutTime" BU_SG_REL_ DACU SG_ 784 FLCObject00_TrackStatus 120;
BA_REL_ "GenSigFirstTimeoutTime" BU_SG_REL_ DACU SG_ 784 FLCObject00_ScaleChange 3000;
BA_REL_ "GenSigTimeoutTime" BU_SG_REL_ DACU SG_ 784 FLCObject00_ScaleChange 120;
BA_REL_ "GenSigFirstTimeoutTime" BU_SG_REL_ DACU SG_ 784 FLCObject00_LatVelVar 3000;
BA_REL_ "GenSigTimeoutTime" BU_SG_REL_ DACU SG_ 784 FLCObject00_LatVelVar 120;
BA_REL_ "GenSigFirstTimeoutTime" BU_SG_REL_ DACU SG_ 784 FLCObject00_HeadingVar 3000;
BA_REL_ "GenSigTimeoutTime" BU_SG_REL_ DACU SG_ 784 FLCObject00_HeadingVar 120;
BA_REL_ "GenSigFirstTimeoutTime" BU_SG_REL_ DACU SG_ 784 FLCObject00_LongPosVar 3000;
BA_REL_ "GenSigTimeoutTime" BU_SG_REL_ DACU SG_ 784 FLCObject00_LongPosVar 120;
BA_REL_ "GenSigFirstTimeoutTime" BU_SG_REL_ DACU SG_ 784 FLCObject00_DstLeftVar 3000;
BA_REL_ "GenSigTimeoutTime" BU_SG_REL_ DACU SG_ 784 FLCObject00_DstLeftVar 120;
BA_REL_ "GenSigFirstTimeoutTime" BU_SG_REL_ DACU SG_ 784 FLCObject00_ObjID 3000;
BA_REL_ "GenSigTimeoutTime" BU_SG_REL_ DACU SG_ 784 FLCObject00_ObjID 120;
BA_REL_ "GenSigFirstTimeoutTime" BU_SG_REL_ DACU SG_ 784 FLCObject00_ObjClass 3000;
BA_REL_ "GenSigTimeoutTime" BU_SG_REL_ DACU SG_ 784 FLCObject00_ObjClass 120;
BA_REL_ "GenSigFirstTimeoutTime" BU_SG_REL_ DACU SG_ 784 FLCObject00_AnglFarCorner 3000;
BA_REL_ "GenSigTimeoutTime" BU_SG_REL_ DACU SG_ 784 FLCObject00_AnglFarCorner 120;
BA_REL_ "GenSigFirstTimeoutTime" BU_SG_REL_ DACU SG_ 784 FLCObject00_DstFarVar 3000;
BA_REL_ "GenSigTimeoutTime" BU_SG_REL_ DACU SG_ 784 FLCObject00_DstFarVar 120;
BA_REL_ "GenSigFirstTimeoutTime" BU_SG_REL_ DACU SG_ 784 FLCObject00_LongVel 3000;
BA_REL_ "GenSigTimeoutTime" BU_SG_REL_ DACU SG_ 784 FLCObject00_LongVel 120;
BA_REL_ "GenSigFirstTimeoutTime" BU_SG_REL_ DACU SG_ 784 FLCObject00_LongPos 3000;
BA_REL_ "GenSigTimeoutTime" BU_SG_REL_ DACU SG_ 784 FLCObject00_LongPos 120;
BA_REL_ "GenSigFirstTimeoutTime" BU_SG_REL_ DACU SG_ 784 FLCObject00_AngLeftVar 3000;
BA_REL_ "GenSigTimeoutTime" BU_SG_REL_ DACU SG_ 784 FLCObject00_AngLeftVar 120;
BA_REL_ "GenSigFirstTimeoutTime" BU_SG_REL_ DACU SG_ 784 FLCObject00_ReliabilityConf 3000;
BA_REL_ "GenSigTimeoutTime" BU_SG_REL_ DACU SG_ 784 FLCObject00_ReliabilityConf 120;
BA_REL_ "GenSigFirstTimeoutTime" BU_SG_REL_ DACU SG_ 784 FLCObject00_Counter 3000;
BA_REL_ "GenSigTimeoutTime" BU_SG_REL_ DACU SG_ 784 FLCObject00_Counter 120;
BA_REL_ "GenSigFirstTimeoutTime" BU_SG_REL_ DACU SG_ 784 FLCObject00_ObjDynClass 3000;
BA_REL_ "GenSigTimeoutTime" BU_SG_REL_ DACU SG_ 784 FLCObject00_ObjDynClass 120;
BA_REL_ "GenSigFirstTimeoutTime" BU_SG_REL_ DACU SG_ 784 FLCObject00_TargetToLine 3000;
BA_REL_ "GenSigTimeoutTime" BU_SG_REL_ DACU SG_ 784 FLCObject00_TargetToLine 120;
BA_REL_ "GenSigFirstTimeoutTime" BU_SG_REL_ DACU SG_ 784 FLCObject00_DstRightVar 3000;
BA_REL_ "GenSigTimeoutTime" BU_SG_REL_ DACU SG_ 784 FLCObject00_DstRightVar 120;
BA_REL_ "GenSigFirstTimeoutTime" BU_SG_REL_ DACU SG_ 784 FLCObject00_TurnIndication 3000;
BA_REL_ "GenSigTimeoutTime" BU_SG_REL_ DACU SG_ 784 FLCObject00_TurnIndication 120;
BA_REL_ "GenSigFirstTimeoutTime" BU_SG_REL_ DACU SG_ 784 FLCObject00_AngFarVar 3000;
BA_REL_ "GenSigTimeoutTime" BU_SG_REL_ DACU SG_ 784 FLCObject00_AngFarVar 120;
BA_REL_ "GenSigFirstTimeoutTime" BU_SG_REL_ DACU SG_ 784 FLCObject00_Heading 3000;
BA_REL_ "GenSigTimeoutTime" BU_SG_REL_ DACU SG_ 784 FLCObject00_Heading 120;
BA_REL_ "GenSigFirstTimeoutTime" BU_SG_REL_ DACU SG_ 784 FLCObject00_DistFarCorner 3000;
BA_REL_ "GenSigTimeoutTime" BU_SG_REL_ DACU SG_ 784 FLCObject00_DistFarCorner 120;
BA_REL_ "GenSigFirstTimeoutTime" BU_SG_REL_ DACU SG_ 784 FLCObject00_LongAcc 3000;
BA_REL_ "GenSigTimeoutTime" BU_SG_REL_ DACU SG_ 784 FLCObject00_LongAcc 120;
BA_REL_ "GenSigFirstTimeoutTime" BU_SG_REL_ DACU SG_ 784 FLCObject00_Height 3000;
BA_REL_ "GenSigTimeoutTime" BU_SG_REL_ DACU SG_ 784 FLCObject00_Height 120;
BA_REL_ "GenSigFirstTimeoutTime" BU_SG_REL_ DACU SG_ 784 FLCObject00_LongVelVar 3000;
BA_REL_ "GenSigTimeoutTime" BU_SG_REL_ DACU SG_ 784 FLCObject00_LongVelVar 120;
BA_REL_ "GenSigFirstTimeoutTime" BU_SG_REL_ DACU SG_ 784 FLCObject00_CRC 3000;
BA_REL_ "GenSigTimeoutTime" BU_SG_REL_ DACU SG_ 784 FLCObject00_CRC 120;
BA_REL_ "GenSigFirstTimeoutTime" BU_SG_REL_ DACU SG_ 1527 DiagFaultStat_FLC_EcuAdr 24000;
BA_REL_ "GenSigTimeoutTime" BU_SG_REL_ DACU SG_ 1527 DiagFaultStat_FLC_EcuAdr 6000;
BA_REL_ "GenSigFirstTimeoutTime" BU_SG_REL_ DACU SG_ 1527 DiagFaultStat_FLC_FailTA 24000;
BA_REL_ "GenSigTimeoutTime" BU_SG_REL_ DACU SG_ 1527 DiagFaultStat_FLC_FailTA 6000;
BA_REL_ "GenSigFirstTimeoutTime" BU_SG_REL_ DACU SG_ 1527 DiagFaultStat_FLC_DtcIdA 24000;
BA_REL_ "GenSigTimeoutTime" BU_SG_REL_ DACU SG_ 1527 DiagFaultStat_FLC_DtcIdA 6000;
BA_REL_ "GenSigFirstTimeoutTime" BU_SG_REL_ DACU SG_ 1527 DiagFaultStat_FLC_FailTB 24000;
BA_REL_ "GenSigTimeoutTime" BU_SG_REL_ DACU SG_ 1527 DiagFaultStat_FLC_FailTB 6000;
BA_REL_ "GenSigFirstTimeoutTime" BU_SG_REL_ DACU SG_ 1527 DiagFaultStat_FLC_DtcIdB 24000;
BA_REL_ "GenSigTimeoutTime" BU_SG_REL_ DACU SG_ 1527 DiagFaultStat_FLC_DtcIdB 6000;
BA_REL_ "GenSigFirstTimeoutTime" BU_SG_REL_ FLC2 SG_ 281 ShadowArea_LeftAgl03 3000;
BA_REL_ "GenSigTimeoutTime" BU_SG_REL_ FLC2 SG_ 281 ShadowArea_LeftAgl03 120;
BA_REL_ "GenSigFirstTimeoutTime" BU_SG_REL_ FLC2 SG_ 281 ShadowArea_RightAgl02 3000;
BA_REL_ "GenSigTimeoutTime" BU_SG_REL_ FLC2 SG_ 281 ShadowArea_RightAgl02 120;
BA_REL_ "GenSigFirstTimeoutTime" BU_SG_REL_ FLC2 SG_ 281 ShadowArea_RightAgl01 3000;
BA_REL_ "GenSigTimeoutTime" BU_SG_REL_ FLC2 SG_ 281 ShadowArea_RightAgl01 120;
BA_REL_ "GenSigFirstTimeoutTime" BU_SG_REL_ FLC2 SG_ 281 ShadowArea_LeftAgl02 3000;
BA_REL_ "GenSigTimeoutTime" BU_SG_REL_ FLC2 SG_ 281 ShadowArea_LeftAgl02 120;
BA_REL_ "GenSigFirstTimeoutTime" BU_SG_REL_ FLC2 SG_ 281 ShadowArea_Dist03 3000;
BA_REL_ "GenSigTimeoutTime" BU_SG_REL_ FLC2 SG_ 281 ShadowArea_Dist03 120;
BA_REL_ "GenSigFirstTimeoutTime" BU_SG_REL_ FLC2 SG_ 281 ShadowArea_Dist01 3000;
BA_REL_ "GenSigTimeoutTime" BU_SG_REL_ FLC2 SG_ 281 ShadowArea_Dist01 120;
BA_REL_ "GenSigFirstTimeoutTime" BU_SG_REL_ FLC2 SG_ 281 ShadowArea_LeftAgl01 3000;
BA_REL_ "GenSigTimeoutTime" BU_SG_REL_ FLC2 SG_ 281 ShadowArea_LeftAgl01 120;
BA_REL_ "GenSigFirstTimeoutTime" BU_SG_REL_ FLC2 SG_ 281 ShadowArea_Dist02 3000;
BA_REL_ "GenSigTimeoutTime" BU_SG_REL_ FLC2 SG_ 281 ShadowArea_Dist02 120;
BA_REL_ "GenSigFirstTimeoutTime" BU_SG_REL_ FLC2 SG_ 281 ShadowArea_RightAgl03 3000;
BA_REL_ "GenSigTimeoutTime" BU_SG_REL_ FLC2 SG_ 281 ShadowArea_RightAgl03 120;
BA_REL_ "GenSigFirstTimeoutTime" BU_SG_REL_ FLC2 SG_ 279 EgoPathPrediction_ConfCoeffA3 3000;
BA_REL_ "GenSigTimeoutTime" BU_SG_REL_ FLC2 SG_ 279 EgoPathPrediction_ConfCoeffA3 120;
BA_REL_ "GenSigFirstTimeoutTime" BU_SG_REL_ FLC2 SG_ 279 EgoPathPrediction_CurvatureRate 3000;
BA_REL_ "GenSigTimeoutTime" BU_SG_REL_ FLC2 SG_ 279 EgoPathPrediction_CurvatureRate 120;
BA_REL_ "GenSigFirstTimeoutTime" BU_SG_REL_ FLC2 SG_ 279 EgoPathPrediction_DxEnd 3000;
BA_REL_ "GenSigTimeoutTime" BU_SG_REL_ FLC2 SG_ 279 EgoPathPrediction_DxEnd 120;
BA_REL_ "GenSigFirstTimeoutTime" BU_SG_REL_ FLC2 SG_ 279 EgoPathPrediction_HeadingAngle 3000;
BA_REL_ "GenSigTimeoutTime" BU_SG_REL_ FLC2 SG_ 279 EgoPathPrediction_HeadingAngle 120;
BA_REL_ "GenSigFirstTimeoutTime" BU_SG_REL_ FLC2 SG_ 279 EgoPathPrediction_ConfCoeffA1 3000;
BA_REL_ "GenSigTimeoutTime" BU_SG_REL_ FLC2 SG_ 279 EgoPathPrediction_ConfCoeffA1 120;
BA_REL_ "GenSigFirstTimeoutTime" BU_SG_REL_ FLC2 SG_ 279 EgoPathPrediction_ConfCoeffA0 3000;
BA_REL_ "GenSigTimeoutTime" BU_SG_REL_ FLC2 SG_ 279 EgoPathPrediction_ConfCoeffA0 120;
BA_REL_ "GenSigFirstTimeoutTime" BU_SG_REL_ FLC2 SG_ 279 EgoPathPrediction_ConfCoeffA2 3000;
BA_REL_ "GenSigTimeoutTime" BU_SG_REL_ FLC2 SG_ 279 EgoPathPrediction_ConfCoeffA2 120;
BA_REL_ "GenSigFirstTimeoutTime" BU_SG_REL_ FLC2 SG_ 279 EgoPathPrediction_Curvature 3000;
BA_REL_ "GenSigTimeoutTime" BU_SG_REL_ FLC2 SG_ 279 EgoPathPrediction_Curvature 120;
BA_REL_ "GenSigFirstTimeoutTime" BU_SG_REL_ FLC2 SG_ 275 EgoMotionXYplane_LongSpeedVar 3000;
BA_REL_ "GenSigTimeoutTime" BU_SG_REL_ FLC2 SG_ 275 EgoMotionXYplane_LongSpeedVar 100;
BA_REL_ "GenSigFirstTimeoutTime" BU_SG_REL_ FLC2 SG_ 275 EgoMotionXYplane_LongAccVariance 3000;
BA_REL_ "GenSigTimeoutTime" BU_SG_REL_ FLC2 SG_ 275 EgoMotionXYplane_LongAccVariance 100;
BA_REL_ "GenSigFirstTimeoutTime" BU_SG_REL_ FLC2 SG_ 275 EgoMotionXYplane_LongMotionDir 3000;
BA_REL_ "GenSigTimeoutTime" BU_SG_REL_ FLC2 SG_ 275 EgoMotionXYplane_LongMotionDir 100;
BA_REL_ "GenSigFirstTimeoutTime" BU_SG_REL_ FLC2 SG_ 275 EgoMotionXYplane_Curvature 3000;
BA_REL_ "GenSigTimeoutTime" BU_SG_REL_ FLC2 SG_ 275 EgoMotionXYplane_Curvature 100;
BA_REL_ "GenSigFirstTimeoutTime" BU_SG_REL_ FLC2 SG_ 275 EgoMotionXYplane_LongAcc 3000;
BA_REL_ "GenSigTimeoutTime" BU_SG_REL_ FLC2 SG_ 275 EgoMotionXYplane_LongAcc 100;
BA_REL_ "GenSigFirstTimeoutTime" BU_SG_REL_ FLC2 SG_ 275 EgoMotionXYplane_LatAccVariance 3000;
BA_REL_ "GenSigTimeoutTime" BU_SG_REL_ FLC2 SG_ 275 EgoMotionXYplane_LatAccVariance 100;
BA_REL_ "GenSigFirstTimeoutTime" BU_SG_REL_ FLC2 SG_ 275 EgoMotionXYplane_YawRateVariance 3000;
BA_REL_ "GenSigTimeoutTime" BU_SG_REL_ FLC2 SG_ 275 EgoMotionXYplane_YawRateVariance 100;
BA_REL_ "GenSigFirstTimeoutTime" BU_SG_REL_ FLC2 SG_ 275 EgoMotionXYplane_LongMotDirConf 3000;
BA_REL_ "GenSigTimeoutTime" BU_SG_REL_ FLC2 SG_ 275 EgoMotionXYplane_LongMotDirConf 100;
BA_REL_ "GenSigFirstTimeoutTime" BU_SG_REL_ FLC2 SG_ 275 EgoMotionXYplane_YawRateComp 3000;
BA_REL_ "GenSigTimeoutTime" BU_SG_REL_ FLC2 SG_ 275 EgoMotionXYplane_YawRateComp 100;
BA_REL_ "GenSigFirstTimeoutTime" BU_SG_REL_ FLC2 SG_ 275 EgoMotionXYplane_ReferencePointX 3000;
BA_REL_ "GenSigTimeoutTime" BU_SG_REL_ FLC2 SG_ 275 EgoMotionXYplane_ReferencePointX 100;
BA_REL_ "GenSigFirstTimeoutTime" BU_SG_REL_ FLC2 SG_ 275 EgoMotionXYplane_LateralSpeed 3000;
BA_REL_ "GenSigTimeoutTime" BU_SG_REL_ FLC2 SG_ 275 EgoMotionXYplane_LateralSpeed 100;
BA_REL_ "GenSigFirstTimeoutTime" BU_SG_REL_ FLC2 SG_ 275 EgoMotionXYplane_LateralAcc 3000;
BA_REL_ "GenSigTimeoutTime" BU_SG_REL_ FLC2 SG_ 275 EgoMotionXYplane_LateralAcc 100;
BA_REL_ "GenSigFirstTimeoutTime" BU_SG_REL_ FLC2 SG_ 275 EgoMotionXYplane_CRC 3000;
BA_REL_ "GenSigTimeoutTime" BU_SG_REL_ FLC2 SG_ 275 EgoMotionXYplane_CRC 100;
BA_REL_ "GenSigFirstTimeoutTime" BU_SG_REL_ FLC2 SG_ 275 EgoMotionXYplane_LongSpeed 3000;
BA_REL_ "GenSigTimeoutTime" BU_SG_REL_ FLC2 SG_ 275 EgoMotionXYplane_LongSpeed 100;
BA_REL_ "GenSigFirstTimeoutTime" BU_SG_REL_ FLC2 SG_ 275 EgoMotionXYplane_LatSpeedVar 3000;
BA_REL_ "GenSigTimeoutTime" BU_SG_REL_ FLC2 SG_ 275 EgoMotionXYplane_LatSpeedVar 100;
BA_REL_ "GenSigFirstTimeoutTime" BU_SG_REL_ FLC2 SG_ 275 EgoMotionXYplane_LatencyEst 3000;
BA_REL_ "GenSigTimeoutTime" BU_SG_REL_ FLC2 SG_ 275 EgoMotionXYplane_LatencyEst 100;
BA_REL_ "GenSigFirstTimeoutTime" BU_SG_REL_ FLC2 SG_ 275 EgoMotionXYplane_ChassisDynPitch 3000;
BA_REL_ "GenSigTimeoutTime" BU_SG_REL_ FLC2 SG_ 275 EgoMotionXYplane_ChassisDynPitch 100;
BA_REL_ "GenSigFirstTimeoutTime" BU_SG_REL_ FLC2 SG_ 275 VehicleMode 3000;
BA_REL_ "GenSigTimeoutTime" BU_SG_REL_ FLC2 SG_ 275 VehicleMode 100;
BA_REL_ "GenSigFirstTimeoutTime" BU_SG_REL_ FLC2 SG_ 275 EgoMotionXYplane_Counter 3000;
BA_REL_ "GenSigTimeoutTime" BU_SG_REL_ FLC2 SG_ 275 EgoMotionXYplane_Counter 100;
BA_REL_ "GenSigFirstTimeoutTime" BU_SG_REL_ FLC2 SG_ 275 EgoMotionXYplane_EffectiveWheelB 3000;
BA_REL_ "GenSigTimeoutTime" BU_SG_REL_ FLC2 SG_ 275 EgoMotionXYplane_EffectiveWheelB 100;
BA_REL_ "GenSigFirstTimeoutTime" BU_SG_REL_ FLC2 SG_ 277 EgoMotionRaw_RelLvlRrAxleRight 3000;
BA_REL_ "GenSigTimeoutTime" BU_SG_REL_ FLC2 SG_ 277 EgoMotionRaw_RelLvlRrAxleRight 120;
BA_REL_ "GenSigFirstTimeoutTime" BU_SG_REL_ FLC2 SG_ 277 EgoMotionRaw_FrAxleLeftWSpeed 3000;
BA_REL_ "GenSigTimeoutTime" BU_SG_REL_ FLC2 SG_ 277 EgoMotionRaw_FrAxleLeftWSpeed 120;
BA_REL_ "GenSigFirstTimeoutTime" BU_SG_REL_ FLC2 SG_ 277 EgoMotionRaw_GrossCombVehWeight 3000;
BA_REL_ "GenSigTimeoutTime" BU_SG_REL_ FLC2 SG_ 277 EgoMotionRaw_GrossCombVehWeight 120;
BA_REL_ "GenSigFirstTimeoutTime" BU_SG_REL_ FLC2 SG_ 277 EgoMotionRaw_FrontWheelAngle 3000;
BA_REL_ "GenSigTimeoutTime" BU_SG_REL_ FLC2 SG_ 277 EgoMotionRaw_FrontWheelAngle 120;
BA_REL_ "GenSigFirstTimeoutTime" BU_SG_REL_ FLC2 SG_ 277 EgoMotionRaw_BrakePedalPosition 3000;
BA_REL_ "GenSigTimeoutTime" BU_SG_REL_ FLC2 SG_ 277 EgoMotionRaw_BrakePedalPosition 120;
BA_REL_ "GenSigFirstTimeoutTime" BU_SG_REL_ FLC2 SG_ 277 EgoMotionRaw_SteeringWheelAngle 3000;
BA_REL_ "GenSigTimeoutTime" BU_SG_REL_ FLC2 SG_ 277 EgoMotionRaw_SteeringWheelAngle 120;
BA_REL_ "GenSigFirstTimeoutTime" BU_SG_REL_ FLC2 SG_ 277 EgoMotionRaw_SteeringWheelRatio 3000;
BA_REL_ "GenSigTimeoutTime" BU_SG_REL_ FLC2 SG_ 277 EgoMotionRaw_SteeringWheelRatio 120;
BA_REL_ "GenSigFirstTimeoutTime" BU_SG_REL_ FLC2 SG_ 277 EgoMotionRaw_FrAxleRightWSpeed 3000;
BA_REL_ "GenSigTimeoutTime" BU_SG_REL_ FLC2 SG_ 277 EgoMotionRaw_FrAxleRightWSpeed 120;
BA_REL_ "GenSigFirstTimeoutTime" BU_SG_REL_ FLC2 SG_ 277 EgoMotionRaw_ROPEngineActive 3000;
BA_REL_ "GenSigTimeoutTime" BU_SG_REL_ FLC2 SG_ 277 EgoMotionRaw_ROPEngineActive 120;
BA_REL_ "GenSigFirstTimeoutTime" BU_SG_REL_ FLC2 SG_ 277 EgoMotionRaw_AccKckDwn 3000;
BA_REL_ "GenSigTimeoutTime" BU_SG_REL_ FLC2 SG_ 277 EgoMotionRaw_AccKckDwn 120;
BA_REL_ "GenSigFirstTimeoutTime" BU_SG_REL_ FLC2 SG_ 277 EgoMotionRaw_RelLvlFrAxleLeft 3000;
BA_REL_ "GenSigTimeoutTime" BU_SG_REL_ FLC2 SG_ 277 EgoMotionRaw_RelLvlFrAxleLeft 120;
BA_REL_ "GenSigFirstTimeoutTime" BU_SG_REL_ FLC2 SG_ 277 EgoMotionRaw_ABSActive 3000;
BA_REL_ "GenSigTimeoutTime" BU_SG_REL_ FLC2 SG_ 277 EgoMotionRaw_ABSActive 120;
BA_REL_ "GenSigFirstTimeoutTime" BU_SG_REL_ FLC2 SG_ 277 EgoMotionRaw_AccPedalPos 3000;
BA_REL_ "GenSigTimeoutTime" BU_SG_REL_ FLC2 SG_ 277 EgoMotionRaw_AccPedalPos 120;
BA_REL_ "GenSigFirstTimeoutTime" BU_SG_REL_ FLC2 SG_ 277 EgoMotionRaw_YCEngineActive 3000;
BA_REL_ "GenSigTimeoutTime" BU_SG_REL_ FLC2 SG_ 277 EgoMotionRaw_YCEngineActive 100;
BA_REL_ "GenSigFirstTimeoutTime" BU_SG_REL_ FLC2 SG_ 277 EgoMotionRaw_RAxleRightWSpeed 3000;
BA_REL_ "GenSigTimeoutTime" BU_SG_REL_ FLC2 SG_ 277 EgoMotionRaw_RAxleRightWSpeed 120;
BA_REL_ "GenSigFirstTimeoutTime" BU_SG_REL_ FLC2 SG_ 277 EgoMotionRaw_ASRBrakeA 3000;
BA_REL_ "GenSigTimeoutTime" BU_SG_REL_ FLC2 SG_ 277 EgoMotionRaw_ASRBrakeA 120;
BA_REL_ "GenSigFirstTimeoutTime" BU_SG_REL_ FLC2 SG_ 277 EgoMotionRaw_RelLvlFrAxleRight 3000;
BA_REL_ "GenSigTimeoutTime" BU_SG_REL_ FLC2 SG_ 277 EgoMotionRaw_RelLvlFrAxleRight 120;
BA_REL_ "GenSigFirstTimeoutTime" BU_SG_REL_ FLC2 SG_ 277 EgoMotionRaw_VDCFullyOperational 3000;
BA_REL_ "GenSigTimeoutTime" BU_SG_REL_ FLC2 SG_ 277 EgoMotionRaw_VDCFullyOperational 100;
BA_REL_ "GenSigFirstTimeoutTime" BU_SG_REL_ FLC2 SG_ 277 EgoMotionRaw_TrailerConStatus 3000;
BA_REL_ "GenSigTimeoutTime" BU_SG_REL_ FLC2 SG_ 277 EgoMotionRaw_TrailerConStatus 120;
BA_REL_ "GenSigFirstTimeoutTime" BU_SG_REL_ FLC2 SG_ 277 EgoMotionRaw_YCBrakeActive 3000;
BA_REL_ "GenSigTimeoutTime" BU_SG_REL_ FLC2 SG_ 277 EgoMotionRaw_YCBrakeActive 100;
BA_REL_ "GenSigFirstTimeoutTime" BU_SG_REL_ FLC2 SG_ 277 EgoMotionRaw_ASREngineA 3000;
BA_REL_ "GenSigTimeoutTime" BU_SG_REL_ FLC2 SG_ 277 EgoMotionRaw_ASREngineA 120;
BA_REL_ "GenSigFirstTimeoutTime" BU_SG_REL_ FLC2 SG_ 277 EgoMotionRaw_RelLvlRrAxleLeft 3000;
BA_REL_ "GenSigTimeoutTime" BU_SG_REL_ FLC2 SG_ 277 EgoMotionRaw_RelLvlRrAxleLeft 120;
BA_REL_ "GenSigFirstTimeoutTime" BU_SG_REL_ FLC2 SG_ 277 EgoMotionRaw_Counter 3000;
BA_REL_ "GenSigTimeoutTime" BU_SG_REL_ FLC2 SG_ 277 EgoMotionRaw_Counter 120;
BA_REL_ "GenSigFirstTimeoutTime" BU_SG_REL_ FLC2 SG_ 277 EgoMotionRaw_ROPBrakeActive 3000;
BA_REL_ "GenSigTimeoutTime" BU_SG_REL_ FLC2 SG_ 277 EgoMotionRaw_ROPBrakeActive 120;
BA_REL_ "GenSigFirstTimeoutTime" BU_SG_REL_ FLC2 SG_ 277 EgoMotionRaw_CRC 3000;
BA_REL_ "GenSigTimeoutTime" BU_SG_REL_ FLC2 SG_ 277 EgoMotionRaw_CRC 120;
BA_REL_ "GenSigFirstTimeoutTime" BU_SG_REL_ FLC2 SG_ 277 EgoMotionRaw_RAxleLeftWSpeed 3000;
BA_REL_ "GenSigTimeoutTime" BU_SG_REL_ FLC2 SG_ 277 EgoMotionRaw_RAxleLeftWSpeed 120;
BA_REL_ "GenSigFirstTimeoutTime" BU_SG_REL_ FLC2 SG_ 277 EgoMotionRaw_ABSOp 3000;
BA_REL_ "GenSigTimeoutTime" BU_SG_REL_ FLC2 SG_ 277 EgoMotionRaw_ABSOp 120;
BA_REL_ "GenSigFirstTimeoutTime" BU_SG_REL_ FLC2 SG_ 1543 VIN_DACU_Byte08 65000;
BA_REL_ "GenSigTimeoutTime" BU_SG_REL_ FLC2 SG_ 1543 VIN_DACU_Byte08 30000;
BA_REL_ "GenSigFirstTimeoutTime" BU_SG_REL_ FLC2 SG_ 1543 VIN_DACU_Byte01 65000;
BA_REL_ "GenSigTimeoutTime" BU_SG_REL_ FLC2 SG_ 1543 VIN_DACU_Byte01 30000;
BA_REL_ "GenSigFirstTimeoutTime" BU_SG_REL_ FLC2 SG_ 1543 VIN_DACU_Byte13 65000;
BA_REL_ "GenSigTimeoutTime" BU_SG_REL_ FLC2 SG_ 1543 VIN_DACU_Byte13 30000;
BA_REL_ "GenSigFirstTimeoutTime" BU_SG_REL_ FLC2 SG_ 1543 CountryCodeLocal_Code 65000;
BA_REL_ "GenSigTimeoutTime" BU_SG_REL_ FLC2 SG_ 1543 CountryCodeLocal_Code 30000;
BA_REL_ "GenSigFirstTimeoutTime" BU_SG_REL_ FLC2 SG_ 1543 VIN_DACU_Byte06 65000;
BA_REL_ "GenSigTimeoutTime" BU_SG_REL_ FLC2 SG_ 1543 VIN_DACU_Byte06 30000;
BA_REL_ "GenSigFirstTimeoutTime" BU_SG_REL_ FLC2 SG_ 1543 VIN_DACU_Byte03 65000;
BA_REL_ "GenSigTimeoutTime" BU_SG_REL_ FLC2 SG_ 1543 VIN_DACU_Byte03 30000;
BA_REL_ "GenSigFirstTimeoutTime" BU_SG_REL_ FLC2 SG_ 1543 VIN_DACU_Byte15 65000;
BA_REL_ "GenSigTimeoutTime" BU_SG_REL_ FLC2 SG_ 1543 VIN_DACU_Byte15 30000;
BA_REL_ "GenSigFirstTimeoutTime" BU_SG_REL_ FLC2 SG_ 1543 VIN_DACU_Byte16 65000;
BA_REL_ "GenSigTimeoutTime" BU_SG_REL_ FLC2 SG_ 1543 VIN_DACU_Byte16 30000;
BA_REL_ "GenSigFirstTimeoutTime" BU_SG_REL_ FLC2 SG_ 1543 CountryCodeLocal_Counter 65000;
BA_REL_ "GenSigTimeoutTime" BU_SG_REL_ FLC2 SG_ 1543 CountryCodeLocal_Counter 30000;
BA_REL_ "GenSigFirstTimeoutTime" BU_SG_REL_ FLC2 SG_ 1543 VIN_DACU_Byte09 65000;
BA_REL_ "GenSigTimeoutTime" BU_SG_REL_ FLC2 SG_ 1543 VIN_DACU_Byte09 30000;
BA_REL_ "GenSigFirstTimeoutTime" BU_SG_REL_ FLC2 SG_ 1543 VIN_DACU_Byte04 65000;
BA_REL_ "GenSigTimeoutTime" BU_SG_REL_ FLC2 SG_ 1543 VIN_DACU_Byte04 30000;
BA_REL_ "GenSigFirstTimeoutTime" BU_SG_REL_ FLC2 SG_ 1543 CountryCodeLocal_CRC 65000;
BA_REL_ "GenSigTimeoutTime" BU_SG_REL_ FLC2 SG_ 1543 CountryCodeLocal_CRC 30000;
BA_REL_ "GenSigFirstTimeoutTime" BU_SG_REL_ FLC2 SG_ 1543 VIN_DACU_Byte02 65000;
BA_REL_ "GenSigTimeoutTime" BU_SG_REL_ FLC2 SG_ 1543 VIN_DACU_Byte02 30000;
BA_REL_ "GenSigFirstTimeoutTime" BU_SG_REL_ FLC2 SG_ 1543 VIN_DACU_Byte14 65000;
BA_REL_ "GenSigTimeoutTime" BU_SG_REL_ FLC2 SG_ 1543 VIN_DACU_Byte14 30000;
BA_REL_ "GenSigFirstTimeoutTime" BU_SG_REL_ FLC2 SG_ 1543 VIN_DACU_Byte12 65000;
BA_REL_ "GenSigTimeoutTime" BU_SG_REL_ FLC2 SG_ 1543 VIN_DACU_Byte12 30000;
BA_REL_ "GenSigFirstTimeoutTime" BU_SG_REL_ FLC2 SG_ 1543 VIN_DACU_Byte10 65000;
BA_REL_ "GenSigTimeoutTime" BU_SG_REL_ FLC2 SG_ 1543 VIN_DACU_Byte10 30000;
BA_REL_ "GenSigFirstTimeoutTime" BU_SG_REL_ FLC2 SG_ 1543 VIN_DACU_Byte11 65000;
BA_REL_ "GenSigTimeoutTime" BU_SG_REL_ FLC2 SG_ 1543 VIN_DACU_Byte11 30000;
BA_REL_ "GenSigFirstTimeoutTime" BU_SG_REL_ FLC2 SG_ 1543 RegionCode 65000;
BA_REL_ "GenSigTimeoutTime" BU_SG_REL_ FLC2 SG_ 1543 RegionCode 30000;
BA_REL_ "GenSigFirstTimeoutTime" BU_SG_REL_ FLC2 SG_ 1543 VIN_DACU_Byte00 65000;
BA_REL_ "GenSigTimeoutTime" BU_SG_REL_ FLC2 SG_ 1543 VIN_DACU_Byte00 30000;
BA_REL_ "GenSigFirstTimeoutTime" BU_SG_REL_ FLC2 SG_ 1543 VIN_DACU_Byte07 65000;
BA_REL_ "GenSigTimeoutTime" BU_SG_REL_ FLC2 SG_ 1543 VIN_DACU_Byte07 30000;
BA_REL_ "GenSigFirstTimeoutTime" BU_SG_REL_ FLC2 SG_ 1543 VIN_DACU_Byte05 65000;
BA_REL_ "GenSigTimeoutTime" BU_SG_REL_ FLC2 SG_ 1543 VIN_DACU_Byte05 30000;
BA_REL_ "GenSigFirstTimeoutTime" BU_SG_REL_ FLC2 SG_ 1265 VideoOutConfFLC_StreamActivation 3000;
BA_REL_ "GenSigTimeoutTime" BU_SG_REL_ FLC2 SG_ 1265 VideoOutConfFLC_StreamActivation 600;
BA_REL_ "GenSigFirstTimeoutTime" BU_SG_REL_ FLC2 SG_ 1265 MainBeamRequest_status 3000;
BA_REL_ "GenSigTimeoutTime" BU_SG_REL_ FLC2 SG_ 1265 MainBeamRequest_status 600;
BA_REL_ "GenSigFirstTimeoutTime" BU_SG_REL_ FLC2 SG_ 1265 HoursUTC 3000;
BA_REL_ "GenSigTimeoutTime" BU_SG_REL_ FLC2 SG_ 1265 HoursUTC 600;
BA_REL_ "GenSigFirstTimeoutTime" BU_SG_REL_ FLC2 SG_ 1265 YearUTC 3000;
BA_REL_ "GenSigTimeoutTime" BU_SG_REL_ FLC2 SG_ 1265 YearUTC 600;
BA_REL_ "GenSigFirstTimeoutTime" BU_SG_REL_ FLC2 SG_ 1265 TimeSynchStat_DACU 3000;
BA_REL_ "GenSigTimeoutTime" BU_SG_REL_ FLC2 SG_ 1265 TimeSynchStat_DACU 600;
BA_REL_ "GenSigFirstTimeoutTime" BU_SG_REL_ FLC2 SG_ 1265 MinutesUTC 3000;
BA_REL_ "GenSigTimeoutTime" BU_SG_REL_ FLC2 SG_ 1265 MinutesUTC 600;
BA_REL_ "GenSigFirstTimeoutTime" BU_SG_REL_ FLC2 SG_ 1265 TachographLocalHourOffset 3000;
BA_REL_ "GenSigTimeoutTime" BU_SG_REL_ FLC2 SG_ 1265 TachographLocalHourOffset 600;
BA_REL_ "GenSigFirstTimeoutTime" BU_SG_REL_ FLC2 SG_ 1265 CameraLoggingTrigger 3000;
BA_REL_ "GenSigTimeoutTime" BU_SG_REL_ FLC2 SG_ 1265 CameraLoggingTrigger 600;
BA_REL_ "GenSigFirstTimeoutTime" BU_SG_REL_ FLC2 SG_ 1265 DriverRetarderRequest 3000;
BA_REL_ "GenSigTimeoutTime" BU_SG_REL_ FLC2 SG_ 1265 DriverRetarderRequest 600;
BA_REL_ "GenSigFirstTimeoutTime" BU_SG_REL_ FLC2 SG_ 1265 LaneChangeStatus 3000;
BA_REL_ "GenSigTimeoutTime" BU_SG_REL_ FLC2 SG_ 1265 LaneChangeStatus 600;
BA_REL_ "GenSigFirstTimeoutTime" BU_SG_REL_ FLC2 SG_ 1265 FogLight_Front_cmd 3000;
BA_REL_ "GenSigTimeoutTime" BU_SG_REL_ FLC2 SG_ 1265 FogLight_Front_cmd 600;
BA_REL_ "GenSigFirstTimeoutTime" BU_SG_REL_ FLC2 SG_ 1265 TrailerConnected 3000;
BA_REL_ "GenSigTimeoutTime" BU_SG_REL_ FLC2 SG_ 1265 TrailerConnected 600;
BA_REL_ "GenSigFirstTimeoutTime" BU_SG_REL_ FLC2 SG_ 1265 MonthUTC 3000;
BA_REL_ "GenSigTimeoutTime" BU_SG_REL_ FLC2 SG_ 1265 MonthUTC 600;
BA_REL_ "GenSigFirstTimeoutTime" BU_SG_REL_ FLC2 SG_ 1265 AmbientAirTemperature 3000;
BA_REL_ "GenSigTimeoutTime" BU_SG_REL_ FLC2 SG_ 1265 AmbientAirTemperature 600;
BA_REL_ "GenSigFirstTimeoutTime" BU_SG_REL_ FLC2 SG_ 1265 SecondsUTC 3000;
BA_REL_ "GenSigTimeoutTime" BU_SG_REL_ FLC2 SG_ 1265 SecondsUTC 600;
BA_REL_ "GenSigFirstTimeoutTime" BU_SG_REL_ FLC2 SG_ 1265 DayUTC 3000;
BA_REL_ "GenSigTimeoutTime" BU_SG_REL_ FLC2 SG_ 1265 DayUTC 600;
BA_REL_ "GenSigFirstTimeoutTime" BU_SG_REL_ FLC2 SG_ 1265 VideoOutConfFLC_Framerate 3000;
BA_REL_ "GenSigTimeoutTime" BU_SG_REL_ FLC2 SG_ 1265 VideoOutConfFLC_Framerate 600;
BA_REL_ "GenSigFirstTimeoutTime" BU_SG_REL_ FLC2 SG_ 1265 TotalVehicleDistanceHighRes 3000;
BA_REL_ "GenSigTimeoutTime" BU_SG_REL_ FLC2 SG_ 1265 TotalVehicleDistanceHighRes 600;
BA_REL_ "GenSigFirstTimeoutTime" BU_SG_REL_ FLC2 SG_ 1265 WiperModeStatus 3000;
BA_REL_ "GenSigTimeoutTime" BU_SG_REL_ FLC2 SG_ 1265 WiperModeStatus 600;
BA_REL_ "GenSigFirstTimeoutTime" BU_SG_REL_ FLC2 SG_ 1265 TachographLocalMinuteOffset 3000;
BA_REL_ "GenSigTimeoutTime" BU_SG_REL_ FLC2 SG_ 1265 TachographLocalMinuteOffset 600;
BA_REL_ "GenSigFirstTimeoutTime" BU_SG_REL_ FLC2 SG_ 1265 FLCPowerDemand 3000;
BA_REL_ "GenSigTimeoutTime" BU_SG_REL_ FLC2 SG_ 1265 FLCPowerDemand 600;
BA_REL_ "GenSigFirstTimeoutTime" BU_SG_REL_ FLC2 SG_ 1552 DACUSwVersion_Substring4 60000;
BA_REL_ "GenSigTimeoutTime" BU_SG_REL_ FLC2 SG_ 1552 DACUSwVersion_Substring4 60000;
BA_REL_ "GenSigFirstTimeoutTime" BU_SG_REL_ FLC2 SG_ 1552 DACUSwVersion_Substring5 60000;
BA_REL_ "GenSigTimeoutTime" BU_SG_REL_ FLC2 SG_ 1552 DACUSwVersion_Substring5 60000;
BA_REL_ "GenSigFirstTimeoutTime" BU_SG_REL_ FLC2 SG_ 1552 DACUSwVersion_Substring2 60000;
BA_REL_ "GenSigTimeoutTime" BU_SG_REL_ FLC2 SG_ 1552 DACUSwVersion_Substring2 60000;
BA_REL_ "GenSigFirstTimeoutTime" BU_SG_REL_ FLC2 SG_ 1552 DACUSwVersion_Substring7 60000;
BA_REL_ "GenSigTimeoutTime" BU_SG_REL_ FLC2 SG_ 1552 DACUSwVersion_Substring7 60000;
BA_REL_ "GenSigFirstTimeoutTime" BU_SG_REL_ FLC2 SG_ 1552 DACUSwVersion_Substring6 60000;
BA_REL_ "GenSigTimeoutTime" BU_SG_REL_ FLC2 SG_ 1552 DACUSwVersion_Substring6 60000;
BA_REL_ "GenSigFirstTimeoutTime" BU_SG_REL_ FLC2 SG_ 1552 DACUSwVersion_Substring3 60000;
BA_REL_ "GenSigTimeoutTime" BU_SG_REL_ FLC2 SG_ 1552 DACUSwVersion_Substring3 60000;
BA_REL_ "GenSigFirstTimeoutTime" BU_SG_REL_ FLC2 SG_ 1552 DACUSwVersion_Substring1 60000;
BA_REL_ "GenSigTimeoutTime" BU_SG_REL_ FLC2 SG_ 1552 DACUSwVersion_Substring1 60000;
BA_REL_ "GenSigFirstTimeoutTime" BU_SG_REL_ FLC2 SG_ 1552 DACUSwVersion_Substring0 60000;
BA_REL_ "GenSigTimeoutTime" BU_SG_REL_ FLC2 SG_ 1552 DACUSwVersion_Substring0 60000;
VAL_ 788 FLCObject04_TurnIndication 7 "TurnIndication_NotAvailable" 6 "TurnIndication_Error" 5 "TurnIndication_Spare" 4 "TurnIndication_DirectionIndicatorBoth" 3 "TurnIndication_DirectionIndicatorRight" 2 "TurnIndication_DirectionIndicatorLeft" 1 "TurnIndication_NoDirectionIndicator" 0 "TurnIndication_Unknown" ;
VAL_ 788 FLCObject04_ObjClass 15 "ObjClassSideS_NotAvailable" 14 "ObjClassSideS_Error" 13 "ObjClassSideS_Spare4" 12 "ObjClassSideS_Spare3" 11 "ObjClassSideS_Motorcycle" 10 "ObjClassSideS_Bicycle" 9 "ObjClassSideS_UnidentifiedMovableObject" 8 "ObjClassSideS_UnidentifiedVRU" 7 "ObjClassSideS_UnidentifiedVehicle" 6 "ObjClassSideS_StaticObject" 5 "ObjClassSideS_Pedestrian" 4 "ObjClassSideS_2Wheeler" 3 "ObjClassSideS_HeavyVehicle" 2 "ObjClassSideS_Car" 1 "ObjClassSideS_Obstacle" 0 "ObjClassSideS_Undetermined" ;
VAL_ 788 FLCObject04_ObjDynClass 3 "ObjDynClass_Error" 2 "ObjDynClass_Movable" 1 "ObjDynClass_Stationary" 0 "ObjDynClass_Reserved" ;
VAL_ 788 FLCObject04_TrackStatus 7 "TrackStatus_NotAvailable" 6 "TrackStatus_Error" 5 "TrackStatus_Spare3" 4 "TrackStatus_Spare2" 3 "TrackStatus_Spare1" 2 "TrackStatus_Invalid" 1 "TrackStatus_Predicted" 0 "TrackStatus_Tracked" ;
VAL_ 788 FLCObject04_BrakeLight 7 "BrakeLight_NotAvailable" 6 "BrakeLight_Error" 5 "BrakeLight_Spare" 4 "BrakeLight_BrakeLightThree" 3 "BrakeLight_BrakeLightTwo" 2 "BrakeLight_BrakeLightOne" 1 "BrakeLight_NoBrakeLight" 0 "BrakeLight_BrakeLightUnknown" ;
VAL_ 788 FLCObject04_TargetToLine 7 "TargetToLine_NotAvailable" 6 "TargetToLine_Error" 5 "TargetToLine_Unknown" 4 "TargetToLine_OnTheLeftEgoLine" 3 "TargetToLine_OnTheRightEgoLine" 2 "TargetToLine_BetweenRightAndLeftEgoLine" 1 "TargetToLine_LeftSideOfTheLeftEgoLine" 0 "TargetToLine_RightSideOfTheRightEgoLine" ;
VAL_ 788 FLCObject04_ReliabilityConf 7 "ReliabilityConf_NotAvailable" 6 "ReliabilityConf_Error" 5 "ReliabilityConf_Spare2" 4 "ReliabilityConf_Spare1" 3 "ReliabilityConf_Restricted" 2 "ReliabilityConf_ASIL_B" 1 "ReliabilityConf_CNNConfirmed_ObjectShape" 0 "ReliabilityConf_ConfirmedbyGenericStream" ;
VAL_ 787 FLCObject03_TrackStatus 7 "TrackStatus_NotAvailable" 6 "TrackStatus_Error" 5 "TrackStatus_Spare3" 4 "TrackStatus_Spare2" 3 "TrackStatus_Spare1" 2 "TrackStatus_Invalid" 1 "TrackStatus_Predicted" 0 "TrackStatus_Tracked" ;
VAL_ 787 FLCObject03_TargetToLine 7 "TargetToLine_NotAvailable" 6 "TargetToLine_Error" 5 "TargetToLine_Unknown" 4 "TargetToLine_OnTheLeftEgoLine" 3 "TargetToLine_OnTheRightEgoLine" 2 "TargetToLine_BetweenRightAndLeftEgoLine" 1 "TargetToLine_LeftSideOfTheLeftEgoLine" 0 "TargetToLine_RightSideOfTheRightEgoLine" ;
VAL_ 787 FLCObject03_ObjClass 15 "ObjClassSideS_NotAvailable" 14 "ObjClassSideS_Error" 13 "ObjClassSideS_Spare4" 12 "ObjClassSideS_Spare3" 11 "ObjClassSideS_Motorcycle" 10 "ObjClassSideS_Bicycle" 9 "ObjClassSideS_UnidentifiedMovableObject" 8 "ObjClassSideS_UnidentifiedVRU" 7 "ObjClassSideS_UnidentifiedVehicle" 6 "ObjClassSideS_StaticObject" 5 "ObjClassSideS_Pedestrian" 4 "ObjClassSideS_2Wheeler" 3 "ObjClassSideS_HeavyVehicle" 2 "ObjClassSideS_Car" 1 "ObjClassSideS_Obstacle" 0 "ObjClassSideS_Undetermined" ;
VAL_ 787 FLCObject03_ObjDynClass 3 "ObjDynClass_Error" 2 "ObjDynClass_Movable" 1 "ObjDynClass_Stationary" 0 "ObjDynClass_Reserved" ;
VAL_ 787 FLCObject03_ReliabilityConf 7 "ReliabilityConf_NotAvailable" 6 "ReliabilityConf_Error" 5 "ReliabilityConf_Spare2" 4 "ReliabilityConf_Spare1" 3 "ReliabilityConf_Restricted" 2 "ReliabilityConf_ASIL_B" 1 "ReliabilityConf_CNNConfirmed_ObjectShape" 0 "ReliabilityConf_ConfirmedbyGenericStream" ;
VAL_ 787 FLCObject03_TurnIndication 7 "TurnIndication_NotAvailable" 6 "TurnIndication_Error" 5 "TurnIndication_Spare" 4 "TurnIndication_DirectionIndicatorBoth" 3 "TurnIndication_DirectionIndicatorRight" 2 "TurnIndication_DirectionIndicatorLeft" 1 "TurnIndication_NoDirectionIndicator" 0 "TurnIndication_Unknown" ;
VAL_ 787 FLCObject03_BrakeLight 7 "BrakeLight_NotAvailable" 6 "BrakeLight_Error" 5 "BrakeLight_Spare" 4 "BrakeLight_BrakeLightThree" 3 "BrakeLight_BrakeLightTwo" 2 "BrakeLight_BrakeLightOne" 1 "BrakeLight_NoBrakeLight" 0 "BrakeLight_BrakeLightUnknown" ;
VAL_ 786 FLCObject02_TrackStatus 7 "TrackStatus_NotAvailable" 6 "TrackStatus_Error" 5 "TrackStatus_Spare3" 4 "TrackStatus_Spare2" 3 "TrackStatus_Spare1" 2 "TrackStatus_Invalid" 1 "TrackStatus_Predicted" 0 "TrackStatus_Tracked" ;
VAL_ 786 FLCObject02_ObjDynClass 3 "ObjDynClass_Error" 2 "ObjDynClass_Movable" 1 "ObjDynClass_Stationary" 0 "ObjDynClass_Reserved" ;
VAL_ 786 FLCObject02_ReliabilityConf 7 "ReliabilityConf_NotAvailable" 6 "ReliabilityConf_Error" 5 "ReliabilityConf_Spare2" 4 "ReliabilityConf_Spare1" 3 "ReliabilityConf_Restricted" 2 "ReliabilityConf_ASIL_B" 1 "ReliabilityConf_CNNConfirmed_ObjectShape" 0 "ReliabilityConf_ConfirmedbyGenericStream" ;
VAL_ 786 FLCObject02_TurnIndication 7 "TurnIndication_NotAvailable" 6 "TurnIndication_Error" 5 "TurnIndication_Spare" 4 "TurnIndication_DirectionIndicatorBoth" 3 "TurnIndication_DirectionIndicatorRight" 2 "TurnIndication_DirectionIndicatorLeft" 1 "TurnIndication_NoDirectionIndicator" 0 "TurnIndication_Unknown" ;
VAL_ 786 FLCObject02_ObjClass 15 "ObjClassSideS_NotAvailable" 14 "ObjClassSideS_Error" 13 "ObjClassSideS_Spare4" 12 "ObjClassSideS_Spare3" 11 "ObjClassSideS_Motorcycle" 10 "ObjClassSideS_Bicycle" 9 "ObjClassSideS_UnidentifiedMovableObject" 8 "ObjClassSideS_UnidentifiedVRU" 7 "ObjClassSideS_UnidentifiedVehicle" 6 "ObjClassSideS_StaticObject" 5 "ObjClassSideS_Pedestrian" 4 "ObjClassSideS_2Wheeler" 3 "ObjClassSideS_HeavyVehicle" 2 "ObjClassSideS_Car" 1 "ObjClassSideS_Obstacle" 0 "ObjClassSideS_Undetermined" ;
VAL_ 786 FLCObject02_BrakeLight 7 "BrakeLight_NotAvailable" 6 "BrakeLight_Error" 5 "BrakeLight_Spare" 4 "BrakeLight_BrakeLightThree" 3 "BrakeLight_BrakeLightTwo" 2 "BrakeLight_BrakeLightOne" 1 "BrakeLight_NoBrakeLight" 0 "BrakeLight_BrakeLightUnknown" ;
VAL_ 786 FLCObject02_TargetToLine 7 "TargetToLine_NotAvailable" 6 "TargetToLine_Error" 5 "TargetToLine_Unknown" 4 "TargetToLine_OnTheLeftEgoLine" 3 "TargetToLine_OnTheRightEgoLine" 2 "TargetToLine_BetweenRightAndLeftEgoLine" 1 "TargetToLine_LeftSideOfTheLeftEgoLine" 0 "TargetToLine_RightSideOfTheRightEgoLine" ;
VAL_ 785 FLCObject01_ObjDynClass 3 "ObjDynClass_Error" 2 "ObjDynClass_Movable" 1 "ObjDynClass_Stationary" 0 "ObjDynClass_Reserved" ;
VAL_ 785 FLCObject01_ReliabilityConf 7 "ReliabilityConf_NotAvailable" 6 "ReliabilityConf_Error" 5 "ReliabilityConf_Spare2" 4 "ReliabilityConf_Spare1" 3 "ReliabilityConf_Restricted" 2 "ReliabilityConf_ASIL_B" 1 "ReliabilityConf_CNNConfirmed_ObjectShape" 0 "ReliabilityConf_ConfirmedbyGenericStream" ;
VAL_ 785 FLCObject01_BrakeLight 7 "BrakeLight_NotAvailable" 6 "BrakeLight_Error" 5 "BrakeLight_Spare" 4 "BrakeLight_BrakeLightThree" 3 "BrakeLight_BrakeLightTwo" 2 "BrakeLight_BrakeLightOne" 1 "BrakeLight_NoBrakeLight" 0 "BrakeLight_BrakeLightUnknown" ;
VAL_ 785 FLCObject01_ObjClass 15 "ObjClassSideS_NotAvailable" 14 "ObjClassSideS_Error" 13 "ObjClassSideS_Spare4" 12 "ObjClassSideS_Spare3" 11 "ObjClassSideS_Motorcycle" 10 "ObjClassSideS_Bicycle" 9 "ObjClassSideS_UnidentifiedMovableObject" 8 "ObjClassSideS_UnidentifiedVRU" 7 "ObjClassSideS_UnidentifiedVehicle" 6 "ObjClassSideS_StaticObject" 5 "ObjClassSideS_Pedestrian" 4 "ObjClassSideS_2Wheeler" 3 "ObjClassSideS_HeavyVehicle" 2 "ObjClassSideS_Car" 1 "ObjClassSideS_Obstacle" 0 "ObjClassSideS_Undetermined" ;
VAL_ 785 FLCObject01_TrackStatus 7 "TrackStatus_NotAvailable" 6 "TrackStatus_Error" 5 "TrackStatus_Spare3" 4 "TrackStatus_Spare2" 3 "TrackStatus_Spare1" 2 "TrackStatus_Invalid" 1 "TrackStatus_Predicted" 0 "TrackStatus_Tracked" ;
VAL_ 785 FLCObject01_TargetToLine 7 "TargetToLine_NotAvailable" 6 "TargetToLine_Error" 5 "TargetToLine_Unknown" 4 "TargetToLine_OnTheLeftEgoLine" 3 "TargetToLine_OnTheRightEgoLine" 2 "TargetToLine_BetweenRightAndLeftEgoLine" 1 "TargetToLine_LeftSideOfTheLeftEgoLine" 0 "TargetToLine_RightSideOfTheRightEgoLine" ;
VAL_ 785 FLCObject01_TurnIndication 7 "TurnIndication_NotAvailable" 6 "TurnIndication_Error" 5 "TurnIndication_Spare" 4 "TurnIndication_DirectionIndicatorBoth" 3 "TurnIndication_DirectionIndicatorRight" 2 "TurnIndication_DirectionIndicatorLeft" 1 "TurnIndication_NoDirectionIndicator" 0 "TurnIndication_Unknown" ;
VAL_ 784 FLCObject00_BrakeLight 7 "BrakeLight_NotAvailable" 6 "BrakeLight_Error" 5 "BrakeLight_Spare" 4 "BrakeLight_BrakeLightThree" 3 "BrakeLight_BrakeLightTwo" 2 "BrakeLight_BrakeLightOne" 1 "BrakeLight_NoBrakeLight" 0 "BrakeLight_BrakeLightUnknown" ;
VAL_ 784 FLCObject00_TrackStatus 7 "TrackStatus_NotAvailable" 6 "TrackStatus_Error" 5 "TrackStatus_Spare3" 4 "TrackStatus_Spare2" 3 "TrackStatus_Spare1" 2 "TrackStatus_Invalid" 1 "TrackStatus_Predicted" 0 "TrackStatus_Tracked" ;
VAL_ 784 FLCObject00_ObjClass 15 "ObjClassSideS_NotAvailable" 14 "ObjClassSideS_Error" 13 "ObjClassSideS_Spare4" 12 "ObjClassSideS_Spare3" 11 "ObjClassSideS_Motorcycle" 10 "ObjClassSideS_Bicycle" 9 "ObjClassSideS_UnidentifiedMovableObject" 8 "ObjClassSideS_UnidentifiedVRU" 7 "ObjClassSideS_UnidentifiedVehicle" 6 "ObjClassSideS_StaticObject" 5 "ObjClassSideS_Pedestrian" 4 "ObjClassSideS_2Wheeler" 3 "ObjClassSideS_HeavyVehicle" 2 "ObjClassSideS_Car" 1 "ObjClassSideS_Obstacle" 0 "ObjClassSideS_Undetermined" ;
VAL_ 784 FLCObject00_ReliabilityConf 7 "ReliabilityConf_NotAvailable" 6 "ReliabilityConf_Error" 5 "ReliabilityConf_Spare2" 4 "ReliabilityConf_Spare1" 3 "ReliabilityConf_Restricted" 2 "ReliabilityConf_ASIL_B" 1 "ReliabilityConf_CNNConfirmed_ObjectShape" 0 "ReliabilityConf_ConfirmedbyGenericStream" ;
VAL_ 784 FLCObject00_ObjDynClass 3 "ObjDynClass_Error" 2 "ObjDynClass_Movable" 1 "ObjDynClass_Stationary" 0 "ObjDynClass_Reserved" ;
VAL_ 784 FLCObject00_TargetToLine 7 "TargetToLine_NotAvailable" 6 "TargetToLine_Error" 5 "TargetToLine_Unknown" 4 "TargetToLine_OnTheLeftEgoLine" 3 "TargetToLine_OnTheRightEgoLine" 2 "TargetToLine_BetweenRightAndLeftEgoLine" 1 "TargetToLine_LeftSideOfTheLeftEgoLine" 0 "TargetToLine_RightSideOfTheRightEgoLine" ;
VAL_ 784 FLCObject00_TurnIndication 7 "TurnIndication_NotAvailable" 6 "TurnIndication_Error" 5 "TurnIndication_Spare" 4 "TurnIndication_DirectionIndicatorBoth" 3 "TurnIndication_DirectionIndicatorRight" 2 "TurnIndication_DirectionIndicatorLeft" 1 "TurnIndication_NoDirectionIndicator" 0 "TurnIndication_Unknown" ;
VAL_ 854 GPSData_AntennaStat 7 "GPS_Antenna_status_NA" 6 "GPS_Antenna_status_ErrorIndicator" 5 "GPS_Antenna_status_SpareValue_01" 4 "GPS_Antenna_status_SpareValue" 3 "GPS_Antenna_status_AntennaStatusUnknown" 2 "GPS_Antenna_status_AntennaInit" 1 "GPS_Antenna_status_AntennaDisconnected" 0 "GPS_Antenna_status_AntennaStatusOK" ;
VAL_ 275 EgoMotionXYplane_LongMotionDir 7 "LongMotionDirection_NotAvailable" 6 "LongMotionDirection_Error" 5 "LongMotionDirection_Spare3" 4 "LongMotionDirection_Spare2" 3 "LongMotionDirection_Undetermined" 2 "LongMotionDirection_Backward" 1 "LongMotionDirection_Forward" 0 "LongMotionDirection_Stationary" ;
VAL_ 275 EgoMotionXYplane_LongMotDirConf 15 "LongMotionDirConf_NotAvailable" 14 "LongMotionDirConf_Error" 13 "LongMotionDirConf_Spare5" 12 "LongMotionDirConf_Spare4" 11 "LongMotionDirConf_Spare3" 10 "LongMotionDirConf_Spare2" 9 "LongMotionDirConf_Spare1" 8 "LongMotionDirConf_MovingVeryHighConfidence" 7 "LongMotionDirConf_MovingHighConfidence" 6 "LongMotionDirConf_MovingMediumConfidence" 5 "LongMotionDirConf_MovingLowConfidence" 4 "LongMotionDirConf_StationaryLowConfidence" 3 "LongMotionDirConf_StationaryMediumConfidence" 2 "LongMotionDirConf_StationaryHighConfidence" 1 "LongMotionDirConf_StationaryVeryHighConfidence" 0 "LongMotionDirConf_StationaryVeryVeryHighConfidence" ;
VAL_ 275 VehicleMode 15 "VehicleMode_NotAvailable" 14 "VehicleMode_Error" 13 "VehicleMode_Spare_7" 12 "VehicleMode_Spare_6" 11 "VehicleMode_Spare_5" 10 "VehicleMode_Spare_4" 9 "VehicleMode_Spare_3" 8 "VehicleMode_Spare_2" 7 "VehicleMode_Spare_1" 6 "VehicleMode_Running" 5 "VehicleMode_Cranking" 4 "VehicleMode_PreRunning" 3 "VehicleMode_Accessory" 2 "VehicleMode_Living" 1 "VehicleMode_Parked" 0 "VehicleMode_Hibernate" ;
VAL_ 277 EgoMotionRaw_ROPEngineActive 3 "PassiveActive2_DontCareTakeNoAction" 2 "PassiveActive2_Reserved" 1 "PassiveActive2_Active" 0 "PassiveActive2_PassiveButInstalled" ;
VAL_ 277 EgoMotionRaw_AccKckDwn 3 "PassiveActive_NotAvailable" 2 "PassiveActive_Error" 1 "PassiveActive_Active" 0 "PassiveActive_Passive" ;
VAL_ 277 EgoMotionRaw_ABSActive 3 "AntiLockBrakingActive_NotAvailable" 2 "AntiLockBrakingActive_Reserved" 1 "AntiLockBrakingActive_ABSActive" 0 "AntiLockBrakingActive_ABSPassiveButInstalled" ;
VAL_ 277 EgoMotionRaw_YCEngineActive 3 "PassiveActive2_DontCareTakeNoAction" 2 "PassiveActive2_Reserved" 1 "PassiveActive2_Active" 0 "PassiveActive2_PassiveButInstalled" ;
VAL_ 277 EgoMotionRaw_ASRBrakeA 3 "PassiveActive2_DontCareTakeNoAction" 2 "PassiveActive2_Reserved" 1 "PassiveActive2_Active" 0 "PassiveActive2_PassiveButInstalled" ;
VAL_ 277 EgoMotionRaw_VDCFullyOperational 3 "FullyOperational_NotAvailable" 2 "FullyOperational_Reserved" 1 "FullyOperational_FullyOperational" 0 "FullyOperational_NotFullyOperational" ;
VAL_ 277 EgoMotionRaw_TrailerConStatus 15 "TrailerConStatus_NotAvailableOrNotInstalled" 14 "TrailerConStatus_ErrorIndicator" 13 "TrailerConStatus_Unknown" 12 "TrailerConStatus_AtLeastOneSegmentConnectedNoAbs" 11 "TrailerConStatus_AtLeastOneSegmentConnected" 10 "TrailerConStatus_FiveOrMoreSegmentsConnectedNoAbs" 9 "TrailerConStatus_FourTrailerSegmentsConnectedNoAbs" 8 "TrailerConStatus_ThreeTrailerSegmentsConnectedNoAbs" 7 "TrailerConStatus_TwoTrailerSegmentsConnectedNoAbs" 6 "TrailerConStatus_OneTrailerSegmentConnectedNoAbs" 5 "TrailerConStatus_FiveOrMoreSegmentsConnected" 4 "TrailerConStatus_FourTrailerSegmentsConnected" 3 "TrailerConStatus_ThreeTrailerSegmentsConnected" 2 "TrailerConStatus_TwoTrailerSegmentsConnected" 1 "TrailerConStatus_OneTrailerSegmentConnected" 0 "TrailerConStatus_NoTrailerConnected" ;
VAL_ 277 EgoMotionRaw_YCBrakeActive 3 "PassiveActive2_DontCareTakeNoAction" 2 "PassiveActive2_Reserved" 1 "PassiveActive2_Active" 0 "PassiveActive2_PassiveButInstalled" ;
VAL_ 277 EgoMotionRaw_ASREngineA 3 "PassiveActive2_DontCareTakeNoAction" 2 "PassiveActive2_Reserved" 1 "PassiveActive2_Active" 0 "PassiveActive2_PassiveButInstalled" ;
VAL_ 277 EgoMotionRaw_ROPBrakeActive 3 "PassiveActive2_DontCareTakeNoAction" 2 "PassiveActive2_Reserved" 1 "PassiveActive2_Active" 0 "PassiveActive2_PassiveButInstalled" ;
VAL_ 277 EgoMotionRaw_ABSOp 3 "FullyOperational_NotAvailable" 2 "FullyOperational_Reserved" 1 "FullyOperational_FullyOperational" 0 "FullyOperational_NotFullyOperational" ;
VAL_ 1543 RegionCode 7 "RegionCode_NotAvailable" 6 "RegionCode_Error" 5 "RegionCode_Spare2" 4 "RegionCode_Spare1" 3 "RegionCode_Asia" 2 "RegionCode_NorthAmerica" 1 "RegionCode_Europe" 0 "RegionCode_Unknown" ;
VAL_ 1265 VideoOutConfFLC_StreamActivation 3 "OffOn_NotAvailable" 2 "OffOn_Error" 1 "OffOn_On" 0 "OffOn_Off" ;
VAL_ 1265 MainBeamRequest_status 3 "OffOnGlareFree_NotAvailable" 2 "OffOnGlareFree_GlareFree" 1 "OffOnGlareFree_On" 0 "OffOnGlareFree_Off" ;
VAL_ 1265 CameraLoggingTrigger 7 "SensorLoggingTrigger_NotAvailable" 6 "SensorLoggingTrigger_Error" 5 "SensorLoggingTrigger_Trigger5" 4 "SensorLoggingTrigger_Trigger4" 3 "SensorLoggingTrigger_Trigger3" 2 "SensorLoggingTrigger_Trigger2" 1 "SensorLoggingTrigger_Trigger1" 0 "SensorLoggingTrigger_NoTrigger" ;
VAL_ 1265 DriverRetarderRequest 7 "DriverRetarderRequest_NotAvailable" 6 "DriverRetarderRequest_Error" 5 "DriverRetarderRequest_Level5" 4 "DriverRetarderRequest_Level4" 3 "DriverRetarderRequest_Level3" 2 "DriverRetarderRequest_Level2" 1 "DriverRetarderRequest_Level1" 0 "DriverRetarderRequest_NoRequest" ;
VAL_ 1265 LaneChangeStatus 15 "LaneChangeStatus_NotAvailable" 14 "LaneChangeStatus_Error" 13 "LaneChangeStatus_Spare11" 12 "LaneChangeStatus_Spare10" 11 "LaneChangeStatus_Spare9" 10 "LaneChangeStatus_Spare8" 9 "LaneChangeStatus_Spare7" 8 "LaneChangeStatus_Spare6" 7 "LaneChangeStatus_Spare5" 6 "LaneChangeStatus_Spare4" 5 "LaneChangeStatus_Spare3" 4 "LaneChangeStatus_Spare2" 3 "LaneChangeStatus_Spare1" 2 "LaneChangeStatus_RightLaneChangeIntention" 1 "LaneChangeStatus_LeftLaneChangeIntention" 0 "LaneChangeStatus_NotActive" ;
VAL_ 1265 FogLight_Front_cmd 3 "InactiveActive_NotAvailable" 2 "InactiveActive_Error" 1 "InactiveActive_Active" 0 "InactiveActive_Inactive" ;
VAL_ 1265 TrailerConnected 3 "NoYes_NotAvailable" 2 "NoYes_Error" 1 "NoYes_Yes" 0 "NoYes_No" ;
VAL_ 1265 VideoOutConfFLC_Framerate 15 "Framerate_NotAvailable" 14 "Framerate_Error" 13 "Framerate_Spare10" 12 "Framerate_Spare9" 11 "Framerate_Spare8" 10 "Framerate_Spare7" 9 "Framerate_Spare6" 8 "Framerate_Spare5" 7 "Framerate_Spare4" 6 "Framerate_Spare3" 5 "Framerate_Spare2" 4 "Framerate_Spare1" 3 "Framerate_1" 2 "Framerate_5" 1 "Framerate_7P5" 0 "Framerate_15" ;
VAL_ 1265 WiperModeStatus 7 "WiperModeStatus_NotAvailable" 6 "WiperModeStatus_ErrorIndicator" 5 "WiperModeStatus_Spare02" 4 "WiperModeStatus_Spare01" 3 "WiperModeStatus_Spare" 2 "WiperModeStatus_HighSpeedWiping" 1 "WiperModeStatus_LowSpeedWiping" 0 "WiperModeStatus_WiperOff" ;
VAL_ 1265 FLCPowerDemand 7 "PowerDemand_NotAvailable" 6 "PowerDemand_Error" 5 "PowerDemand_Spare3" 4 "PowerDemand_Spare2" 3 "PowerDemand_EmergencyShutDownDemand" 2 "PowerDemand_PowerDown_Rqst" 1 "PowerDemand_PowerUp_Rqst" 0 "PowerDemand_Spare1" ;
SIG_GROUP_ 788 FLCObject04_sg 1 : FLCObject04_LatVel FLCObject04_LatVelVar FLCObject04_CoastIndex FLCObject04_LifeTime FLCObject04_DistFarCorner FLCObject04_TurnIndication FLCObject04_AnglLeftCorner FLCObject04_CRC FLCObject04_LatPos FLCObject04_DstRightVar FLCObject04_Height FLCObject04_LongVel FLCObject04_ExistConf FLCObject04_DstFarVar FLCObject04_ObjClass FLCObject04_AngLeftVar FLCObject04_ScaleChange FLCObject04_AnglRightCorner FLCObject04_LongPosVar FLCObject04_LongAcc FLCObject04_ObjDynClass FLCObject04_Counter FLCObject04_ObjID FLCObject04_TrackStatus FLCObject04_AngRightVar FLCObject04_DistLeftCorner FLCObject04_Heading FLCObject04_BrakeLight FLCObject04_DistRightCorner FLCObject04_AnglFarCorner FLCObject04_AngFarVar FLCObject04_DstLeftVar FLCObject04_LatAcc FLCObject04_TargetToLine FLCObject04_LongVelVar FLCObject04_LatPosVar FLCObject04_TimeStamp FLCObject04_LongPos FLCObject04_ReliabilityConf FLCObject04_HeadingVar;
SIG_GROUP_ 787 FLCObject03_sg 1 : FLCObject03_Height FLCObject03_LatAcc FLCObject03_LatVelVar FLCObject03_TrackStatus FLCObject03_LifeTime FLCObject03_AnglFarCorner FLCObject03_LongAcc FLCObject03_Heading FLCObject03_AngFarVar FLCObject03_LongPosVar FLCObject03_LatPos FLCObject03_ScaleChange FLCObject03_LongVelVar FLCObject03_LongVel FLCObject03_DstFarVar FLCObject03_TargetToLine FLCObject03_CoastIndex FLCObject03_DstRightVar FLCObject03_ExistConf FLCObject03_LongPos FLCObject03_AnglRightCorner FLCObject03_LatVel FLCObject03_ObjClass FLCObject03_TimeStamp FLCObject03_ObjDynClass FLCObject03_CRC FLCObject03_AnglLeftCorner FLCObject03_ReliabilityConf FLCObject03_DistLeftCorner FLCObject03_DstLeftVar FLCObject03_DistFarCorner FLCObject03_TurnIndication FLCObject03_LatPosVar FLCObject03_DistRightCorner FLCObject03_ObjID FLCObject03_AngLeftVar FLCObject03_BrakeLight FLCObject03_HeadingVar FLCObject03_Counter FLCObject03_AngRightVar;
SIG_GROUP_ 786 FLCObject02_sg 1 : FLCObject02_ScaleChange FLCObject02_Height FLCObject02_AnglRightCorner FLCObject02_AnglFarCorner FLCObject02_DistRightCorner FLCObject02_LongAcc FLCObject02_AngRightVar FLCObject02_CRC FLCObject02_LatAcc FLCObject02_TrackStatus FLCObject02_Heading FLCObject02_AnglLeftCorner FLCObject02_LongVelVar FLCObject02_LatPos FLCObject02_LongPosVar FLCObject02_LatVelVar FLCObject02_LongVel FLCObject02_ObjDynClass FLCObject02_TimeStamp FLCObject02_DistFarCorner FLCObject02_DstFarVar FLCObject02_LifeTime FLCObject02_LatVel FLCObject02_ObjID FLCObject02_ExistConf FLCObject02_DstRightVar FLCObject02_ReliabilityConf FLCObject02_DistLeftCorner FLCObject02_HeadingVar FLCObject02_TurnIndication FLCObject02_ObjClass FLCObject02_LongPos FLCObject02_DstLeftVar FLCObject02_AngLeftVar FLCObject02_BrakeLight FLCObject02_LatPosVar FLCObject02_CoastIndex FLCObject02_Counter FLCObject02_TargetToLine FLCObject02_AngFarVar;
SIG_GROUP_ 785 FLCObject01_sg 1 : FLCObject01_TimeStamp FLCObject01_CRC FLCObject01_LongVelVar FLCObject01_ObjDynClass FLCObject01_ScaleChange FLCObject01_AnglRightCorner FLCObject01_ReliabilityConf FLCObject01_LongAcc FLCObject01_DistLeftCorner FLCObject01_BrakeLight FLCObject01_DstFarVar FLCObject01_LatVel FLCObject01_LatPos FLCObject01_LongPosVar FLCObject01_DstLeftVar FLCObject01_LatPosVar FLCObject01_ExistConf FLCObject01_Counter FLCObject01_ObjClass FLCObject01_LongVel FLCObject01_Height FLCObject01_LatVelVar FLCObject01_AnglFarCorner FLCObject01_Heading FLCObject01_LatAcc FLCObject01_LifeTime FLCObject01_HeadingVar FLCObject01_AngLeftVar FLCObject01_AngFarVar FLCObject01_CoastIndex FLCObject01_DistRightCorner FLCObject01_TrackStatus FLCObject01_LongPos FLCObject01_ObjID FLCObject01_DstRightVar FLCObject01_DistFarCorner FLCObject01_TargetToLine FLCObject01_TurnIndication FLCObject01_AngRightVar FLCObject01_AnglLeftCorner;
SIG_GROUP_ 784 FLCObject00_sg 1 : FLCObject00_LifeTime FLCObject00_BrakeLight FLCObject00_AnglLeftCorner FLCObject00_DistRightCorner FLCObject00_LatPos FLCObject00_TimeStamp FLCObject00_LatAcc FLCObject00_LatVel FLCObject00_ExistConf FLCObject00_AngRightVar FLCObject00_AnglRightCorner FLCObject00_LatPosVar FLCObject00_DistLeftCorner FLCObject00_CoastIndex FLCObject00_TrackStatus FLCObject00_ScaleChange FLCObject00_LatVelVar FLCObject00_HeadingVar FLCObject00_LongPosVar FLCObject00_DstLeftVar FLCObject00_ObjID FLCObject00_ObjClass FLCObject00_AnglFarCorner FLCObject00_DstFarVar FLCObject00_LongVel FLCObject00_LongPos FLCObject00_AngLeftVar FLCObject00_ReliabilityConf FLCObject00_Counter FLCObject00_ObjDynClass FLCObject00_TargetToLine FLCObject00_DstRightVar FLCObject00_TurnIndication FLCObject00_AngFarVar FLCObject00_Heading FLCObject00_DistFarCorner FLCObject00_LongAcc FLCObject00_Height FLCObject00_LongVelVar FLCObject00_CRC;
SIG_GROUP_ 1527 DiagFaultStat_FLC_sg 1 : DiagFaultStat_FLC_EcuAdr DiagFaultStat_FLC_FailTA DiagFaultStat_FLC_DtcIdA DiagFaultStat_FLC_FailTB DiagFaultStat_FLC_DtcIdB;
SIG_GROUP_ 257 DACUTimeSync_sg 1 : DACUTimeSync_CRC DACUTimeSync_SeqCnt DACUTimeSync_TimeDomain DACUTimeSync_Time DACUTimeSync_Type DACUTimeSync_UserByte;
SIG_GROUP_ 761 DACUTimeSyncOFS_sg 1 : DACUTimeSyncOFS_CRCOFS DACUTimeSyncOFS_SeqCnt DACUTimeSyncOFS_UserByte0 DACUTimeSyncOFS_TypeOFS DACUTimeSyncOFS_TimeDomain DACUTimeSyncOFS_OfsTimeSec;
SIG_GROUP_ 760 DACUTimeSyncOFNS_sg 1 : DACUTimeSyncOFNS_OfsTimeNsec DACUTimeSyncOFNS_SGW DACUTimeSyncOFNS_SeqCnt DACUTimeSyncOFNS_CRCOFNS DACUTimeSyncOFNS_TypeOFNS DACUTimeSyncOFNS_TimeDomain;
SIG_GROUP_ 281 ShadowArea_sg 1 : ShadowArea_LeftAgl03 ShadowArea_RightAgl02 ShadowArea_RightAgl01 ShadowArea_LeftAgl02 ShadowArea_Dist03 ShadowArea_Dist01 ShadowArea_LeftAgl01 ShadowArea_Dist02 ShadowArea_RightAgl03;
SIG_GROUP_ 854 GPSData_sg 1 : GPSData_Time GPSData_AntennaStat GPSData_Longitude GPSData_VehSpeed GPSData_Direction GPSData_Latitude GPSData_HDOP GPSData_Altitude;
SIG_GROUP_ 279 EgoPathPrediction_sg 1 : EgoPathPrediction_ConfCoeffA3 EgoPathPrediction_CurvatureRate EgoPathPrediction_DxEnd EgoPathPrediction_HeadingAngle EgoPathPrediction_ConfCoeffA1 EgoPathPrediction_ConfCoeffA0 EgoPathPrediction_ConfCoeffA2 EgoPathPrediction_Curvature;
SIG_GROUP_ 275 EgoMotionXYplane_sg 1 : EgoMotionXYplane_LongSpeedVar EgoMotionXYplane_LongAccVariance EgoMotionXYplane_LongMotionDir EgoMotionXYplane_Curvature EgoMotionXYplane_LongAcc EgoMotionXYplane_LatAccVariance EgoMotionXYplane_YawRateVariance EgoMotionXYplane_LongMotDirConf EgoMotionXYplane_YawRateComp EgoMotionXYplane_ReferencePointX EgoMotionXYplane_LateralSpeed EgoMotionXYplane_LateralAcc EgoMotionXYplane_CRC EgoMotionXYplane_LongSpeed EgoMotionXYplane_LatSpeedVar EgoMotionXYplane_LatencyEst EgoMotionXYplane_ChassisDynPitch EgoMotionXYplane_Counter EgoMotionXYplane_EffectiveWheelB;
SIG_GROUP_ 277 EgoMotionRaw_sg 1 : EgoMotionRaw_RelLvlRrAxleRight EgoMotionRaw_FrAxleLeftWSpeed EgoMotionRaw_GrossCombVehWeight EgoMotionRaw_FrontWheelAngle EgoMotionRaw_BrakePedalPosition EgoMotionRaw_SteeringWheelAngle EgoMotionRaw_SteeringWheelRatio EgoMotionRaw_FrAxleRightWSpeed EgoMotionRaw_ROPEngineActive EgoMotionRaw_AccKckDwn EgoMotionRaw_RelLvlFrAxleLeft EgoMotionRaw_ABSActive EgoMotionRaw_AccPedalPos EgoMotionRaw_YCEngineActive EgoMotionRaw_RAxleRightWSpeed EgoMotionRaw_ASRBrakeA EgoMotionRaw_RelLvlFrAxleRight EgoMotionRaw_VDCFullyOperational EgoMotionRaw_TrailerConStatus EgoMotionRaw_YCBrakeActive EgoMotionRaw_ASREngineA EgoMotionRaw_RelLvlRrAxleLeft EgoMotionRaw_Counter EgoMotionRaw_ROPBrakeActive EgoMotionRaw_CRC EgoMotionRaw_RAxleLeftWSpeed EgoMotionRaw_ABSOp;
SIG_GROUP_ 1543 CountryCodeLocal_sg 1 : CountryCodeLocal_Code CountryCodeLocal_Counter CountryCodeLocal_CRC;
SIG_GROUP_ 1543 VIN_DACU_sg 1 : VIN_DACU_Byte08 VIN_DACU_Byte01 VIN_DACU_Byte13 VIN_DACU_Byte06 VIN_DACU_Byte03 VIN_DACU_Byte15 VIN_DACU_Byte16 VIN_DACU_Byte09 VIN_DACU_Byte04 VIN_DACU_Byte02 VIN_DACU_Byte14 VIN_DACU_Byte12 VIN_DACU_Byte10 VIN_DACU_Byte11 VIN_DACU_Byte00 VIN_DACU_Byte07 VIN_DACU_Byte05;
SIG_GROUP_ 1265 VideoOutConfFLC_sg 1 : VideoOutConfFLC_StreamActivation VideoOutConfFLC_Framerate;
SIG_GROUP_ 1552 DACUSwVersion_sg 1 : DACUSwVersion_Substring4 DACUSwVersion_Substring5 DACUSwVersion_Substring2 DACUSwVersion_Substring7 DACUSwVersion_Substring6 DACUSwVersion_Substring3 DACUSwVersion_Substring1 DACUSwVersion_Substring0;
